VERSION ""

NS_ :

BS_:

BU_: DAS

BO_ 1337 DAS_info: 8 DAS
 SG_ DAS_infoIndex M : 0|8@1+ (1,0) [0|0] "" Vector__XXX
 SG_ DAS_infoBuildType m10 : 8|8@1+ (1,0) [0|0] "" Vector__XXX
 SG_ DAS_infoBuildConfigID m10 : 16|16@1+ (1,0) [0|0] "" Vector__XXX
 SG_ DAS_infoHardwareID m10 : 32|16@1+ (1,0) [0|0] "" Vector__XXX
 SG_ DAS_infoComponentID m10 : 48|16@1+ (1,0) [0|0] "" Vector__XXX
 SG_ DAS_infoPcbaID m11 : 16|8@1+ (1,0) [0|0] "" Vector__XXX
 SG_ DAS_infoAssemblyID m11 : 24|8@1+ (1,0) [0|255] "" Vector__XXX
 SG_ DAS_infoUsageID m11 : 32|16@1+ (1,0) [0|65535] "" Vector__XXX
 SG_ DAS_infoSubUsageID m11 : 48|16@1+ (1,0) [0|65535] "" Vector__XXX
 SG_ DAS_infoApplicationCRC m13 : 32|32@1+ (1,0) [0|0] "" Vector__XXX
 SG_ DAS_infoBootloaderSvnRevision m14 : 8|24@1+ (1,0) [0|0] "" Vector__XXX
 SG_ DAS_infoEyeQBootCRC m16 : 16|32@1+ (1,0) [0|0] "" Vector__XXX
 SG_ DAS_infoAppGitHashBytes m17 : 8|56@1+ (1,0) [0|0] "" Vector__XXX
 SG_ DAS_infoBootGitHashBytes m18 : 8|56@1+ (1,0) [0|0] "" Vector__XXX
 SG_ DAS_infoPlatformType m19 : 8|8@1+ (1,0) [0|0] "" Vector__XXX
 SG_ DAS_infoMajorVersion m19 : 16|8@1+ (1,0) [0|0] "" Vector__XXX
 SG_ DAS_infoBranchOrigin m19 : 24|8@1+ (1,0) [0|0] "" Vector__XXX
 SG_ DAS_infoMaturity m19 : 32|8@1+ (1,0) [0|0] "" Vector__XXX
 SG_ DAS_infoHardwareRevision m19 : 40|8@1+ (1,0) [0|0] "" Vector__XXX
 SG_ DAS_infoBootUdsProtoVersion m20 : 8|8@1+ (1,0) [0|0] "" Vector__XXX
 SG_ DAS_infoBootloaderCRC m20 : 32|32@1+ (1,0) [0|0] "" Vector__XXX
 SG_ DAS_infoEyeQAppCRC m23 : 16|32@1+ (1,0) [0|0] "" Vector__XXX
 SG_ DAS_infoEyeQFfsCRC m24 : 16|32@1+ (1,0) [0|0] "" Vector__XXX

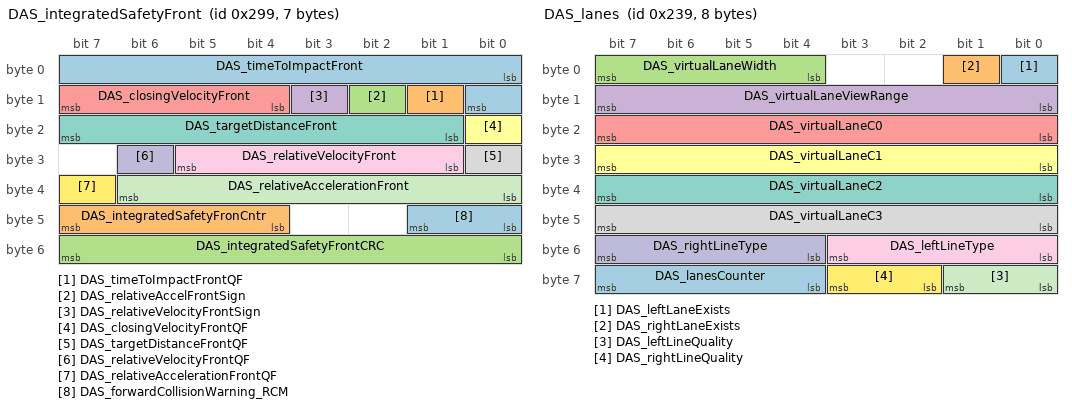
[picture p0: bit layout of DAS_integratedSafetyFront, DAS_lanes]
BO_ 665 DAS_integratedSafetyFront: 7 DAS
 SG_ DAS_timeToImpactFront : 0|9@1+ (1,0) [0|512] "ms" Vector__XXX
 SG_ DAS_timeToImpactFrontQF : 9|1@1+ (1,0) [0|3] "" Vector__XXX
 SG_ DAS_relativeAccelFrontSign : 10|1@1+ (1,0) [0|1] "" Vector__XXX
 SG_ DAS_relativeVelocityFrontSign : 11|1@1+ (1,0) [0|1] "" Vector__XXX
 SG_ DAS_closingVelocityFront : 12|4@1+ (1,0) [0|16] "m/s" Vector__XXX
 SG_ DAS_closingVelocityFrontQF : 16|1@1+ (1,0) [0|3] "" Vector__XXX
 SG_ DAS_targetDistanceFront : 17|7@1+ (0.1,0) [0|12.8] "m" Vector__XXX
 SG_ DAS_targetDistanceFrontQF : 24|1@1+ (1,0) [0|3] "" Vector__XXX
 SG_ DAS_relativeVelocityFront : 25|5@1+ (1,0) [0|32] "m/s" Vector__XXX
 SG_ DAS_relativeVelocityFrontQF : 30|1@1+ (1,0) [0|3] "" Vector__XXX
 SG_ DAS_relativeAccelerationFront : 32|7@1+ (0.1,0) [0|12.8] "m/s^2" Vector__XXX
 SG_ DAS_relativeAccelerationFrontQF : 39|1@1+ (1,0) [0|3] "" Vector__XXX
 SG_ DAS_forwardCollisionWarning_RCM : 40|2@1+ (1,0) [0|0] "" Vector__XXX
 SG_ DAS_integratedSafetyFronCntr : 44|4@1+ (1,0) [0|15] "" Vector__XXX
 SG_ DAS_integratedSafetyFrontCRC : 48|8@1+ (1,0) [0|255] "" Vector__XXX

BO_ 569 DAS_lanes: 8 DAS
 SG_ DAS_leftLaneExists : 0|1@1+ (1,0) [0|0] "" Vector__XXX
 SG_ DAS_rightLaneExists : 1|1@1+ (1,0) [0|0] "" Vector__XXX
 SG_ DAS_virtualLaneWidth : 4|4@1+ (0.3125,2) [2|7] "m" Vector__XXX
 SG_ DAS_virtualLaneViewRange : 8|8@1+ (1,0) [0|160] "m" Vector__XXX
 SG_ DAS_virtualLaneC0 : 16|8@1+ (0.035,-3.5) [-3.5|3.5] "m" Vector__XXX
 SG_ DAS_virtualLaneC1 : 24|8@1+ (0.0016,-0.2) [-0.2|0.2] "rad" Vector__XXX
 SG_ DAS_virtualLaneC2 : 32|8@1+ (2E-005,-0.0025) [-0.0025|0.0025] "m-1" Vector__XXX
 SG_ DAS_virtualLaneC3 : 40|8@1+ (2.4E-007,-3E-005) [-3E-005|3E-005] "m-2" Vector__XXX
 SG_ DAS_leftLineType : 48|4@1+ (1,0) [0|0] "" Vector__XXX
 SG_ DAS_rightLineType : 52|4@1+ (1,0) [0|0] "" Vector__XXX
 SG_ DAS_leftLineQuality : 56|2@1+ (1,0) [0|0] "" Vector__XXX
 SG_ DAS_rightLineQuality : 58|2@1+ (1,0) [0|0] "" Vector__XXX
 SG_ DAS_lanesCounter : 60|4@1+ (1,0) [0|0] "" Vector__XXX

BO_ 777 DAS_object: 8 DAS
 SG_ DAS_objectId M : 0|3@1+ (1,0) [0|7] "" Vector__XXX
 SG_ DAS_leadVehType m0 : 3|3@1+ (1,0) [0|7] "" Vector__XXX
 SG_ DAS_leadVehRelevantForControl m0 : 7|1@1+ (1,0) [0|1] "" Vector__XXX
 SG_ DAS_leadVehDx m0 : 8|8@1+ (0.5,0) [0|127] "m" Vector__XXX
 SG_ DAS_leadVehVxRel m0 : 16|4@1+ (4,-30) [-30|26] "m/s" Vector__XXX
 SG_ DAS_leadVehDy m0 : 20|7@1+ (0.2,-12.8) [-12.8|12.4] "m" Vector__XXX
 SG_ DAS_leadVehId m0 : 27|7@1+ (1,0) [0|126] "" Vector__XXX
 SG_ DAS_leadVeh2Type m0 : 34|3@1+ (1,0) [0|7] "" Vector__XXX
 SG_ DAS_leadVeh2RelevantForControl m0 : 38|1@1+ (1,0) [0|1] "" Vector__XXX
 SG_ DAS_leadVeh2Dx m0 : 39|8@1+ (0.5,0) [0|127] "m" Vector__XXX
 SG_ DAS_leadVeh2VxRel m0 : 47|4@1+ (4,-30) [-30|26] "m/s" Vector__XXX
 SG_ DAS_leadVeh2Dy m0 : 51|7@1+ (0.2,-12.8) [-12.8|12.4] "m" Vector__XXX
 SG_ DAS_leadVeh2Id m0 : 58|6@1+ (1,0) [0|63] "" Vector__XXX
 SG_ DAS_leftVehType m1 : 3|3@1+ (1,0) [0|7] "" Vector__XXX
 SG_ DAS_leftVehRelevantForControl m1 : 7|1@1+ (1,0) [0|1] "" Vector__XXX
 SG_ DAS_leftVehDx m1 : 8|8@1+ (0.5,0) [0|127] "m" Vector__XXX
 SG_ DAS_leftVehVxRel m1 : 16|4@1+ (4,-30) [-30|26] "m/s" Vector__XXX
 SG_ DAS_leftVehDy m1 : 20|7@1+ (0.2,-12.8) [-12.8|12.4] "m" Vector__XXX
 SG_ DAS_leftVehId m1 : 27|7@1+ (1,0) [0|126] "" Vector__XXX
 SG_ DAS_leftVeh2Type m1 : 34|3@1+ (1,0) [0|7] "" Vector__XXX
 SG_ DAS_leftVeh2RelevantForControl m1 : 38|1@1+ (1,0) [0|1] "" Vector__XXX
 SG_ DAS_leftVeh2Dx m1 : 39|8@1+ (0.5,0) [0|127] "m" Vector__XXX
 SG_ DAS_leftVeh2VxRel m1 : 47|4@1+ (4,-30) [-30|26] "m/s" Vector__XXX
 SG_ DAS_leftVeh2Dy m1 : 51|7@1+ (0.2,-12.8) [-12.8|12.4] "m" Vector__XXX
 SG_ DAS_leftVeh2Id m1 : 58|6@1+ (1,0) [0|63] "" Vector__XXX
 SG_ DAS_rightVehType m2 : 3|3@1+ (1,0) [0|7] "" Vector__XXX
 SG_ DAS_rightVehRelevantForControl m2 : 7|1@1+ (1,0) [0|1] "" Vector__XXX
 SG_ DAS_rightVehDx m2 : 8|8@1+ (0.5,0) [0|127] "m" Vector__XXX
 SG_ DAS_rightVehVxRel m2 : 16|4@1+ (4,-30) [-30|26] "m/s" Vector__XXX
 SG_ DAS_rightVehDy m2 : 20|7@1+ (0.2,-12.8) [-12.8|12.4] "m" Vector__XXX
 SG_ DAS_rightVehId m2 : 27|7@1+ (1,0) [0|126] "" Vector__XXX
 SG_ DAS_rightVeh2Type m2 : 34|3@1+ (1,0) [0|7] "" Vector__XXX
 SG_ DAS_rightVeh2RelevantForControl m2 : 38|1@1+ (1,0) [0|1] "" Vector__XXX
 SG_ DAS_rightVeh2Dx m2 : 39|8@1+ (0.5,0) [0|127] "m" Vector__XXX
 SG_ DAS_rightVeh2VxRel m2 : 47|4@1+ (4,-30) [-30|26] "m/s" Vector__XXX
 SG_ DAS_rightVeh2Dy m2 : 51|7@1+ (0.2,-12.8) [-12.8|12.4] "m" Vector__XXX
 SG_ DAS_rightVeh2Id m2 : 58|6@1+ (1,0) [0|63] "" Vector__XXX
 SG_ DAS_cutinVehType m3 : 3|3@1+ (1,0) [0|7] "" Vector__XXX
 SG_ DAS_cutinVehRelevantForControl m3 : 7|1@1+ (1,0) [0|1] "" Vector__XXX
 SG_ DAS_cutinVehDx m3 : 8|8@1+ (0.5,0) [0|127] "m" Vector__XXX
 SG_ DAS_cutinVehVxRel m3 : 16|4@1+ (4,-30) [-30|26] "m/s" Vector__XXX
 SG_ DAS_cutinVehDy m3 : 20|7@1+ (0.2,-12.8) [-12.8|12.4] "m" Vector__XXX
 SG_ DAS_cutinVehId m3 : 27|7@1+ (1,0) [0|126] "" Vector__XXX
 SG_ DAS_roadSignColor m4 : 3|3@1+ (1,0) [0|7] "" Vector__XXX
 SG_ DAS_roadSignId m4 : 6|8@1+ (1,0) [0|0] "" Vector__XXX
 SG_ DAS_roadSignStopLineDist m4 : 14|10@1+ (0.2,-20) [-20|184.4] "m" Vector__XXX
 SG_ DAS_roadSignControlActive m4 : 24|1@1+ (1,0) [0|1] "" Vector__XXX
 SG_ DAS_roadSignSource m4 : 25|2@1+ (1,0) [0|3] "" Vector__XXX
 SG_ DAS_roadSignArrow m4 : 27|3@1+ (1,0) [0|7] "" Vector__XXX
 SG_ DAS_roadSignOrientation m4 : 30|2@1+ (1,0) [0|1] "" Vector__XXX
 SG_ DAS_leadVehHeading m5 : 8|8@1+ (0.0245437,-3.1415936) [-3.1415936|3.0925062] "rad" Vector__XXX
 SG_ DAS_leadVeh2Heading m5 : 16|8@1+ (0.0245437,-3.1415936) [-3.1415936|3.0925062] "rad" Vector__XXX
 SG_ DAS_leftVehHeading m5 : 24|8@1+ (0.0245437,-3.1415936) [-3.1415936|3.0925062] "rad" Vector__XXX
 SG_ DAS_leftVeh2Heading m5 : 32|8@1+ (0.0245437,-3.1415936) [-3.1415936|3.0925062] "rad" Vector__XXX
 SG_ DAS_rightVehHeading m5 : 40|8@1+ (0.0245437,-3.1415936) [-3.1415936|3.0925062] "rad" Vector__XXX
 SG_ DAS_rightVeh2Heading m5 : 48|8@1+ (0.0245437,-3.1415936) [-3.1415936|3.0925062] "rad" Vector__XXX
 SG_ DAS_cutinVehHeading m5 : 56|8@1+ (0.0245437,-3.1415936) [-3.1415936|3.0925062] "rad" Vector__XXX

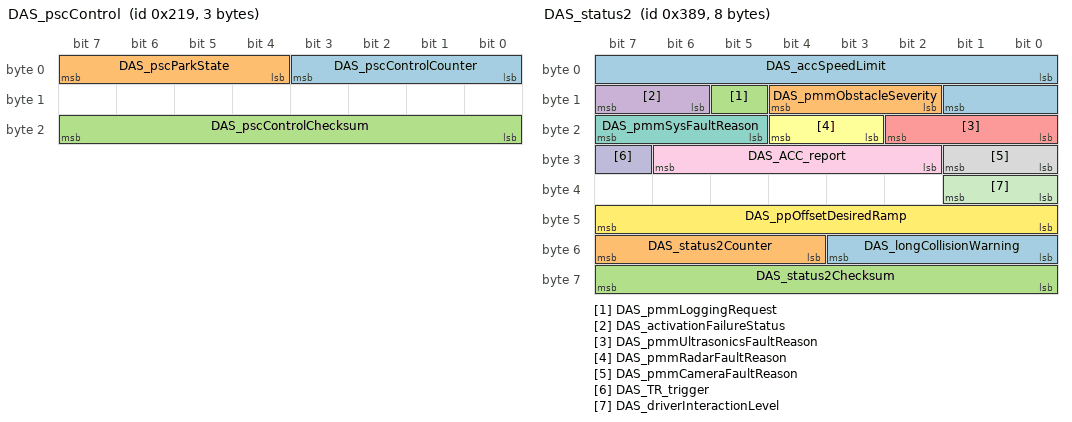
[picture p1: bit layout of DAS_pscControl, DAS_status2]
BO_ 537 DAS_pscControl: 3 DAS
 SG_ DAS_pscControlCounter : 0|4@1+ (1,0) [0|15] "" Vector__XXX
 SG_ DAS_pscParkState : 4|4@1+ (1,0) [0|15] "" Vector__XXX
 SG_ DAS_pscControlChecksum : 16|8@1+ (1,0) [0|255] "" Vector__XXX

BO_ 1025 DAS_robDebug: 8 DAS
 SG_ DAS_robDebugMultiplexer M : 0|4@1+ (1,0) [0|15] "" Vector__XXX
 SG_ DAS_eObj00Valid m0 : 4|1@1+ (1,0) [0|1] "" Vector__XXX
 SG_ DAS_eObj00Age m0 : 5|3@1+ (1,0) [0|7] "" Vector__XXX
 SG_ DAS_eObj00PositionX m0 : 8|8@1+ (0.5,0) [0|127.5] "m" Vector__XXX
 SG_ DAS_eObj00PositionY m0 : 16|8@1+ (0.25,-31.875) [-31.875|31.85] "m" Vector__XXX
 SG_ DAS_eObj00Moment0 m0 : 24|8@1+ (0.25,-31.875) [-31.875|31.85] "m" Vector__XXX
 SG_ DAS_eObj00Moment1 m0 : 32|8@1+ (0.25,-31.875) [-31.875|31.85] "m" Vector__XXX
 SG_ DAS_eObj00Moment2 m0 : 40|8@1+ (0.25,-31.875) [-31.875|31.85] "m" Vector__XXX
 SG_ DAS_eObj00Moment3 m0 : 48|8@1+ (0.25,-31.875) [-31.875|31.85] "m" Vector__XXX
 SG_ DAS_eObj00InPath m0 : 56|1@1+ (1,0) [0|1] "" Vector__XXX
 SG_ DAS_eObj00Blacklist m0 : 57|1@1+ (1,0) [0|1] "" Vector__XXX
 SG_ DAS_eObj00Elevated m0 : 58|1@1+ (1,0) [0|1] "" Vector__XXX
 SG_ DAS_eObj01Valid m1 : 4|1@1+ (1,0) [0|1] "" Vector__XXX
 SG_ DAS_eObj01Age m1 : 5|3@1+ (1,0) [0|7] "" Vector__XXX
 SG_ DAS_eObj01PositionX m1 : 8|8@1+ (0.5,0) [0|127.5] "m" Vector__XXX
 SG_ DAS_eObj01PositionY m1 : 16|8@1+ (0.25,-31.875) [-31.875|31.85] "m" Vector__XXX
 SG_ DAS_eObj01Moment0 m1 : 24|8@1+ (0.25,-31.875) [-31.875|31.85] "m" Vector__XXX
 SG_ DAS_eObj01Moment1 m1 : 32|8@1+ (0.25,-31.875) [-31.875|31.85] "m" Vector__XXX
 SG_ DAS_eObj01Moment2 m1 : 40|8@1+ (0.25,-31.875) [-31.875|31.85] "m" Vector__XXX
 SG_ DAS_eObj01Moment3 m1 : 48|8@1+ (0.25,-31.875) [-31.875|31.85] "m" Vector__XXX
 SG_ DAS_eObj01InPath m1 : 56|1@1+ (1,0) [0|1] "" Vector__XXX
 SG_ DAS_eObj01Blacklist m1 : 57|1@1+ (1,0) [0|1] "" Vector__XXX
 SG_ DAS_eObj01Elevated m1 : 58|1@1+ (1,0) [0|1] "" Vector__XXX
 SG_ DAS_eObj02Valid m2 : 4|1@1+ (1,0) [0|1] "" Vector__XXX
 SG_ DAS_eObj02Age m2 : 5|3@1+ (1,0) [0|7] "" Vector__XXX
 SG_ DAS_eObj02PositionX m2 : 8|8@1+ (0.5,0) [0|127.5] "m" Vector__XXX
 SG_ DAS_eObj02PositionY m2 : 16|8@1+ (0.25,-31.875) [-31.875|31.85] "m" Vector__XXX
 SG_ DAS_eObj02Moment0 m2 : 24|8@1+ (0.25,-31.875) [-31.875|31.85] "m" Vector__XXX
 SG_ DAS_eObj02Moment1 m2 : 32|8@1+ (0.25,-31.875) [-31.875|31.85] "m" Vector__XXX
 SG_ DAS_eObj02Moment2 m2 : 40|8@1+ (0.25,-31.875) [-31.875|31.85] "m" Vector__XXX
 SG_ DAS_eObj02Moment3 m2 : 48|8@1+ (0.25,-31.875) [-31.875|31.85] "m" Vector__XXX
 SG_ DAS_eObj02InPath m2 : 56|1@1+ (1,0) [0|1] "" Vector__XXX
 SG_ DAS_eObj02Blacklist m2 : 57|1@1+ (1,0) [0|1] "" Vector__XXX
 SG_ DAS_eObj02Elevated m2 : 58|1@1+ (1,0) [0|1] "" Vector__XXX
 SG_ DAS_eObj03Valid m3 : 4|1@1+ (1,0) [0|1] "" Vector__XXX
 SG_ DAS_eObj03Age m3 : 5|3@1+ (1,0) [0|7] "" Vector__XXX
 SG_ DAS_eObj03PositionX m3 : 8|8@1+ (0.5,0) [0|127.5] "m" Vector__XXX
 SG_ DAS_eObj03PositionY m3 : 16|8@1+ (0.25,-31.875) [-31.875|31.85] "m" Vector__XXX
 SG_ DAS_eObj03Moment0 m3 : 24|8@1+ (0.25,-31.875) [-31.875|31.85] "m" Vector__XXX
 SG_ DAS_eObj03Moment1 m3 : 32|8@1+ (0.25,-31.875) [-31.875|31.85] "m" Vector__XXX
 SG_ DAS_eObj03Moment2 m3 : 40|8@1+ (0.25,-31.875) [-31.875|31.85] "m" Vector__XXX
 SG_ DAS_eObj03Moment3 m3 : 48|8@1+ (0.25,-31.875) [-31.875|31.85] "m" Vector__XXX
 SG_ DAS_eObj03InPath m3 : 56|1@1+ (1,0) [0|1] "" Vector__XXX
 SG_ DAS_eObj03Blacklist m3 : 57|1@1+ (1,0) [0|1] "" Vector__XXX
 SG_ DAS_eObj03Elevated m3 : 58|1@1+ (1,0) [0|1] "" Vector__XXX
 SG_ DAS_robState m4 : 4|4@1+ (1,0) [0|15] "" Vector__XXX
 SG_ DAS_robPossibleCollision m4 : 8|1@1+ (1,0) [0|1] "" Vector__XXX
 SG_ DAS_robActiveBraking m4 : 9|1@1+ (1,0) [0|1] "" Vector__XXX
 SG_ DAS_robRequestEventRecorder m4 : 10|1@1+ (1,0) [0|1] "" Vector__XXX
 SG_ DAS_robInfrastructure m4 : 11|1@1+ (1,0) [0|1] "" Vector__XXX
 SG_ DAS_robAEBAlertLatch m4 : 12|1@1+ (1,0) [0|1] "" Vector__XXX
 SG_ DAS_robMapTrusted m4 : 13|1@1+ (1,0) [0|1] "" Vector__XXX
 SG_ DAS_robCollisionConf m4 : 16|4@1+ (1,0) [0|15] "" Vector__XXX
 SG_ DAS_robCriticalObjAge m4 : 20|4@1+ (1,0) [0|15] "" Vector__XXX
 SG_ DAS_robCriticalObjIndex m4 : 24|4@1+ (1,0) [0|15] "" Vector__XXX
 SG_ DAS_robDistanceObstacle m4 : 32|8@1+ (1,0) [0|255] "m" Vector__XXX
 SG_ DAS_robWidthObstacle m4 : 40|8@1+ (0.1,0) [0|25.5] "m" Vector__XXX
 SG_ DAS_robOverlapObstacle m4 : 48|8@1+ (0.1,0) [0|25.5] "m" Vector__XXX
 SG_ DAS_robTimeCollision m4 : 56|8@1+ (0.05,0) [0|12.75] "s" Vector__XXX
 SG_ DAS_robClusterStart m5 : 8|8@1+ (1,-95) [-95|160] "m" Vector__XXX
 SG_ DAS_robClusterEnd m5 : 16|8@1+ (1,0) [0|255] "m" Vector__XXX
 SG_ DAS_robMapTrust m5 : 24|1@1+ (1,0) [0|1] "" Vector__XXX
 SG_ DAS_robEnableBraking m5 : 25|1@1+ (1,0) [0|1] "" Vector__XXX
 SG_ DAS_robGPSHealthy m5 : 26|1@1+ (1,0) [0|1] "" Vector__XXX
 SG_ DAS_robRadarFault m5 : 27|1@1+ (1,0) [0|1] "" Vector__XXX
 SG_ DAS_robRadarBlind m5 : 28|1@1+ (1,0) [0|1] "" Vector__XXX
 SG_ DAS_robActiveLogging m5 : 29|1@1+ (1,0) [0|1] "" Vector__XXX

BO_ 921 DAS_status: 8 DAS
 SG_ DAS_autopilotState : 0|4@1+ (1,0) [0|0] "" Vector__XXX
 SG_ DAS_blindSpotRearLeft : 4|2@1+ (1,0) [0|0] "" Vector__XXX
 SG_ DAS_blindSpotRearRight : 6|2@1+ (1,0) [0|0] "" Vector__XXX
 SG_ DAS_fusedSpeedLimit : 8|5@1+ (5,0) [0|150] "kph/mph" Vector__XXX
 SG_ DAS_suppressSpeedWarning : 13|1@1+ (1,0) [0|0] "" Vector__XXX
 SG_ DAS_summonObstacle : 14|1@1+ (1,0) [0|0] "" Vector__XXX
 SG_ DAS_summonClearedGate : 15|1@1+ (1,0) [0|0] "" Vector__XXX
 SG_ DAS_visionOnlySpeedLimit : 16|5@1+ (5,0) [0|150] "kph/mph" Vector__XXX
 SG_ DAS_heaterState : 21|1@1+ (1,0) [0|0] "" Vector__XXX
 SG_ DAS_forwardCollisionWarning : 22|2@1+ (1,0) [0|0] "" Vector__XXX
 SG_ DAS_autoparkReady : 24|1@1+ (1,0) [0|1] "" Vector__XXX
 SG_ DAS_autoParked : 25|1@1+ (1,0) [0|0] "" Vector__XXX
 SG_ DAS_summonFwdLeashReached : 28|1@1+ (1,0) [0|1] "" Vector__XXX
 SG_ DAS_summonRvsLeashReached : 29|1@1+ (1,0) [0|1] "" Vector__XXX
 SG_ DAS_sideCollisionAvoid : 30|2@1+ (1,0) [0|0] "" Vector__XXX
 SG_ DAS_sideCollisionWarning : 32|2@1+ (1,0) [0|0] "" Vector__XXX
 SG_ DAS_sideCollisionInhibit : 34|1@1+ (1,0) [0|0] "" Vector__XXX
 SG_ DAS_csaState : 35|2@1+ (1,0) [0|0] "" Vector__XXX
 SG_ DAS_laneDepartureWarning : 37|3@1+ (1,0) [0|0] "" Vector__XXX
 SG_ DAS_autopilotHandsOnState : 42|4@1+ (1,0) [0|0] "" Vector__XXX
 SG_ DAS_autoLaneChangeState : 46|5@1+ (1,0) [0|0] "" Vector__XXX
 SG_ DAS_summonAvailable : 51|1@1+ (1,0) [0|1] "" Vector__XXX
 SG_ DAS_statusCounter : 52|4@1+ (1,0) [0|0] "" Vector__XXX
 SG_ DAS_statusChecksum : 56|8@1+ (1,0) [0|0] "" Vector__XXX

BO_ 905 DAS_status2: 8 DAS
 SG_ DAS_accSpeedLimit : 0|10@1+ (0.2,0) [0|204.6] "mph" Vector__XXX
 SG_ DAS_pmmObstacleSeverity : 10|3@1+ (1,0) [0|7] "" Vector__XXX
 SG_ DAS_pmmLoggingRequest : 13|1@1+ (1,0) [0|1] "" Vector__XXX
 SG_ DAS_activationFailureStatus : 14|2@1+ (1,0) [0|1] "" Vector__XXX
 SG_ DAS_pmmUltrasonicsFaultReason : 16|3@1+ (1,0) [0|7] "" Vector__XXX
 SG_ DAS_pmmRadarFaultReason : 19|2@1+ (1,0) [0|3] "" Vector__XXX
 SG_ DAS_pmmSysFaultReason : 21|3@1+ (1,0) [0|7] "" Vector__XXX
 SG_ DAS_pmmCameraFaultReason : 24|2@1+ (1,0) [0|3] "" Vector__XXX
 SG_ DAS_ACC_report : 26|5@1+ (1,0) [0|0] "" Vector__XXX
 SG_ DAS_TR_trigger : 31|1@1+ (1,0) [0|0] "" Vector__XXX
 SG_ DAS_driverInteractionLevel : 32|2@1+ (1,0) [0|3] "" Vector__XXX
 SG_ DAS_ppOffsetDesiredRamp : 40|8@1+ (0.01,-1.28) [-1.28|1.27] "m" Vector__XXX
 SG_ DAS_longCollisionWarning : 48|4@1+ (1,0) [0|15] "" Vector__XXX
 SG_ DAS_status2Counter : 52|4@1+ (1,0) [0|0] "" Vector__XXX
 SG_ DAS_status2Checksum : 56|8@1+ (1,0) [0|0] "" Vector__XXX

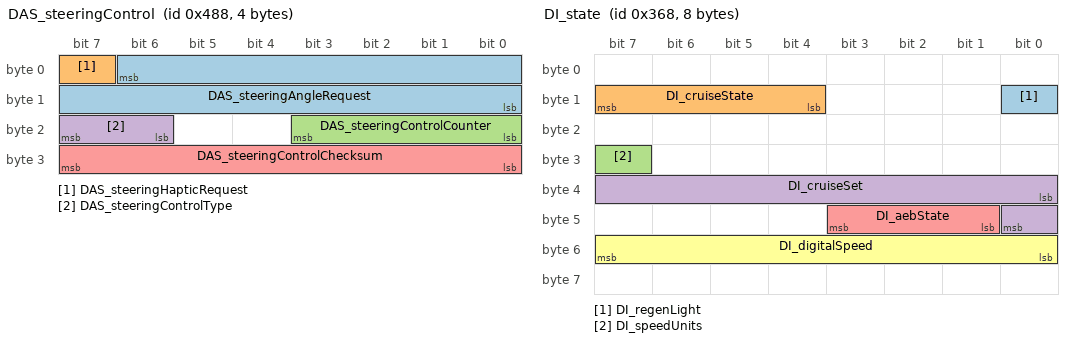
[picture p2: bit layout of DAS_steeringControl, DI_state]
BO_ 1160 DAS_steeringControl: 4 DAS
 SG_ DAS_steeringAngleRequest : 6|15@0+ (0.1,-1638.35) [-1638.35|1638.35] "deg" Vector__XXX
 SG_ DAS_steeringHapticRequest : 7|1@0+ (1,0) [0|0] "" Vector__XXX
 SG_ DAS_steeringControlCounter : 19|4@0+ (1,0) [0|0] "" Vector__XXX
 SG_ DAS_steeringControlType : 23|2@0+ (1,0) [0|0] "" Vector__XXX
 SG_ DAS_steeringControlChecksum : 31|8@0+ (1,0) [0|0] "" Vector__XXX

BO_ 937 DAS_telemetry: 8 DAS
 SG_ DAS_telemetryMultiplexer M : 0|8@1+ (1,0) [0|0] "" Vector__XXX
 SG_ DAS_telLeftLaneType m0 : 8|3@1+ (1,0) [0|0] "" Vector__XXX
 SG_ DAS_telRightLaneType m0 : 11|3@1+ (1,0) [0|0] "" Vector__XXX
 SG_ DAS_telLeftMarkerQuality m0 : 14|2@1+ (1,0) [0|0] "" Vector__XXX
 SG_ DAS_telRightMarkerQuality m0 : 16|2@1+ (1,0) [0|0] "" Vector__XXX
 SG_ DAS_telLeftMarkerColor m0 : 18|2@1+ (1,0) [0|0] "" Vector__XXX
 SG_ DAS_telRightMarkerColor m0 : 20|2@1+ (1,0) [0|0] "" Vector__XXX
 SG_ DAS_telLeftLaneCrossing m0 : 22|1@1+ (1,0) [0|0] "" Vector__XXX
 SG_ DAS_telRightLaneCrossing m0 : 23|1@1+ (1,0) [0|0] "" Vector__XXX
 SG_ DAS_MCPObserved m1 : 8|1@1+ (1,0) [0|1] "" Vector__XXX
 SG_ DAS_accReengaged m1 : 9|1@1+ (1,0) [0|1] "" Vector__XXX
 SG_ DAS_pedestrianInFOVBeforeIntr m1 : 10|1@1+ (1,0) [0|1] "" Vector__XXX
 SG_ DAS_pedestrianInFOVAfterIntr m1 : 11|1@1+ (1,0) [0|1] "" Vector__XXX
 SG_ DAS_camFreeSpaceBeforeIntr m1 : 12|1@1+ (1,0) [0|1] "" Vector__XXX
 SG_ DAS_camFreeSpaceAfterIntr m1 : 13|1@1+ (1,0) [0|1] "" Vector__XXX
 SG_ DAS_timeOfIntervention m1 : 14|6@1+ (0.25,0) [0|16] "s" Vector__XXX
 SG_ DAS_timeOfFirstPedestrian m1 : 20|6@1+ (0.25,0) [0|16] "s" Vector__XXX
 SG_ DAS_timeOfACCReengaging m1 : 26|6@1+ (0.25,0) [0|16] "s" Vector__XXX
 SG_ DAS_durationOfPrevACCStandstill m1 : 32|6@1+ (0.5,0) [0|30] "s" Vector__XXX
 SG_ DAS_maxAbsSteeringWheelAngle m1 : 38|7@1+ (2,0) [0|256] "degrees" Vector__XXX
 SG_ DAS_targetRelvelAtIntervention m1 : 45|6@1+ (0.25,-2) [-2|13.5] "m/s" Vector__XXX
 SG_ DAS_targetDistAtIntervention m1 : 51|6@1+ (0.5,0) [0|32] "m" Vector__XXX
 SG_ DAS_egoSpeedAtIntervention m1 : 57|6@1+ (0.5,0) [0|32] "m/s" Vector__XXX
 SG_ DAS_stopSignLongitudinalDist m2 : 8|10@1+ (0.1,0) [0|102.2] "m" Vector__XXX
 SG_ DAS_stopSignLateralDist m2 : 18|8@1+ (0.25,-32) [-32|31.5] "m" Vector__XXX
 SG_ DAS_stopSignHeight m2 : 26|6@1+ (0.1,0) [0|6.2] "m" Vector__XXX
 SG_ DAS_stopSignStopLineDistance m2 : 32|10@1+ (0.1,-20) [-20|82.2] "m" Vector__XXX
 SG_ DAS_stopSignCIPVDistance m2 : 42|6@1+ (0.5,0) [0|31.5] "m" Vector__XXX
 SG_ DAS_stopSignHostAccel m2 : 48|10@1+ (0.01,-5) [-5|5.23] "m/s^2" Vector__XXX
 SG_ DAS_stopSignCrossingWarning m2 : 58|1@1+ (1,0) [0|1] "" Vector__XXX
 SG_ DAS_stopSignIndex m2 : 59|4@1+ (1,0) [0|15] "" Vector__XXX
 SG_ DAS_csaOverride m7 : 10|1@1+ (1,0) [0|0] "" Vector__XXX
 SG_ DAS_csaIntState m7 : 11|3@1+ (1,0) [0|3] "" Vector__XXX
 SG_ DAS_csaEnableSpeed m7 : 14|12@1+ (0.05,-25) [-25|179.75] "MPH" Vector__XXX
 SG_ DAS_csaDisableSpeed m7 : 26|12@1+ (0.05,-25) [-25|179.75] "MPH" Vector__XXX
 SG_ DAS_csaFiltCurv m7 : 40|16@1- (1E-006,0) [-0.032768|0.032767] "1/m" Vector__XXX
 SG_ DAS_csaMeasLatAccel m7 : 56|8@1+ (0.08,-10.24) [-10.24|10] "m/s^2" Vector__XXX
 SG_ DAS_soCamCipvStatus m8 : 8|2@1+ (1,0) [0|3] "" Vector__XXX
 SG_ DAS_soRad5Status m8 : 10|2@1+ (1,0) [0|3] "" Vector__XXX
 SG_ DAS_soRad1Status m8 : 12|2@1+ (1,0) [0|3] "" Vector__XXX
 SG_ DAS_soCamCipvDx m8 : 14|6@1+ (2,0) [0|126] "m" Vector__XXX
 SG_ DAS_soRad1Dx m8 : 20|6@1+ (2,0) [0|126] "m" Vector__XXX
 SG_ DAS_soRad5Dx m8 : 26|6@1+ (2,0) [0|126] "m" Vector__XXX
 SG_ DAS_soCamCipvDy m8 : 32|5@1+ (0.4,-6.4) [-6.4|6] "m" Vector__XXX
 SG_ DAS_soRad5Dy m8 : 37|5@1+ (0.4,-6.4) [-6.4|6] "m" Vector__XXX
 SG_ DAS_soCamCipvVx m8 : 42|5@1+ (1,0) [0|31] "m/s" Vector__XXX
 SG_ DAS_soRad5ObstProb m8 : 47|4@1+ (0.0625,0) [0|0.9375] "probability" Vector__XXX
 SG_ DAS_soRad5Dz m8 : 51|6@1+ (0.25,-5) [-5|10.75] "m" Vector__XXX
 SG_ DAS_soRad5powerdB m8 : 57|7@1+ (2,0) [0|254] "dB" Vector__XXX
 SG_ DAS_assPrevSetSpeed m9 : 8|8@1+ (0.25,0) [0|63.75] "m/s" Vector__XXX
 SG_ DAS_assNewSetSpeed m9 : 16|8@1+ (0.25,0) [0|63.75] "m/s" Vector__XXX
 SG_ DAS_assFusedSpeedLimit m9 : 24|6@1+ (1,0) [0|63] "m/s" Vector__XXX
 SG_ DAS_assAutosteerActive m9 : 30|1@1+ (1,0) [0|1] "" Vector__XXX
 SG_ DAS_assSmartSpeedActive m9 : 31|1@1+ (2,0) [0|1] "" Vector__XXX

BO_ 985 DAS_telemetryEvent: 8 DAS
 SG_ DAS_TE_multiplexer M : 0|5@1+ (1,0) [0|0] "" Vector__XXX
 SG_ DAS_TE_counter m0 : 5|3@1+ (1,0) [0|0] "" Vector__XXX
 SG_ DAS_TE_eventID m0 : 8|16@1+ (1,0) [0|0] "" Vector__XXX
 SG_ DAS_TE_eventType m0 : 24|6@1+ (1,0) [0|0] "" Vector__XXX
 SG_ DAS_TE_lcAbortReason m0 : 32|5@1+ (1,0) [0|0] "" Vector__XXX
 SG_ DAS_TE_llCounter m1 : 5|3@1+ (1,0) [0|7] "" Vector__XXX
 SG_ DAS_TE_llC0 m1 : 8|10@1- (0.02,0) [-10.24|10.22] "m" Vector__XXX
 SG_ DAS_TE_llC1 m1 : 18|9@1- (0.001953125,0) [-0.5|0.498046875] "rad" Vector__XXX
 SG_ DAS_TE_llC2 m1 : 27|14@1- (4E-006,0) [-0.032768|0.032764] "1/m" Vector__XXX
 SG_ DAS_TE_llC3 m1 : 41|14@1- (1.6E-008,0) [-0.000131072|0.000131056] "1/m2" Vector__XXX
 SG_ DAS_TE_llQlty m1 : 55|1@1+ (1,0) [0|1] "" Vector__XXX
 SG_ DAS_TE_llRange m1 : 56|7@1+ (1,0) [0|127] "m" Vector__XXX
 SG_ DAS_TE_llFuse m1 : 63|1@1+ (1,0) [0|1] "" Vector__XXX
 SG_ DAS_TE_rlCounter m2 : 5|3@1+ (1,0) [0|7] "" Vector__XXX
 SG_ DAS_TE_rlC0 m2 : 8|10@1- (0.02,0) [-10.24|10.22] "m" Vector__XXX
 SG_ DAS_TE_rlC1 m2 : 18|9@1- (0.001953125,0) [-0.5|0.498046875] "rad" Vector__XXX
 SG_ DAS_TE_rlC2 m2 : 27|14@1- (4E-006,0) [-0.032768|0.032764] "1/m" Vector__XXX
 SG_ DAS_TE_rlC3 m2 : 41|14@1- (1.6E-008,0) [-0.000131072|0.000131056] "1/m2" Vector__XXX
 SG_ DAS_TE_rlQlty m2 : 55|1@1+ (1,0) [0|1] "" Vector__XXX
 SG_ DAS_TE_rlRange m2 : 56|7@1+ (1,0) [0|127] "m" Vector__XXX
 SG_ DAS_TE_rlFuse m2 : 63|1@1+ (1,0) [0|1] "" Vector__XXX
 SG_ DAS_TE_hppCounter m3 : 5|3@1+ (1,0) [0|7] "" Vector__XXX
 SG_ DAS_TE_hppC0 m3 : 8|10@1- (0.02,0) [-10.24|10.22] "m" Vector__XXX
 SG_ DAS_TE_hppC1 m3 : 18|9@1- (0.001953125,0) [-0.5|0.498046875] "rad" Vector__XXX
 SG_ DAS_TE_hppC2 m3 : 27|14@1- (4E-006,0) [-0.032768|0.032764] "1/m" Vector__XXX
 SG_ DAS_TE_hppC3 m3 : 41|14@1- (1.6E-008,0) [-0.000131072|0.000131056] "1/m2" Vector__XXX
 SG_ DAS_TE_hppQlty m3 : 55|1@1+ (1,0) [0|1] "" Vector__XXX
 SG_ DAS_TE_hppRange m3 : 56|7@1+ (1,0) [0|127] "m" Vector__XXX
 SG_ DAS_TE_hppFuse m3 : 63|1@1+ (1,0) [0|1] "" Vector__XXX
 SG_ DAS_TE_navCounter m4 : 5|3@1+ (1,0) [0|7] "" Vector__XXX
 SG_ DAS_TE_navC0 m4 : 8|10@1- (0.02,0) [-10.24|10.22] "m" Vector__XXX
 SG_ DAS_TE_navC1 m4 : 18|9@1- (0.001953125,0) [-0.5|0.498046875] "rad" Vector__XXX
 SG_ DAS_TE_navC2 m4 : 27|14@1- (4E-006,0) [-0.032768|0.032764] "1/m" Vector__XXX
 SG_ DAS_TE_navC3 m4 : 41|14@1- (1.6E-008,0) [-0.000131072|0.000131056] "1/m2" Vector__XXX
 SG_ DAS_TE_navQlty m4 : 55|1@1+ (1,0) [0|1] "" Vector__XXX
 SG_ DAS_TE_navRange m4 : 56|7@1+ (1,0) [0|127] "m" Vector__XXX
 SG_ DAS_TE_navFuse m4 : 63|1@1+ (1,0) [0|1] "" Vector__XXX
 SG_ DAS_TE_vlCounter m5 : 5|3@1+ (1,0) [0|7] "" Vector__XXX
 SG_ DAS_TE_vlC0 m5 : 8|10@1- (0.02,0) [-10.24|10.22] "m" Vector__XXX
 SG_ DAS_TE_vlC1 m5 : 18|9@1- (0.001953125,0) [-0.5|0.498046875] "rad" Vector__XXX
 SG_ DAS_TE_vlC2 m5 : 27|14@1- (4E-006,0) [-0.032768|0.032764] "1/m" Vector__XXX
 SG_ DAS_TE_vlC3 m5 : 41|14@1- (1.6E-008,0) [-0.000131072|0.000131056] "1/m2" Vector__XXX
 SG_ DAS_TE_vlQlty m5 : 55|1@1+ (1,0) [0|1] "" Vector__XXX
 SG_ DAS_TE_vlRange m5 : 56|7@1+ (1,0) [0|127] "m" Vector__XXX
 SG_ DAS_TE_vlFuse m5 : 63|1@1+ (1,0) [0|1] "" Vector__XXX
 SG_ DAS_TE_accCounter m6 : 5|3@1+ (1,0) [0|7] "" Vector__XXX
 SG_ DAS_TE_accTargetDx m6 : 8|6@1+ (2,0) [0|126] "m" Vector__XXX
 SG_ DAS_TE_accTargetDy m6 : 14|6@1+ (0.2,-6.4) [-6.4|6.2] "m" Vector__XXX
 SG_ DAS_TE_accTargetRelVel m6 : 20|7@1- (0.25,0) [-31.75|0] "m/s" Vector__XXX
 SG_ DAS_TE_accTargetRelA m6 : 27|5@1- (0.5,0) [-15.5|0] "m/s^2" Vector__XXX
 SG_ DAS_TE_accMinAccel m6 : 32|5@1- (0.5,0) [-15.5|0] "m/s^2" Vector__XXX
 SG_ DAS_TE_accMinJ m6 : 37|5@1- (0.5,0) [-15.5|0] "m/s^3" Vector__XXX
 SG_ DAS_TE_fcmCounter m7 : 5|3@1+ (1,0) [0|7] "" Vector__XXX
 SG_ DAS_TE_fcmTargetDx m7 : 8|8@1+ (0.25,0) [0|63.75] "m" Vector__XXX
 SG_ DAS_TE_fcmTargetDy m7 : 16|5@1+ (0.2,0) [-3.2|3] "m" Vector__XXX
 SG_ DAS_TE_fcmTargetVRel m7 : 21|7@1+ (0.25,-31.75) [-31.75|0] "m/s" Vector__XXX
 SG_ DAS_TE_fcmTargetAccel m7 : 28|5@1+ (0.5,-15.5) [-15.5|0] "m/s^2" Vector__XXX
 SG_ DAS_TE_fcmTargetProb m7 : 33|5@1+ (5,0) [0|160] "%" Vector__XXX
 SG_ DAS_TE_fcmDecelReqInstant m7 : 38|7@1- (0.1,0) [-12.7|0] "m/s^2" Vector__XXX
 SG_ DAS_TE_fcmDecelReqAeb m7 : 45|7@1- (0.1,0) [-12.7|0] "m/s^2" Vector__XXX
 SG_ DAS_TE_meAebFlag m7 : 52|1@1+ (1,0) [0|1] "" Vector__XXX
 SG_ DAS_TE_ipsoCounter m8 : 5|3@1+ (1,0) [0|7] "" Vector__XXX
 SG_ DAS_TE_ipsoValid m8 : 8|1@1+ (1,0) [0|1] "" Vector__XXX
 SG_ DAS_TE_ipsoConfidence m8 : 9|7@1+ (1,0) [0|127] "" Vector__XXX
 SG_ DAS_TE_ipsoDx m8 : 16|6@1+ (2,0) [0|126] "m" Vector__XXX
 SG_ DAS_TE_ipsoDy m8 : 22|6@1+ (0.1,-3.2) [-3.2|3.1] "m" Vector__XXX
 SG_ DAS_TE_vlDyAtIpsoDx m8 : 28|6@1+ (0.1,-3.2) [-3.2|3.1] "m" Vector__XXX
 SG_ DAS_TE_swaProjection m8 : 34|6@1+ (0.1,-3.2) [-3.2|3.1] "m" Vector__XXX
 SG_ DAS_TE_ipsoIsTarget1 m8 : 40|1@1+ (1,0) [0|1] "" Vector__XXX
 SG_ DAS_TE_ipsoIsTarget5 m8 : 41|1@1+ (1,0) [0|1] "" Vector__XXX
 SG_ DAS_TE_restrictedAccess m8 : 42|1@1+ (1,0) [0|1] "" Vector__XXX
 SG_ DAS_TE_csaOfframpValid m8 : 43|1@1+ (1,0) [0|1] "" Vector__XXX
 SG_ DAS_TE_accControlType m8 : 44|4@1+ (1,0) [0|7] "" Vector__XXX
 SG_ DAS_TE_brakeCapacityWarning m8 : 48|1@1+ (1,0) [0|1] "" Vector__XXX
 SG_ DAS_TE_emergencyBrake m8 : 49|1@1+ (1,0) [0|1] "" Vector__XXX
 SG_ DAS_TE_extendedAccLimits m8 : 50|1@1+ (1,0) [0|1] "" Vector__XXX
 SG_ DAS_TE_crashFront m8 : 51|1@1+ (1,0) [0|1] "" Vector__XXX
 SG_ DAS_TE_crashLeft m8 : 52|1@1+ (1,0) [0|1] "" Vector__XXX
 SG_ DAS_TE_crashRear m8 : 53|1@1+ (1,0) [0|1] "" Vector__XXX
 SG_ DAS_TE_crashRight m8 : 54|1@1+ (1,0) [0|1] "" Vector__XXX
 SG_ DAS_TE_crashRollover m8 : 55|1@1+ (1,0) [0|1] "" Vector__XXX
 SG_ DAS_TE_crashPedPro m8 : 56|1@1+ (1,0) [0|1] "" Vector__XXX
 SG_ DAS_TE_meIpsoValid m8 : 57|1@1+ (1,0) [0|1] "" Vector__XXX
 SG_ DAS_TE_robExceptionStart m9 : 16|8@1+ (1,-95) [-95|160] "m" Vector__XXX
 SG_ DAS_TE_robExceptionEnd m9 : 24|8@1+ (1,0) [0|255] "m" Vector__XXX
 SG_ DAS_TE_robDistanceEllipse m9 : 32|8@1+ (0.5,0) [0|127.5] "m" Vector__XXX
 SG_ DAS_TE_robEllipseOverlap m9 : 40|8@1+ (0.1,-12.5) [-12.5|12.5] "m" Vector__XXX
 SG_ DAS_TE_robEllipseAge m9 : 48|3@1+ (1,0) [0|7] "" Vector__XXX
 SG_ DAS_TE_robInfrastructure m9 : 51|1@1+ (1,0) [0|1] "" Vector__XXX
 SG_ DAS_TE_robTrustRadarMap m9 : 52|1@1+ (1,0) [0|1] "" Vector__XXX
 SG_ DAS_TE_robActiveBraking m9 : 53|1@1+ (1,0) [0|1] "" Vector__XXX

BO_ 945 DAS_telemetryFurniture: 8 DAS
 SG_ DAS_TF_multiplexer M : 0|5@1+ (1,0) [0|0] "" Vector__XXX
 SG_ DAS_TF_furnitureIndex0 m0 : 5|8@1+ (1,0) [0|255] "" Vector__XXX
 SG_ DAS_TF_distTraveled m0 : 13|11@1+ (0.1,0) [0|204.7] "m" Vector__XXX
 SG_ DAS_TF_llType m0 : 24|3@1+ (1,0) [0|7] "" Vector__XXX
 SG_ DAS_TF_rlType m0 : 27|3@1+ (1,0) [0|7] "" Vector__XXX
 SG_ DAS_TF_cipvDist m0 : 30|9@1+ (0.1,0) [0|51.1] "m" Vector__XXX
 SG_ DAS_TF_timeOfDay m0 : 39|3@1+ (1,0) [0|7] "" Vector__XXX
 SG_ DAS_TF_furnitureType m0 : 42|3@1+ (1,0) [0|7] "" Vector__XXX
 SG_ DAS_TF_furnitureIndex1 m1 : 5|8@1+ (1,0) [0|255] "" Vector__XXX
 SG_ DAS_TF_longitudinalDist m1 : 13|12@1+ (0.1,0) [0|409.5] "m" Vector__XXX
 SG_ DAS_TF_lateralDist m1 : 25|12@1+ (0.1,-204.8) [-204.8|204.7] "m" Vector__XXX
 SG_ DAS_TF_height m1 : 37|12@1+ (0.05,0) [0|204.75] "m" Vector__XXX
 SG_ DAS_TF_color m1 : 49|3@1+ (1,0) [0|7] "" Vector__XXX
 SG_ DAS_TF_shape m1 : 52|3@1+ (1,0) [0|7] "" Vector__XXX
 SG_ DAS_TF_orientation m1 : 55|2@1+ (1,0) [0|3] "" Vector__XXX
 SG_ DAS_TF_transmissionStatus m1 : 57|2@1+ (1,0) [0|3] "" Vector__XXX
 SG_ DAS_TF_isMain m1 : 59|1@1+ (1,0) [0|1] "" Vector__XXX
 SG_ DAS_TF_isTeslaMain m1 : 60|1@1+ (1,0) [0|1] "" Vector__XXX
 SG_ DAS_TF_furnitureIndex2 m2 : 5|8@1+ (1,0) [0|255] "" Vector__XXX
 SG_ DAS_TF_juncStatus m2 : 13|4@1+ (1,0) [0|7] "" Vector__XXX
 SG_ DAS_TF_juncDist m2 : 17|11@1+ (0.2,-20) [-20|389.4] "m" Vector__XXX
 SG_ DAS_TF_stopLineDist m2 : 28|11@1+ (0.1,-10) [-10|194.7] "m" Vector__XXX
 SG_ DAS_TF_ttc m2 : 39|7@1+ (0.1,0) [0|12.7] "s" Vector__XXX

BO_ 889 DAS_telemetryPeriodic: 8 DAS
 SG_ DAS_TP_multiplexer M : 0|5@1+ (1,0) [0|0] "" Vector__XXX
 SG_ DAS_TP_counter m0 : 5|3@1+ (1,0) [0|7] "" Vector__XXX
 SG_ DAS_TP_vlWidth m0 : 8|8@1+ (0.05,0) [0|12.75] "m" Vector__XXX
 SG_ DAS_TP_hppError m0 : 16|6@1+ (0.05,0) [0|3.15] "m" Vector__XXX
 SG_ DAS_TP_wipersActive m0 : 22|1@1+ (1,0) [0|1] "" Vector__XXX
 SG_ DAS_TP_handsOn m0 : 23|1@1+ (1,0) [0|1] "" Vector__XXX
 SG_ DAS_TP_sonicDistL m0 : 24|9@1+ (0.01,0) [0|5.11] "m" Vector__XXX
 SG_ DAS_TP_sonicDistR m0 : 33|9@1+ (0.01,0) [0|5.11] "m" Vector__XXX
 SG_ DAS_TP_hppValid m0 : 42|1@1+ (1,0) [0|1] "" Vector__XXX
 SG_ DAS_TP_restrictedAccess m0 : 43|1@1+ (1,0) [0|1] "" Vector__XXX
 SG_ DAS_TP_vehFuse m0 : 44|1@1+ (1,0) [0|1] "" Vector__XXX
 SG_ DAS_TP_accRestricted m0 : 46|1@1+ (1,0) [0|1] "" Vector__XXX
 SG_ DAS_TP_laneChange m0 : 48|2@1+ (1,0) [0|3] "" Vector__XXX
 SG_ DAS_TP_llType m0 : 50|3@1+ (1,0) [0|3] "" Vector__XXX
 SG_ DAS_TP_rlType m0 : 53|3@1+ (1,0) [0|3] "" Vector__XXX
 SG_ DAS_TP_plannerState m0 : 56|4@1+ (1,0) [0|15] "" Vector__XXX
 SG_ DAS_TP_lcState m0 : 60|4@1+ (1,0) [0|15] "" Vector__XXX
 SG_ DAS_TP_llCounter m1 : 5|3@1+ (1,0) [0|7] "" Vector__XXX
 SG_ DAS_TP_llC0 m1 : 8|10@1- (0.02,0) [-10.24|10.22] "m" Vector__XXX
 SG_ DAS_TP_llC1 m1 : 18|9@1- (0.001953125,0) [-0.5|0.498046875] "rad" Vector__XXX
 SG_ DAS_TP_llC2 m1 : 27|14@1- (4E-006,0) [-0.032768|0.032764] "1/m" Vector__XXX
 SG_ DAS_TP_llC3 m1 : 41|14@1- (1.6E-008,0) [-0.000131072|0.000131056] "1/m2" Vector__XXX
 SG_ DAS_TP_llQlty m1 : 55|1@1+ (1,0) [0|1] "" Vector__XXX
 SG_ DAS_TP_llRange m1 : 56|7@1+ (1,0) [0|127] "m" Vector__XXX
 SG_ DAS_TP_llFuse m1 : 63|1@1+ (1,0) [0|1] "" Vector__XXX
 SG_ DAS_TP_rlCounter m2 : 5|3@1+ (1,0) [0|7] "" Vector__XXX
 SG_ DAS_TP_rlC0 m2 : 8|10@1- (0.02,0) [-10.24|10.22] "m" Vector__XXX
 SG_ DAS_TP_rlC1 m2 : 18|9@1- (0.001953125,0) [-0.5|0.498046875] "rad" Vector__XXX
 SG_ DAS_TP_rlC2 m2 : 27|14@1- (4E-006,0) [-0.032768|0.032764] "1/m" Vector__XXX
 SG_ DAS_TP_rlC3 m2 : 41|14@1- (1.6E-008,0) [-0.000131072|0.000131056] "1/m2" Vector__XXX
 SG_ DAS_TP_rlQlty m2 : 55|1@1+ (1,0) [0|1] "" Vector__XXX
 SG_ DAS_TP_rlRange m2 : 56|7@1+ (1,0) [0|127] "m" Vector__XXX
 SG_ DAS_TP_rlFuse m2 : 63|1@1+ (1,0) [0|1] "" Vector__XXX
 SG_ DAS_TP_hppCounter m3 : 5|3@1+ (1,0) [0|7] "" Vector__XXX
 SG_ DAS_TP_hppC0 m3 : 8|10@1- (0.02,0) [-10.24|10.22] "m" Vector__XXX
 SG_ DAS_TP_hppC1 m3 : 18|9@1- (0.001953125,0) [-0.5|0.498046875] "rad" Vector__XXX
 SG_ DAS_TP_hppC2 m3 : 27|14@1- (4E-006,0) [-0.032768|0.032764] "1/m" Vector__XXX
 SG_ DAS_TP_hppC3 m3 : 41|14@1- (1.6E-008,0) [-0.000131072|0.000131056] "1/m2" Vector__XXX
 SG_ DAS_TP_hppQlty m3 : 55|1@1+ (1,0) [0|1] "" Vector__XXX
 SG_ DAS_TP_hppRange m3 : 56|7@1+ (1,0) [0|127] "m" Vector__XXX
 SG_ DAS_TP_hppFuse m3 : 63|1@1+ (1,0) [0|1] "" Vector__XXX
 SG_ DAS_TP_navCounter m4 : 5|3@1+ (1,0) [0|7] "" Vector__XXX
 SG_ DAS_TP_navC0 m4 : 8|10@1- (0.02,0) [-10.24|10.22] "m" Vector__XXX
 SG_ DAS_TP_navC1 m4 : 18|9@1- (0.001953125,0) [-0.5|0.498046875] "rad" Vector__XXX
 SG_ DAS_TP_navC2 m4 : 27|14@1- (4E-006,0) [-0.032768|0.032764] "1/m" Vector__XXX
 SG_ DAS_TP_navC3 m4 : 41|14@1- (1.6E-008,0) [-0.000131072|0.000131056] "1/m2" Vector__XXX
 SG_ DAS_TP_navQlty m4 : 55|1@1+ (1,0) [0|1] "" Vector__XXX
 SG_ DAS_TP_navRange m4 : 56|7@1+ (1,0) [0|127] "m" Vector__XXX
 SG_ DAS_TP_navFuse m4 : 63|1@1+ (1,0) [0|1] "" Vector__XXX
 SG_ DAS_TP_vlCounter m5 : 5|3@1+ (1,0) [0|7] "" Vector__XXX
 SG_ DAS_TP_vlC0 m5 : 8|10@1- (0.02,0) [-10.24|10.22] "m" Vector__XXX
 SG_ DAS_TP_vlC1 m5 : 18|9@1- (0.001953125,0) [-0.5|0.498046875] "rad" Vector__XXX
 SG_ DAS_TP_vlC2 m5 : 27|14@1- (4E-006,0) [-0.032768|0.032764] "1/m" Vector__XXX
 SG_ DAS_TP_vlC3 m5 : 41|14@1- (1.6E-008,0) [-0.000131072|0.000131056] "1/m2" Vector__XXX
 SG_ DAS_TP_vlQlty m5 : 55|1@1+ (1,0) [0|1] "" Vector__XXX
 SG_ DAS_TP_vlRange m5 : 56|7@1+ (1,0) [0|127] "m" Vector__XXX
 SG_ DAS_TP_vlFuse m5 : 63|1@1+ (1,0) [0|1] "" Vector__XXX
 SG_ DAS_TP_bdlCounter m6 : 5|3@1+ (1,0) [0|7] "" Vector__XXX
 SG_ DAS_TP_bdlC0 m6 : 8|10@1- (0.02,0) [-10.24|10.22] "m" Vector__XXX
 SG_ DAS_TP_bdlC1 m6 : 18|9@1- (0.001953125,0) [-0.5|0.498046875] "rad" Vector__XXX
 SG_ DAS_TP_bdlC2 m6 : 27|14@1- (4E-006,0) [-0.032768|0.032764] "1/m" Vector__XXX
 SG_ DAS_TP_bdlC3 m6 : 41|14@1- (1.6E-008,0) [-0.000131072|0.000131056] "1/m2" Vector__XXX
 SG_ DAS_TP_bdlQlty m6 : 55|1@1+ (1,0) [0|1] "" Vector__XXX
 SG_ DAS_TP_bdlRange m6 : 56|7@1+ (1,0) [0|127] "m" Vector__XXX
 SG_ DAS_TP_bdlFuse m6 : 63|1@1+ (1,0) [0|1] "" Vector__XXX
 SG_ DAS_TP_bdrCounter m7 : 5|3@1+ (1,0) [0|7] "" Vector__XXX
 SG_ DAS_TP_bdrC0 m7 : 8|10@1- (0.02,0) [-10.24|10.22] "m" Vector__XXX
 SG_ DAS_TP_bdrC1 m7 : 18|9@1- (0.001953125,0) [-0.5|0.498046875] "rad" Vector__XXX
 SG_ DAS_TP_bdrC2 m7 : 27|14@1- (4E-006,0) [-0.032768|0.032764] "1/m" Vector__XXX
 SG_ DAS_TP_bdrC3 m7 : 41|14@1- (1.6E-008,0) [-0.000131072|0.000131056] "1/m2" Vector__XXX
 SG_ DAS_TP_bdrQlty m7 : 55|1@1+ (1,0) [0|1] "" Vector__XXX
 SG_ DAS_TP_bdrRange m7 : 56|7@1+ (1,0) [0|127] "m" Vector__XXX
 SG_ DAS_TP_bdrFuse m7 : 63|1@1+ (1,0) [0|1] "" Vector__XXX
 SG_ DAS_TP_laneCounter m8 : 5|3@1+ (1,0) [0|7] "" Vector__XXX
 SG_ DAS_TP_llSegQ1 m8 : 8|4@1+ (10,0) [0|150] "%" Vector__XXX
 SG_ DAS_TP_llSegQ2 m8 : 12|4@1+ (10,0) [0|150] "%" Vector__XXX
 SG_ DAS_TP_llSegQ3 m8 : 16|4@1+ (10,0) [0|150] "%" Vector__XXX
 SG_ DAS_TP_llSegQ4 m8 : 20|4@1+ (10,0) [0|150] "%" Vector__XXX
 SG_ DAS_TP_rlSegQ1 m8 : 24|4@1+ (10,0) [0|150] "%" Vector__XXX
 SG_ DAS_TP_rlSegQ2 m8 : 28|4@1+ (10,0) [0|150] "%" Vector__XXX
 SG_ DAS_TP_rlSegQ3 m8 : 32|4@1+ (10,0) [0|150] "%" Vector__XXX
 SG_ DAS_TP_rlSegQ4 m8 : 36|4@1+ (10,0) [0|150] "%" Vector__XXX
 SG_ DAS_TP_llExist m8 : 40|4@1+ (10,0) [0|150] "%" Vector__XXX
 SG_ DAS_TP_rlExist m8 : 44|4@1+ (10,0) [0|150] "%" Vector__XXX
 SG_ DAS_TP_nllProb m8 : 48|4@1+ (0.1,0) [0|1.5] "1" Vector__XXX
 SG_ DAS_TP_nrlProb m8 : 52|4@1+ (0.1,0) [0|1.5] "1" Vector__XXX
 SG_ DAS_TP_llQltyME m8 : 56|2@1+ (1,0) [0|3] "" Vector__XXX
 SG_ DAS_TP_rlQltyME m8 : 58|2@1+ (1,0) [0|3] "" Vector__XXX
 SG_ DAS_TP_bdlQltyME m8 : 60|2@1+ (1,0) [0|3] "" Vector__XXX
 SG_ DAS_TP_bdrQltyME m8 : 62|2@1+ (1,0) [0|3] "" Vector__XXX
 SG_ DAS_TP_llrCounter m9 : 5|3@1+ (1,0) [0|7] "" Vector__XXX
 SG_ DAS_TP_numLanes m9 : 8|3@1+ (1,0) [0|7] "" Vector__XXX
 SG_ DAS_TP_lane1LLR m9 : 11|6@1+ (0.3125,-10) [-10|9.6875] "1" Vector__XXX
 SG_ DAS_TP_lane2LLR m9 : 17|6@1+ (0.3125,-10) [-10|9.6875] "1" Vector__XXX
 SG_ DAS_TP_lane3LLR m9 : 23|6@1+ (0.3125,-10) [-10|9.6875] "1" Vector__XXX
 SG_ DAS_TP_lane4LLR m9 : 29|6@1+ (0.3125,-10) [-10|9.6875] "1" Vector__XXX
 SG_ DAS_TP_lane5LLR m9 : 35|6@1+ (0.3125,-10) [-10|9.6875] "1" Vector__XXX
 SG_ DAS_TP_lane6LLR m9 : 41|6@1+ (0.3125,-10) [-10|9.6875] "1" Vector__XXX
 SG_ DAS_TP_lane7LLR m9 : 47|6@1+ (0.3125,-10) [-10|9.6875] "1" Vector__XXX
 SG_ DAS_TP_lane8LLR m9 : 53|6@1+ (0.3125,-10) [-10|9.6875] "1" Vector__XXX
 SG_ DAS_TP_egoLane m9 : 59|3@1+ (1,0) [0|7] "" Vector__XXX

BO_ 1545 DAS_telemetryRadar: 8 DAS
 SG_ DAS_TR_ObjIndex M : 0|5@1+ (1,0) [0|31] "" Vector__XXX
 SG_ DAS_TR_Counter : 54|2@1+ (1,0) [0|3] "" Vector__XXX
 SG_ DAS_TR_Obj00_Class m0 : 5|3@1+ (1,0) [0|7] "" Vector__XXX
 SG_ DAS_TR_Obj00_Dx m0 : 8|10@1+ (0.15625,0) [0|159.84375] "m" Vector__XXX
 SG_ DAS_TR_Obj00_Dy m0 : 18|6@1+ (0.5,-15.5) [-15.5|16] "m" Vector__XXX
 SG_ DAS_TR_Obj00_Vx m0 : 24|8@1+ (0.5,-63.5) [-63.5|64] "m/s" Vector__XXX
 SG_ DAS_TR_Obj00_RCS m0 : 32|8@1+ (0.25,-14) [-14|49.75] "dB" Vector__XXX
 SG_ DAS_TR_Obj00_Length m0 : 40|6@1+ (0.125,0) [0|7.875] "m" Vector__XXX
 SG_ DAS_TR_Obj00_MovingState m0 : 46|2@1+ (1,0) [0|3] "" Vector__XXX
 SG_ DAS_TR_Obj00_Dz m0 : 48|6@1+ (0.25,-5) [-5|10.75] "m" Vector__XXX
 SG_ DAS_TR_Obj00_Exist m0 : 56|5@1+ (3.125,0) [0|96.875] "%" Vector__XXX
 SG_ DAS_TR_Obj01_Class m1 : 5|3@1+ (1,0) [0|7] "" Vector__XXX
 SG_ DAS_TR_Obj01_Dx m1 : 8|10@1+ (0.15625,0) [0|159.84375] "m" Vector__XXX
 SG_ DAS_TR_Obj01_Dy m1 : 18|6@1+ (0.5,-15.5) [-15.5|16] "m" Vector__XXX
 SG_ DAS_TR_Obj01_Vx m1 : 24|8@1+ (0.5,-63.5) [-63.5|64] "m/s" Vector__XXX
 SG_ DAS_TR_Obj01_RCS m1 : 32|8@1+ (0.25,-14) [-14|49.75] "dB" Vector__XXX
 SG_ DAS_TR_Obj01_Length m1 : 40|6@1+ (0.125,0) [0|7.875] "m" Vector__XXX
 SG_ DAS_TR_Obj01_MovingState m1 : 46|2@1+ (1,0) [0|3] "" Vector__XXX
 SG_ DAS_TR_Obj01_Dz m1 : 48|6@1+ (0.25,-5) [-5|10.75] "m" Vector__XXX
 SG_ DAS_TR_Obj01_Exist m1 : 56|5@1+ (3.125,0) [0|96.875] "%" Vector__XXX
 SG_ DAS_TR_Obj02_Class m2 : 5|3@1+ (1,0) [0|7] "" Vector__XXX
 SG_ DAS_TR_Obj02_Dx m2 : 8|10@1+ (0.15625,0) [0|159.84375] "m" Vector__XXX
 SG_ DAS_TR_Obj02_Dy m2 : 18|6@1+ (0.5,-15.5) [-15.5|16] "m" Vector__XXX
 SG_ DAS_TR_Obj02_Vx m2 : 24|8@1+ (0.5,-63.5) [-63.5|64] "m/s" Vector__XXX
 SG_ DAS_TR_Obj02_RCS m2 : 32|8@1+ (0.25,-14) [-14|49.75] "dB" Vector__XXX
 SG_ DAS_TR_Obj02_Length m2 : 40|6@1+ (0.125,0) [0|7.875] "m" Vector__XXX
 SG_ DAS_TR_Obj02_MovingState m2 : 46|2@1+ (1,0) [0|3] "" Vector__XXX
 SG_ DAS_TR_Obj02_Dz m2 : 48|6@1+ (0.25,-5) [-5|10.75] "m" Vector__XXX
 SG_ DAS_TR_Obj02_Exist m2 : 56|5@1+ (3.125,0) [0|96.875] "%" Vector__XXX
 SG_ DAS_TR_Obj03_Class m3 : 5|3@1+ (1,0) [0|7] "" Vector__XXX
 SG_ DAS_TR_Obj03_Dx m3 : 8|10@1+ (0.15625,0) [0|159.84375] "m" Vector__XXX
 SG_ DAS_TR_Obj03_Dy m3 : 18|6@1+ (0.5,-15.5) [-15.5|16] "m" Vector__XXX
 SG_ DAS_TR_Obj03_Vx m3 : 24|8@1+ (0.5,-63.5) [-63.5|64] "m/s" Vector__XXX
 SG_ DAS_TR_Obj03_RCS m3 : 32|8@1+ (0.25,-14) [-14|49.75] "dB" Vector__XXX
 SG_ DAS_TR_Obj03_Length m3 : 40|6@1+ (0.125,0) [0|7.875] "m" Vector__XXX
 SG_ DAS_TR_Obj03_MovingState m3 : 46|2@1+ (1,0) [0|3] "" Vector__XXX
 SG_ DAS_TR_Obj03_Dz m3 : 48|6@1+ (0.25,-5) [-5|10.75] "m" Vector__XXX
 SG_ DAS_TR_Obj03_Exist m3 : 56|5@1+ (3.125,0) [0|96.875] "%" Vector__XXX
 SG_ DAS_TR_Obj04_Class m4 : 5|3@1+ (1,0) [0|7] "" Vector__XXX
 SG_ DAS_TR_Obj04_Dx m4 : 8|10@1+ (0.15625,0) [0|159.84375] "m" Vector__XXX
 SG_ DAS_TR_Obj04_Dy m4 : 18|6@1+ (0.5,-15.5) [-15.5|16] "m" Vector__XXX
 SG_ DAS_TR_Obj04_Vx m4 : 24|8@1+ (0.5,-63.5) [-63.5|64] "m/s" Vector__XXX
 SG_ DAS_TR_Obj04_RCS m4 : 32|8@1+ (0.25,-14) [-14|49.75] "dB" Vector__XXX
 SG_ DAS_TR_Obj04_Length m4 : 40|6@1+ (0.125,0) [0|7.875] "m" Vector__XXX
 SG_ DAS_TR_Obj04_MovingState m4 : 46|2@1+ (1,0) [0|3] "" Vector__XXX
 SG_ DAS_TR_Obj04_Dz m4 : 48|6@1+ (0.25,-5) [-5|10.75] "m" Vector__XXX
 SG_ DAS_TR_Obj04_Exist m4 : 56|5@1+ (3.125,0) [0|96.875] "%" Vector__XXX
 SG_ DAS_TR_Obj05_Class m5 : 5|3@1+ (1,0) [0|7] "" Vector__XXX
 SG_ DAS_TR_Obj05_Dx m5 : 8|10@1+ (0.15625,0) [0|159.84375] "m" Vector__XXX
 SG_ DAS_TR_Obj05_Dy m5 : 18|6@1+ (0.5,-15.5) [-15.5|16] "m" Vector__XXX
 SG_ DAS_TR_Obj05_Vx m5 : 24|8@1+ (0.5,-63.5) [-63.5|64] "m/s" Vector__XXX
 SG_ DAS_TR_Obj05_RCS m5 : 32|8@1+ (0.25,-14) [-14|49.75] "dB" Vector__XXX
 SG_ DAS_TR_Obj05_Length m5 : 40|6@1+ (0.125,0) [0|7.875] "m" Vector__XXX
 SG_ DAS_TR_Obj05_MovingState m5 : 46|2@1+ (1,0) [0|3] "" Vector__XXX
 SG_ DAS_TR_Obj05_Dz m5 : 48|6@1+ (0.25,-5) [-5|10.75] "m" Vector__XXX
 SG_ DAS_TR_Obj05_Exist m5 : 56|5@1+ (3.125,0) [0|96.875] "%" Vector__XXX
 SG_ DAS_TR_Obj06_Class m6 : 5|3@1+ (1,0) [0|7] "" Vector__XXX
 SG_ DAS_TR_Obj06_Dx m6 : 8|10@1+ (0.15625,0) [0|159.84375] "m" Vector__XXX
 SG_ DAS_TR_Obj06_Dy m6 : 18|6@1+ (0.5,-15.5) [-15.5|16] "m" Vector__XXX
 SG_ DAS_TR_Obj06_Vx m6 : 24|8@1+ (0.5,-63.5) [-63.5|64] "m/s" Vector__XXX
 SG_ DAS_TR_Obj06_RCS m6 : 32|8@1+ (0.25,-14) [-14|49.75] "dB" Vector__XXX
 SG_ DAS_TR_Obj06_Length m6 : 40|6@1+ (0.125,0) [0|7.875] "m" Vector__XXX
 SG_ DAS_TR_Obj06_MovingState m6 : 46|2@1+ (1,0) [0|3] "" Vector__XXX
 SG_ DAS_TR_Obj06_Dz m6 : 48|6@1+ (0.25,-5) [-5|10.75] "m" Vector__XXX
 SG_ DAS_TR_Obj06_Exist m6 : 56|5@1+ (3.125,0) [0|96.875] "%" Vector__XXX
 SG_ DAS_TR_Obj07_Class m7 : 5|3@1+ (1,0) [0|7] "" Vector__XXX
 SG_ DAS_TR_Obj07_Dx m7 : 8|10@1+ (0.15625,0) [0|159.84375] "m" Vector__XXX
 SG_ DAS_TR_Obj07_Dy m7 : 18|6@1+ (0.5,-15.5) [-15.5|16] "m" Vector__XXX
 SG_ DAS_TR_Obj07_Vx m7 : 24|8@1+ (0.5,-63.5) [-63.5|64] "m/s" Vector__XXX
 SG_ DAS_TR_Obj07_RCS m7 : 32|8@1+ (0.25,-14) [-14|49.75] "dB" Vector__XXX
 SG_ DAS_TR_Obj07_Length m7 : 40|6@1+ (0.125,0) [0|7.875] "m" Vector__XXX
 SG_ DAS_TR_Obj07_MovingState m7 : 46|2@1+ (1,0) [0|3] "" Vector__XXX
 SG_ DAS_TR_Obj07_Dz m7 : 48|6@1+ (0.25,-5) [-5|10.75] "m" Vector__XXX
 SG_ DAS_TR_Obj07_Exist m7 : 56|5@1+ (3.125,0) [0|96.875] "%" Vector__XXX
 SG_ DAS_TR_Obj08_Class m8 : 5|3@1+ (1,0) [0|7] "" Vector__XXX
 SG_ DAS_TR_Obj08_Dx m8 : 8|10@1+ (0.15625,0) [0|159.84375] "m" Vector__XXX
 SG_ DAS_TR_Obj08_Dy m8 : 18|6@1+ (0.5,-15.5) [-15.5|16] "m" Vector__XXX
 SG_ DAS_TR_Obj08_Vx m8 : 24|8@1+ (0.5,-63.5) [-63.5|64] "m/s" Vector__XXX
 SG_ DAS_TR_Obj08_RCS m8 : 32|8@1+ (0.25,-14) [-14|49.75] "dB" Vector__XXX
 SG_ DAS_TR_Obj08_Length m8 : 40|6@1+ (0.125,0) [0|7.875] "m" Vector__XXX
 SG_ DAS_TR_Obj08_MovingState m8 : 46|2@1+ (1,0) [0|3] "" Vector__XXX
 SG_ DAS_TR_Obj08_Dz m8 : 48|6@1+ (0.25,-5) [-5|10.75] "m" Vector__XXX
 SG_ DAS_TR_Obj08_Exist m8 : 56|5@1+ (3.125,0) [0|96.875] "%" Vector__XXX
 SG_ DAS_TR_Obj09_Class m9 : 5|3@1+ (1,0) [0|7] "" Vector__XXX
 SG_ DAS_TR_Obj09_Dx m9 : 8|10@1+ (0.15625,0) [0|159.84375] "m" Vector__XXX
 SG_ DAS_TR_Obj09_Dy m9 : 18|6@1+ (0.5,-15.5) [-15.5|16] "m" Vector__XXX
 SG_ DAS_TR_Obj09_Vx m9 : 24|8@1+ (0.5,-63.5) [-63.5|64] "m/s" Vector__XXX
 SG_ DAS_TR_Obj09_RCS m9 : 32|8@1+ (0.25,-14) [-14|49.75] "dB" Vector__XXX
 SG_ DAS_TR_Obj09_Length m9 : 40|6@1+ (0.125,0) [0|7.875] "m" Vector__XXX
 SG_ DAS_TR_Obj09_MovingState m9 : 46|2@1+ (1,0) [0|3] "" Vector__XXX
 SG_ DAS_TR_Obj09_Dz m9 : 48|6@1+ (0.25,-5) [-5|10.75] "m" Vector__XXX
 SG_ DAS_TR_Obj09_Exist m9 : 56|5@1+ (3.125,0) [0|96.875] "%" Vector__XXX
 SG_ DAS_TR_Obj10_Class m10 : 5|3@1+ (1,0) [0|7] "" Vector__XXX
 SG_ DAS_TR_Obj10_Dx m10 : 8|10@1+ (0.15625,0) [0|159.84375] "m" Vector__XXX
 SG_ DAS_TR_Obj10_Dy m10 : 18|6@1+ (0.5,-15.5) [-15.5|16] "m" Vector__XXX
 SG_ DAS_TR_Obj10_Vx m10 : 24|8@1+ (0.5,-63.5) [-63.5|64] "m/s" Vector__XXX
 SG_ DAS_TR_Obj10_RCS m10 : 32|8@1+ (0.25,-14) [-14|49.75] "dB" Vector__XXX
 SG_ DAS_TR_Obj10_Length m10 : 40|6@1+ (0.125,0) [0|7.875] "m" Vector__XXX
 SG_ DAS_TR_Obj10_MovingState m10 : 46|2@1+ (1,0) [0|3] "" Vector__XXX
 SG_ DAS_TR_Obj10_Dz m10 : 48|6@1+ (0.25,-5) [-5|10.75] "m" Vector__XXX
 SG_ DAS_TR_Obj10_Exist m10 : 56|5@1+ (3.125,0) [0|96.875] "%" Vector__XXX
 SG_ DAS_TR_Obj11_Class m11 : 5|3@1+ (1,0) [0|7] "" Vector__XXX
 SG_ DAS_TR_Obj11_Dx m11 : 8|10@1+ (0.15625,0) [0|159.84375] "m" Vector__XXX
 SG_ DAS_TR_Obj11_Dy m11 : 18|6@1+ (0.5,-15.5) [-15.5|16] "m" Vector__XXX
 SG_ DAS_TR_Obj11_Vx m11 : 24|8@1+ (0.5,-63.5) [-63.5|64] "m/s" Vector__XXX
 SG_ DAS_TR_Obj11_RCS m11 : 32|8@1+ (0.25,-14) [-14|49.75] "dB" Vector__XXX
 SG_ DAS_TR_Obj11_Length m11 : 40|6@1+ (0.125,0) [0|7.875] "m" Vector__XXX
 SG_ DAS_TR_Obj11_MovingState m11 : 46|2@1+ (1,0) [0|3] "" Vector__XXX
 SG_ DAS_TR_Obj11_Dz m11 : 48|6@1+ (0.25,-5) [-5|10.75] "m" Vector__XXX
 SG_ DAS_TR_Obj11_Exist m11 : 56|5@1+ (3.125,0) [0|96.875] "%" Vector__XXX
 SG_ DAS_TR_Obj12_Class m12 : 5|3@1+ (1,0) [0|7] "" Vector__XXX
 SG_ DAS_TR_Obj12_Dx m12 : 8|10@1+ (0.15625,0) [0|159.84375] "m" Vector__XXX
 SG_ DAS_TR_Obj12_Dy m12 : 18|6@1+ (0.5,-15.5) [-15.5|16] "m" Vector__XXX
 SG_ DAS_TR_Obj12_Vx m12 : 24|8@1+ (0.5,-63.5) [-63.5|64] "m/s" Vector__XXX
 SG_ DAS_TR_Obj12_RCS m12 : 32|8@1+ (0.25,-14) [-14|49.75] "dB" Vector__XXX
 SG_ DAS_TR_Obj12_Length m12 : 40|6@1+ (0.125,0) [0|7.875] "m" Vector__XXX
 SG_ DAS_TR_Obj12_MovingState m12 : 46|2@1+ (1,0) [0|3] "" Vector__XXX
 SG_ DAS_TR_Obj12_Dz m12 : 48|6@1+ (0.25,-5) [-5|10.75] "m" Vector__XXX
 SG_ DAS_TR_Obj12_Exist m12 : 56|5@1+ (3.125,0) [0|96.875] "%" Vector__XXX
 SG_ DAS_TR_Obj13_Class m13 : 5|3@1+ (1,0) [0|7] "" Vector__XXX
 SG_ DAS_TR_Obj13_Dx m13 : 8|10@1+ (0.15625,0) [0|159.84375] "m" Vector__XXX
 SG_ DAS_TR_Obj13_Dy m13 : 18|6@1+ (0.5,-15.5) [-15.5|16] "m" Vector__XXX
 SG_ DAS_TR_Obj13_Vx m13 : 24|8@1+ (0.5,-63.5) [-63.5|64] "m/s" Vector__XXX
 SG_ DAS_TR_Obj13_RCS m13 : 32|8@1+ (0.25,-14) [-14|49.75] "dB" Vector__XXX
 SG_ DAS_TR_Obj13_Length m13 : 40|6@1+ (0.125,0) [0|7.875] "m" Vector__XXX
 SG_ DAS_TR_Obj13_MovingState m13 : 46|2@1+ (1,0) [0|3] "" Vector__XXX
 SG_ DAS_TR_Obj13_Dz m13 : 48|6@1+ (0.25,-5) [-5|10.75] "m" Vector__XXX
 SG_ DAS_TR_Obj13_Exist m13 : 56|5@1+ (3.125,0) [0|96.875] "%" Vector__XXX
 SG_ DAS_TR_Obj14_Class m14 : 5|3@1+ (1,0) [0|7] "" Vector__XXX
 SG_ DAS_TR_Obj14_Dx m14 : 8|10@1+ (0.15625,0) [0|159.84375] "m" Vector__XXX
 SG_ DAS_TR_Obj14_Dy m14 : 18|6@1+ (0.5,-15.5) [-15.5|16] "m" Vector__XXX
 SG_ DAS_TR_Obj14_Vx m14 : 24|8@1+ (0.5,-63.5) [-63.5|64] "m/s" Vector__XXX
 SG_ DAS_TR_Obj14_RCS m14 : 32|8@1+ (0.25,-14) [-14|49.75] "dB" Vector__XXX
 SG_ DAS_TR_Obj14_Length m14 : 40|6@1+ (0.125,0) [0|7.875] "m" Vector__XXX
 SG_ DAS_TR_Obj14_MovingState m14 : 46|2@1+ (1,0) [0|3] "" Vector__XXX
 SG_ DAS_TR_Obj14_Dz m14 : 48|6@1+ (0.25,-5) [-5|10.75] "m" Vector__XXX
 SG_ DAS_TR_Obj14_Exist m14 : 56|5@1+ (3.125,0) [0|96.875] "%" Vector__XXX
 SG_ DAS_TR_Obj15_Class m15 : 5|3@1+ (1,0) [0|7] "" Vector__XXX
 SG_ DAS_TR_Obj15_Dx m15 : 8|10@1+ (0.15625,0) [0|159.84375] "m" Vector__XXX
 SG_ DAS_TR_Obj15_Dy m15 : 18|6@1+ (0.5,-15.5) [-15.5|16] "m" Vector__XXX
 SG_ DAS_TR_Obj15_Vx m15 : 24|8@1+ (0.5,-63.5) [-63.5|64] "m/s" Vector__XXX
 SG_ DAS_TR_Obj15_RCS m15 : 32|8@1+ (0.25,-14) [-14|49.75] "dB" Vector__XXX
 SG_ DAS_TR_Obj15_Length m15 : 40|6@1+ (0.125,0) [0|7.875] "m" Vector__XXX
 SG_ DAS_TR_Obj15_MovingState m15 : 46|2@1+ (1,0) [0|3] "" Vector__XXX
 SG_ DAS_TR_Obj15_Dz m15 : 48|6@1+ (0.25,-5) [-5|10.75] "m" Vector__XXX
 SG_ DAS_TR_Obj15_Exist m15 : 56|5@1+ (3.125,0) [0|96.875] "%" Vector__XXX
 SG_ DAS_TR_Obj16_Class m16 : 5|3@1+ (1,0) [0|7] "" Vector__XXX
 SG_ DAS_TR_Obj16_Dx m16 : 8|10@1+ (0.15625,0) [0|159.84375] "m" Vector__XXX
 SG_ DAS_TR_Obj16_Dy m16 : 18|6@1+ (0.5,-15.5) [-15.5|16] "m" Vector__XXX
 SG_ DAS_TR_Obj16_Vx m16 : 24|8@1+ (0.5,-63.5) [-63.5|64] "m/s" Vector__XXX
 SG_ DAS_TR_Obj16_RCS m16 : 32|8@1+ (0.25,-14) [-14|49.75] "dB" Vector__XXX
 SG_ DAS_TR_Obj16_Length m16 : 40|6@1+ (0.125,0) [0|7.875] "m" Vector__XXX
 SG_ DAS_TR_Obj16_MovingState m16 : 46|2@1+ (1,0) [0|3] "" Vector__XXX
 SG_ DAS_TR_Obj16_Dz m16 : 48|6@1+ (0.25,-5) [-5|10.75] "m" Vector__XXX
 SG_ DAS_TR_Obj16_Exist m16 : 56|5@1+ (3.125,0) [0|96.875] "%" Vector__XXX
 SG_ DAS_TR_Obj17_Class m17 : 5|3@1+ (1,0) [0|7] "" Vector__XXX
 SG_ DAS_TR_Obj17_Dx m17 : 8|10@1+ (0.15625,0) [0|159.84375] "m" Vector__XXX
 SG_ DAS_TR_Obj17_Dy m17 : 18|6@1+ (0.5,-15.5) [-15.5|16] "m" Vector__XXX
 SG_ DAS_TR_Obj17_Vx m17 : 24|8@1+ (0.5,-63.5) [-63.5|64] "m/s" Vector__XXX
 SG_ DAS_TR_Obj17_RCS m17 : 32|8@1+ (0.25,-14) [-14|49.75] "dB" Vector__XXX
 SG_ DAS_TR_Obj17_Length m17 : 40|6@1+ (0.125,0) [0|7.875] "m" Vector__XXX
 SG_ DAS_TR_Obj17_MovingState m17 : 46|2@1+ (1,0) [0|3] "" Vector__XXX
 SG_ DAS_TR_Obj17_Dz m17 : 48|6@1+ (0.25,-5) [-5|10.75] "m" Vector__XXX
 SG_ DAS_TR_Obj17_Exist m17 : 56|5@1+ (3.125,0) [0|96.875] "%" Vector__XXX
 SG_ DAS_TR_Obj18_Class m18 : 5|3@1+ (1,0) [0|7] "" Vector__XXX
 SG_ DAS_TR_Obj18_Dx m18 : 8|10@1+ (0.15625,0) [0|159.84375] "m" Vector__XXX
 SG_ DAS_TR_Obj18_Dy m18 : 18|6@1+ (0.5,-15.5) [-15.5|16] "m" Vector__XXX
 SG_ DAS_TR_Obj18_Vx m18 : 24|8@1+ (0.5,-63.5) [-63.5|64] "m/s" Vector__XXX
 SG_ DAS_TR_Obj18_RCS m18 : 32|8@1+ (0.25,-14) [-14|49.75] "dB" Vector__XXX
 SG_ DAS_TR_Obj18_Length m18 : 40|6@1+ (0.125,0) [0|7.875] "m" Vector__XXX
 SG_ DAS_TR_Obj18_MovingState m18 : 46|2@1+ (1,0) [0|3] "" Vector__XXX
 SG_ DAS_TR_Obj18_Dz m18 : 48|6@1+ (0.25,-5) [-5|10.75] "m" Vector__XXX
 SG_ DAS_TR_Obj18_Exist m18 : 56|5@1+ (3.125,0) [0|96.875] "%" Vector__XXX
 SG_ DAS_TR_Obj19_Class m19 : 5|3@1+ (1,0) [0|7] "" Vector__XXX
 SG_ DAS_TR_Obj19_Dx m19 : 8|10@1+ (0.15625,0) [0|159.84375] "m" Vector__XXX
 SG_ DAS_TR_Obj19_Dy m19 : 18|6@1+ (0.5,-15.5) [-15.5|16] "m" Vector__XXX
 SG_ DAS_TR_Obj19_Vx m19 : 24|8@1+ (0.5,-63.5) [-63.5|64] "m/s" Vector__XXX
 SG_ DAS_TR_Obj19_RCS m19 : 32|8@1+ (0.25,-14) [-14|49.75] "dB" Vector__XXX
 SG_ DAS_TR_Obj19_Length m19 : 40|6@1+ (0.125,0) [0|7.875] "m" Vector__XXX
 SG_ DAS_TR_Obj19_MovingState m19 : 46|2@1+ (1,0) [0|3] "" Vector__XXX
 SG_ DAS_TR_Obj19_Dz m19 : 48|6@1+ (0.25,-5) [-5|10.75] "m" Vector__XXX
 SG_ DAS_TR_Obj19_Exist m19 : 56|5@1+ (3.125,0) [0|96.875] "%" Vector__XXX
 SG_ DAS_TR_Obj20_Class m20 : 5|3@1+ (1,0) [0|7] "" Vector__XXX
 SG_ DAS_TR_Obj20_Dx m20 : 8|10@1+ (0.15625,0) [0|159.84375] "m" Vector__XXX
 SG_ DAS_TR_Obj20_Dy m20 : 18|6@1+ (0.5,-15.5) [-15.5|16] "m" Vector__XXX
 SG_ DAS_TR_Obj20_Vx m20 : 24|8@1+ (0.5,-63.5) [-63.5|64] "m/s" Vector__XXX
 SG_ DAS_TR_Obj20_RCS m20 : 32|8@1+ (0.25,-14) [-14|49.75] "dB" Vector__XXX
 SG_ DAS_TR_Obj20_Length m20 : 40|6@1+ (0.125,0) [0|7.875] "m" Vector__XXX
 SG_ DAS_TR_Obj20_MovingState m20 : 46|2@1+ (1,0) [0|3] "" Vector__XXX
 SG_ DAS_TR_Obj20_Dz m20 : 48|6@1+ (0.25,-5) [-5|10.75] "m" Vector__XXX
 SG_ DAS_TR_Obj20_Exist m20 : 56|5@1+ (3.125,0) [0|96.875] "%" Vector__XXX
 SG_ DAS_TR_Obj21_Class m21 : 5|3@1+ (1,0) [0|7] "" Vector__XXX
 SG_ DAS_TR_Obj21_Dx m21 : 8|10@1+ (0.15625,0) [0|159.84375] "m" Vector__XXX
 SG_ DAS_TR_Obj21_Dy m21 : 18|6@1+ (0.5,-15.5) [-15.5|16] "m" Vector__XXX
 SG_ DAS_TR_Obj21_Vx m21 : 24|8@1+ (0.5,-63.5) [-63.5|64] "m/s" Vector__XXX
 SG_ DAS_TR_Obj21_RCS m21 : 32|8@1+ (0.25,-14) [-14|49.75] "dB" Vector__XXX
 SG_ DAS_TR_Obj21_Length m21 : 40|6@1+ (0.125,0) [0|7.875] "m" Vector__XXX
 SG_ DAS_TR_Obj21_MovingState m21 : 46|2@1+ (1,0) [0|3] "" Vector__XXX
 SG_ DAS_TR_Obj21_Dz m21 : 48|6@1+ (0.25,-5) [-5|10.75] "m" Vector__XXX
 SG_ DAS_TR_Obj21_Exist m21 : 56|5@1+ (3.125,0) [0|96.875] "%" Vector__XXX
 SG_ DAS_TR_Obj22_Class m22 : 5|3@1+ (1,0) [0|7] "" Vector__XXX
 SG_ DAS_TR_Obj22_Dx m22 : 8|10@1+ (0.15625,0) [0|159.84375] "m" Vector__XXX
 SG_ DAS_TR_Obj22_Dy m22 : 18|6@1+ (0.5,-15.5) [-15.5|16] "m" Vector__XXX
 SG_ DAS_TR_Obj22_Vx m22 : 24|8@1+ (0.5,-63.5) [-63.5|64] "m/s" Vector__XXX
 SG_ DAS_TR_Obj22_RCS m22 : 32|8@1+ (0.25,-14) [-14|49.75] "dB" Vector__XXX
 SG_ DAS_TR_Obj22_Length m22 : 40|6@1+ (0.125,0) [0|7.875] "m" Vector__XXX
 SG_ DAS_TR_Obj22_MovingState m22 : 46|2@1+ (1,0) [0|3] "" Vector__XXX
 SG_ DAS_TR_Obj22_Dz m22 : 48|6@1+ (0.25,-5) [-5|10.75] "m" Vector__XXX
 SG_ DAS_TR_Obj22_Exist m22 : 56|5@1+ (3.125,0) [0|96.875] "%" Vector__XXX
 SG_ DAS_TR_Obj23_Class m23 : 5|3@1+ (1,0) [0|7] "" Vector__XXX
 SG_ DAS_TR_Obj23_Dx m23 : 8|10@1+ (0.15625,0) [0|159.84375] "m" Vector__XXX
 SG_ DAS_TR_Obj23_Dy m23 : 18|6@1+ (0.5,-15.5) [-15.5|16] "m" Vector__XXX
 SG_ DAS_TR_Obj23_Vx m23 : 24|8@1+ (0.5,-63.5) [-63.5|64] "m/s" Vector__XXX
 SG_ DAS_TR_Obj23_RCS m23 : 32|8@1+ (0.25,-14) [-14|49.75] "dB" Vector__XXX
 SG_ DAS_TR_Obj23_Length m23 : 40|6@1+ (0.125,0) [0|7.875] "m" Vector__XXX
 SG_ DAS_TR_Obj23_MovingState m23 : 46|2@1+ (1,0) [0|3] "" Vector__XXX
 SG_ DAS_TR_Obj23_Dz m23 : 48|6@1+ (0.25,-5) [-5|10.75] "m" Vector__XXX
 SG_ DAS_TR_Obj23_Exist m23 : 56|5@1+ (3.125,0) [0|96.875] "%" Vector__XXX
 SG_ DAS_TR_Obj24_Class m24 : 5|3@1+ (1,0) [0|7] "" Vector__XXX
 SG_ DAS_TR_Obj24_Dx m24 : 8|10@1+ (0.15625,0) [0|159.84375] "m" Vector__XXX
 SG_ DAS_TR_Obj24_Dy m24 : 18|6@1+ (0.5,-15.5) [-15.5|16] "m" Vector__XXX
 SG_ DAS_TR_Obj24_Vx m24 : 24|8@1+ (0.5,-63.5) [-63.5|64] "m/s" Vector__XXX
 SG_ DAS_TR_Obj24_RCS m24 : 32|8@1+ (0.25,-14) [-14|49.75] "dB" Vector__XXX
 SG_ DAS_TR_Obj24_Length m24 : 40|6@1+ (0.125,0) [0|7.875] "m" Vector__XXX
 SG_ DAS_TR_Obj24_MovingState m24 : 46|2@1+ (1,0) [0|3] "" Vector__XXX
 SG_ DAS_TR_Obj24_Dz m24 : 48|6@1+ (0.25,-5) [-5|10.75] "m" Vector__XXX
 SG_ DAS_TR_Obj24_Exist m24 : 56|5@1+ (3.125,0) [0|96.875] "%" Vector__XXX
 SG_ DAS_TR_Obj25_Class m25 : 5|3@1+ (1,0) [0|7] "" Vector__XXX
 SG_ DAS_TR_Obj25_Dx m25 : 8|10@1+ (0.15625,0) [0|159.84375] "m" Vector__XXX
 SG_ DAS_TR_Obj25_Dy m25 : 18|6@1+ (0.5,-15.5) [-15.5|16] "m" Vector__XXX
 SG_ DAS_TR_Obj25_Vx m25 : 24|8@1+ (0.5,-63.5) [-63.5|64] "m/s" Vector__XXX
 SG_ DAS_TR_Obj25_RCS m25 : 32|8@1+ (0.25,-14) [-14|49.75] "dB" Vector__XXX
 SG_ DAS_TR_Obj25_Length m25 : 40|6@1+ (0.125,0) [0|7.875] "m" Vector__XXX
 SG_ DAS_TR_Obj25_MovingState m25 : 46|2@1+ (1,0) [0|3] "" Vector__XXX
 SG_ DAS_TR_Obj25_Dz m25 : 48|6@1+ (0.25,-5) [-5|10.75] "m" Vector__XXX
 SG_ DAS_TR_Obj25_Exist m25 : 56|5@1+ (3.125,0) [0|96.875] "%" Vector__XXX
 SG_ DAS_TR_Obj26_Class m26 : 5|3@1+ (1,0) [0|7] "" Vector__XXX
 SG_ DAS_TR_Obj26_Dx m26 : 8|10@1+ (0.15625,0) [0|159.84375] "m" Vector__XXX
 SG_ DAS_TR_Obj26_Dy m26 : 18|6@1+ (0.5,-15.5) [-15.5|16] "m" Vector__XXX
 SG_ DAS_TR_Obj26_Vx m26 : 24|8@1+ (0.5,-63.5) [-63.5|64] "m/s" Vector__XXX
 SG_ DAS_TR_Obj26_RCS m26 : 32|8@1+ (0.25,-14) [-14|49.75] "dB" Vector__XXX
 SG_ DAS_TR_Obj26_Length m26 : 40|6@1+ (0.125,0) [0|7.875] "m" Vector__XXX
 SG_ DAS_TR_Obj26_MovingState m26 : 46|2@1+ (1,0) [0|3] "" Vector__XXX
 SG_ DAS_TR_Obj26_Dz m26 : 48|6@1+ (0.25,-5) [-5|10.75] "m" Vector__XXX
 SG_ DAS_TR_Obj26_Exist m26 : 56|5@1+ (3.125,0) [0|96.875] "%" Vector__XXX
 SG_ DAS_TR_Obj27_Class m27 : 5|3@1+ (1,0) [0|7] "" Vector__XXX
 SG_ DAS_TR_Obj27_Dx m27 : 8|10@1+ (0.15625,0) [0|159.84375] "m" Vector__XXX
 SG_ DAS_TR_Obj27_Dy m27 : 18|6@1+ (0.5,-15.5) [-15.5|16] "m" Vector__XXX
 SG_ DAS_TR_Obj27_Vx m27 : 24|8@1+ (0.5,-63.5) [-63.5|64] "m/s" Vector__XXX
 SG_ DAS_TR_Obj27_RCS m27 : 32|8@1+ (0.25,-14) [-14|49.75] "dB" Vector__XXX
 SG_ DAS_TR_Obj27_Length m27 : 40|6@1+ (0.125,0) [0|7.875] "m" Vector__XXX
 SG_ DAS_TR_Obj27_MovingState m27 : 46|2@1+ (1,0) [0|3] "" Vector__XXX
 SG_ DAS_TR_Obj27_Dz m27 : 48|6@1+ (0.25,-5) [-5|10.75] "m" Vector__XXX
 SG_ DAS_TR_Obj27_Exist m27 : 56|5@1+ (3.125,0) [0|96.875] "%" Vector__XXX
 SG_ DAS_TR_Obj28_Class m28 : 5|3@1+ (1,0) [0|7] "" Vector__XXX
 SG_ DAS_TR_Obj28_Dx m28 : 8|10@1+ (0.15625,0) [0|159.84375] "m" Vector__XXX
 SG_ DAS_TR_Obj28_Dy m28 : 18|6@1+ (0.5,-15.5) [-15.5|16] "m" Vector__XXX
 SG_ DAS_TR_Obj28_Vx m28 : 24|8@1+ (0.5,-63.5) [-63.5|64] "m/s" Vector__XXX
 SG_ DAS_TR_Obj28_RCS m28 : 32|8@1+ (0.25,-14) [-14|49.75] "dB" Vector__XXX
 SG_ DAS_TR_Obj28_Length m28 : 40|6@1+ (0.125,0) [0|7.875] "m" Vector__XXX
 SG_ DAS_TR_Obj28_MovingState m28 : 46|2@1+ (1,0) [0|3] "" Vector__XXX
 SG_ DAS_TR_Obj28_Dz m28 : 48|6@1+ (0.25,-5) [-5|10.75] "m" Vector__XXX
 SG_ DAS_TR_Obj28_Exist m28 : 56|5@1+ (3.125,0) [0|96.875] "%" Vector__XXX
 SG_ DAS_TR_Obj29_Class m29 : 5|3@1+ (1,0) [0|7] "" Vector__XXX
 SG_ DAS_TR_Obj29_Dx m29 : 8|10@1+ (0.15625,0) [0|159.84375] "m" Vector__XXX
 SG_ DAS_TR_Obj29_Dy m29 : 18|6@1+ (0.5,-15.5) [-15.5|16] "m" Vector__XXX
 SG_ DAS_TR_Obj29_Vx m29 : 24|8@1+ (0.5,-63.5) [-63.5|64] "m/s" Vector__XXX
 SG_ DAS_TR_Obj29_RCS m29 : 32|8@1+ (0.25,-14) [-14|49.75] "dB" Vector__XXX
 SG_ DAS_TR_Obj29_Length m29 : 40|6@1+ (0.125,0) [0|7.875] "m" Vector__XXX
 SG_ DAS_TR_Obj29_MovingState m29 : 46|2@1+ (1,0) [0|3] "" Vector__XXX
 SG_ DAS_TR_Obj29_Dz m29 : 48|6@1+ (0.25,-5) [-5|10.75] "m" Vector__XXX
 SG_ DAS_TR_Obj29_Exist m29 : 56|5@1+ (3.125,0) [0|96.875] "%" Vector__XXX
 SG_ DAS_TR_Obj30_Class m30 : 5|3@1+ (1,0) [0|7] "" Vector__XXX
 SG_ DAS_TR_Obj30_Dx m30 : 8|10@1+ (0.15625,0) [0|159.84375] "m" Vector__XXX
 SG_ DAS_TR_Obj30_Dy m30 : 18|6@1+ (0.5,-15.5) [-15.5|16] "m" Vector__XXX
 SG_ DAS_TR_Obj30_Vx m30 : 24|8@1+ (0.5,-63.5) [-63.5|64] "m/s" Vector__XXX
 SG_ DAS_TR_Obj30_RCS m30 : 32|8@1+ (0.25,-14) [-14|49.75] "dB" Vector__XXX
 SG_ DAS_TR_Obj30_Length m30 : 40|6@1+ (0.125,0) [0|7.875] "m" Vector__XXX
 SG_ DAS_TR_Obj30_MovingState m30 : 46|2@1+ (1,0) [0|3] "" Vector__XXX
 SG_ DAS_TR_Obj30_Dz m30 : 48|6@1+ (0.25,-5) [-5|10.75] "m" Vector__XXX
 SG_ DAS_TR_Obj30_Exist m30 : 56|5@1+ (3.125,0) [0|96.875] "%" Vector__XXX
 SG_ DAS_TR_Obj31_Class m31 : 5|3@1+ (1,0) [0|7] "" Vector__XXX
 SG_ DAS_TR_Obj31_Dx m31 : 8|10@1+ (0.15625,0) [0|159.84375] "m" Vector__XXX
 SG_ DAS_TR_Obj31_Dy m31 : 18|6@1+ (0.5,-15.5) [-15.5|16] "m" Vector__XXX
 SG_ DAS_TR_Obj31_Vx m31 : 24|8@1+ (0.5,-63.5) [-63.5|64] "m/s" Vector__XXX
 SG_ DAS_TR_Obj31_RCS m31 : 32|8@1+ (0.25,-14) [-14|49.75] "dB" Vector__XXX
 SG_ DAS_TR_Obj31_Length m31 : 40|6@1+ (0.125,0) [0|7.875] "m" Vector__XXX
 SG_ DAS_TR_Obj31_MovingState m31 : 46|2@1+ (1,0) [0|3] "" Vector__XXX
 SG_ DAS_TR_Obj31_Dz m31 : 48|6@1+ (0.25,-5) [-5|10.75] "m" Vector__XXX
 SG_ DAS_TR_Obj31_Exist m31 : 56|5@1+ (3.125,0) [0|96.875] "%" Vector__XXX

BO_ 1625 DAS_udsResponse: 8 DAS
 SG_ DAS_udsResponseData : 7|64@0+ (1,0) [0|0] "" Vector__XXX

BO_ 585 DAS_visualDebug: 8 DAS
 SG_ DAS_autosteerLeftLaneUsage : 0|2@1+ (1,0) [0|3] "" Vector__XXX
 SG_ DAS_autosteerRightLaneUsage : 2|2@1+ (1,0) [0|3] "" Vector__XXX
 SG_ DAS_autosteerVehiclesUsage : 4|2@1+ (1,0) [0|3] "" Vector__XXX
 SG_ DAS_autosteerHPPUsage : 6|2@1+ (1,0) [0|3] "" Vector__XXX
 SG_ DAS_autosteerNavigationUsage : 8|2@1+ (1,0) [0|3] "" Vector__XXX
 SG_ DAS_autosteerModelUsage : 10|2@1+ (1,0) [0|3] "" Vector__XXX
 SG_ DAS_autosteerBottsDotsUsage : 12|2@1+ (1,0) [0|3] "" Vector__XXX
 SG_ DAS_offsetSide : 14|2@1+ (1,0) [0|3] "" Vector__XXX
 SG_ DAS_roadSurfaceType : 16|2@1+ (1,0) [0|3] "" Vector__XXX
 SG_ DAS_autosteerHealthAnomalyLevel : 18|3@1+ (1,0) [0|5] "" Vector__XXX
 SG_ DAS_autosteerHealthState : 21|3@1+ (1,0) [0|5] "" Vector__XXX
 SG_ DAS_lastLinePreferenceReason : 24|4@1+ (1,0) [0|15] "" Vector__XXX
 SG_ DAS_plannerState : 28|4@1+ (1,0) [0|15] "" Vector__XXX
 SG_ DAS_lastAutosteerAbortReason : 32|5@1+ (1,0) [0|31] "" Vector__XXX
 SG_ DAS_devAppInterfaceEnabled : 37|1@1+ (1,0) [0|1] "" Vector__XXX
 SG_ DAS_accSmartSpeedActive : 48|1@1+ (1,0) [0|1] "" Vector__XXX
 SG_ DAS_accSmartSpeedState : 49|3@1+ (1,0) [0|7] "" Vector__XXX

BO_ 809 DAS_warningMatrix0: 8 DAS
 SG_ DAS_w002_ldwDisabled : 1|1@1+ (1,0) [0|1] "" Vector__XXX
 SG_ DAS_w003_isaDisabled : 2|1@1+ (1,0) [0|1] "" Vector__XXX
 SG_ DAS_w004_accDisabled : 3|1@1+ (1,0) [0|1] "" Vector__XXX
 SG_ DAS_w005_fcwCancelled : 4|1@1+ (1,0) [0|1] "" Vector__XXX
 SG_ DAS_w006_aebCancelled : 5|1@1+ (1,0) [0|1] "" Vector__XXX
 SG_ DAS_w007_ahlbDisabled : 6|1@1+ (1,0) [0|1] "" Vector__XXX
 SG_ DAS_w008_parkDisabled : 7|1@1+ (1,0) [0|1] "" Vector__XXX
 SG_ DAS_w009_aebFault : 8|1@1+ (1,0) [0|1] "" Vector__XXX
 SG_ DAS_w010_radcCalibIssue : 9|1@1+ (1,0) [0|0] "" Vector__XXX
 SG_ DAS_w011_scaEvent : 10|1@1+ (1,0) [0|0] "" Vector__XXX
 SG_ DAS_w012_Cam_BootFailure : 11|1@1+ (1,0) [0|0] "" Vector__XXX
 SG_ DAS_w013_Cam_Watchdog : 12|1@1+ (1,0) [0|0] "" Vector__XXX
 SG_ DAS_w014_swAssert : 13|1@1+ (1,0) [0|0] "" Vector__XXX
 SG_ DAS_w015_Camera_Failsafes : 14|1@1+ (1,0) [0|0] "" Vector__XXX
 SG_ DAS_w016_aeb_e_event : 15|1@1+ (1,0) [0|0] "" Vector__XXX
 SG_ DAS_w017_Cam_Msg_MIA : 16|1@1+ (1,0) [0|0] "" Vector__XXX
 SG_ DAS_w018_ECU_Power_Issue : 17|1@1+ (1,0) [0|0] "" Vector__XXX
 SG_ DAS_w019_ECU_Stack_Overflow : 18|1@1+ (1,0) [0|0] "" Vector__XXX
 SG_ DAS_w020_ECU_checkstopError : 19|1@1+ (1,0) [0|0] "" Vector__XXX
 SG_ DAS_w021_ECU_Temperature_Issue : 20|1@1+ (1,0) [0|0] "" Vector__XXX
 SG_ DAS_w022_ECU_EEPROM_Failure : 21|1@1+ (1,0) [0|0] "" Vector__XXX
 SG_ DAS_w023_ECU_Cam_Statemismatc : 22|1@1+ (1,0) [0|0] "" Vector__XXX
 SG_ DAS_w024_ECU_Watchdog_Reset : 23|1@1+ (1,0) [0|0] "" Vector__XXX
 SG_ DAS_w025_LC_Steering_Override : 24|1@1+ (1,0) [0|0] "" Vector__XXX
 SG_ DAS_w026_ECU_timingIssue : 25|1@1+ (1,0) [0|0] "" Vector__XXX
 SG_ DAS_w027_ECU_Reset_Fault : 26|1@1+ (1,0) [0|0] "" Vector__XXX
 SG_ DAS_w028_spi_rx_error : 27|1@1+ (1,0) [0|0] "" Vector__XXX
 SG_ DAS_w029_spi_tx_error : 28|1@1+ (1,0) [0|0] "" Vector__XXX
 SG_ DAS_w030_Heater_Issue : 29|1@1+ (1,0) [0|0] "" Vector__XXX
 SG_ DAS_w031_canRxError : 30|1@1+ (1,0) [0|0] "" Vector__XXX
 SG_ DAS_w032_canTxError : 31|1@1+ (1,0) [0|0] "" Vector__XXX
 SG_ DAS_w033_gtwMia : 32|1@1+ (1,0) [0|0] "" Vector__XXX
 SG_ DAS_w034_sccmMia : 33|1@1+ (1,0) [0|0] "" Vector__XXX
 SG_ DAS_w035_espMia : 34|1@1+ (1,0) [0|0] "" Vector__XXX
 SG_ DAS_w036_bdyMia : 35|1@1+ (1,0) [0|0] "" Vector__XXX
 SG_ DAS_w037_camTacIssue : 36|1@1+ (1,0) [0|0] "" Vector__XXX
 SG_ DAS_w038_camFailure : 37|1@1+ (1,0) [0|0] "" Vector__XXX
 SG_ DAS_w039_sdm_rcm_Mia : 38|1@1+ (1,0) [0|0] "" Vector__XXX
 SG_ DAS_w040_autopilotAngleSaturated : 39|1@1+ (1,0) [0|0] "" Vector__XXX
 SG_ DAS_w041_autopilotRateSaturated : 40|1@1+ (1,0) [0|0] "" Vector__XXX
 SG_ DAS_w042_autopilotAborting : 41|1@1+ (1,0) [0|1] "" Vector__XXX
 SG_ DAS_w043_camLongRunTime : 42|1@1+ (1,0) [0|1] "" Vector__XXX
 SG_ DAS_w044_appMobileyeFailure : 43|1@1+ (1,0) [0|0] "" Vector__XXX
 SG_ DAS_w045_radMia : 44|1@1+ (1,0) [0|0] "" Vector__XXX
 SG_ DAS_w046_eepromRecordAbsent : 45|1@1+ (1,0) [0|1] "" Vector__XXX
 SG_ DAS_w047_edrEvent : 46|1@1+ (1,0) [0|0] "" Vector__XXX
 SG_ DAS_w048_DAS_Features_Disabled : 47|1@1+ (1,0) [0|0] "" Vector__XXX
 SG_ DAS_w049_eyeqVersionMismatch : 48|1@1+ (1,0) [0|1] "" Vector__XXX
 SG_ DAS_w050_aeb_event : 49|1@1+ (1,0) [0|1] "" Vector__XXX
 SG_ DAS_w051_radcEcuIssue : 50|1@1+ (1,0) [0|1] "" Vector__XXX
 SG_ DAS_w052_radcSensorIssue : 51|1@1+ (1,0) [0|1] "" Vector__XXX
 SG_ DAS_w053_radcCommIssue : 52|1@1+ (1,0) [0|1] "" Vector__XXX
 SG_ DAS_w054_camAutofix : 53|1@1+ (1,0) [0|1] "" Vector__XXX
 SG_ DAS_w055_radcVersionMismatch : 54|1@1+ (1,0) [0|1] "" Vector__XXX
 SG_ DAS_w056_diMia : 55|1@1+ (1,0) [0|1] "" Vector__XXX
 SG_ DAS_w057_mcuMia : 56|1@1+ (1,0) [0|1] "" Vector__XXX
 SG_ DAS_w058_epbMia : 57|1@1+ (1,0) [0|1] "" Vector__XXX
 SG_ DAS_w059_parkMia : 58|1@1+ (1,0) [0|1] "" Vector__XXX
 SG_ DAS_w060_fcw_event : 59|1@1+ (1,0) [0|1] "" Vector__XXX
 SG_ DAS_w061_airSuspensionMia : 60|1@1+ (1,0) [0|1] "" Vector__XXX
 SG_ DAS_w062_radcAlignment : 61|1@1+ (1,0) [0|1] "" Vector__XXX
 SG_ DAS_w063_parkVersionMismatch : 62|1@1+ (1,0) [0|1] "" Vector__XXX
 SG_ DAS_w064_epasMia : 63|1@1+ (1,0) [0|1] "" Vector__XXX

BO_ 873 DAS_warningMatrix1: 8 DAS
 SG_ DAS_w065_deserializerOvercurrent : 0|1@1+ (1,0) [0|1] "" Vector__XXX
 SG_ DAS_w066_deserializerLockLost : 1|1@1+ (1,0) [0|1] "" Vector__XXX
 SG_ DAS_w067_steeringAlignment : 2|1@1+ (1,0) [0|1] "" Vector__XXX
 SG_ DAS_w068_vlInconsistency : 3|1@1+ (1,0) [0|1] "" Vector__XXX
 SG_ DAS_w069_apcSpaceMasked : 4|1@1+ (1,0) [0|1] "" Vector__XXX
 SG_ DAS_w070_apcIncompleteCal : 5|1@1+ (1,0) [0|1] "" Vector__XXX
 SG_ DAS_w071_selfparkStarted : 6|1@1+ (1,0) [0|1] "" Vector__XXX
 SG_ DAS_w072_selfparkComplete : 7|1@1+ (1,0) [0|1] "" Vector__XXX
 SG_ DAS_w073_issueEscalatedLDW : 8|1@1+ (1,0) [0|1] "" Vector__XXX
 SG_ DAS_w074_inPathStationaryObst : 9|1@1+ (1,0) [0|1] "" Vector__XXX
 SG_ DAS_w075_scMia : 10|1@1+ (1,0) [0|1] "" Vector__XXX
 SG_ DAS_w076_mobilEyeSetC : 11|1@1+ (1,0) [0|1] "" Vector__XXX
 SG_ DAS_w077_pmmActive : 12|1@1+ (1,0) [0|1] "" Vector__XXX
 SG_ DAS_w078_pmmActive2 : 13|1@1+ (1,0) [0|1] "" Vector__XXX
 SG_ DAS_w079_edrAvailable : 14|1@1+ (1,0) [0|1] "" Vector__XXX
 SG_ DAS_w080_accFailedActivation : 15|1@1+ (1,0) [0|1] "" Vector__XXX
 SG_ DAS_w081_pmmActiveBraking : 16|1@1+ (1,0) [0|1] "" Vector__XXX
 SG_ DAS_w082_inPathFSviolation : 17|1@1+ (1,0) [0|1] "" Vector__XXX
 SG_ DAS_w083_inPathRADObject : 18|1@1+ (1,0) [0|1] "" Vector__XXX
 SG_ DAS_w084_pmmIPSO : 19|1@1+ (1,0) [0|1] "" Vector__XXX
 SG_ DAS_w085_pmmSteering : 20|1@1+ (1,0) [0|1] "" Vector__XXX
 SG_ DAS_w086_robCollision : 21|1@1+ (1,0) [0|1] "" Vector__XXX
 SG_ DAS_w087_DEPRECATED : 22|1@1+ (1,0) [0|1] "" Vector__XXX
 SG_ DAS_w088_DEPRECATED : 23|1@1+ (1,0) [0|1] "" Vector__XXX
 SG_ DAS_w089_DEPRECATED : 24|1@1+ (1,0) [0|1] "" Vector__XXX
 SG_ DAS_w090_DEPRECATED : 25|1@1+ (1,0) [0|1] "" Vector__XXX
 SG_ DAS_w091_DEPRECATED : 26|1@1+ (1,0) [0|1] "" Vector__XXX
 SG_ DAS_w092_DEPRECATED : 27|1@1+ (1,0) [0|1] "" Vector__XXX
 SG_ DAS_w093_DEPRECATED : 28|1@1+ (1,0) [0|1] "" Vector__XXX
 SG_ DAS_w094_DEPRECATED : 29|1@1+ (1,0) [0|1] "" Vector__XXX
 SG_ DAS_w095_DEPRECATED : 30|1@1+ (1,0) [0|1] "" Vector__XXX
 SG_ DAS_w096_DEPRECATED : 31|1@1+ (1,0) [0|1] "" Vector__XXX
 SG_ DAS_w097_DEPRECATED : 32|1@1+ (1,0) [0|1] "" Vector__XXX
 SG_ DAS_w098_DEPRECATED : 33|1@1+ (1,0) [0|1] "" Vector__XXX
 SG_ DAS_w099_DEPRECATED : 34|1@1+ (1,0) [0|1] "" Vector__XXX
 SG_ DAS_w100_DEPRECATED : 35|1@1+ (1,0) [0|1] "" Vector__XXX
 SG_ DAS_w101_DEPRECATED : 36|1@1+ (1,0) [0|1] "" Vector__XXX
 SG_ DAS_w102_DEPRECATED : 37|1@1+ (1,0) [0|1] "" Vector__XXX
 SG_ DAS_w103_robExperimentalAEB : 38|1@1+ (1,0) [0|1] "" Vector__XXX
 SG_ DAS_w104_DEPRECATED : 39|1@1+ (1,0) [0|1] "" Vector__XXX
 SG_ DAS_w105_DEPRECATED : 40|1@1+ (1,0) [0|1] "" Vector__XXX
 SG_ DAS_w106_torsionBarCalibrated : 41|1@1+ (1,0) [0|1] "" Vector__XXX

BO_ 841 DAS_warningMatrix3: 8 DAS
 SG_ DAS_w193_camWindshieldUnclean : 0|1@1+ (1,0) [0|0] "" Vector__XXX
 SG_ DAS_w194_accDriverResumeRqrd : 1|1@1+ (1,0) [0|0] "" Vector__XXX
 SG_ DAS_w195_scwUnavailable : 2|1@1+ (1,0) [0|0] "" Vector__XXX
 SG_ DAS_w196_stopSignWarning : 3|1@1+ (1,0) [0|0] "" Vector__XXX
 SG_ DAS_w197_redLightWarning : 4|1@1+ (1,0) [0|0] "" Vector__XXX
 SG_ DAS_w198_tsrUnavailable : 5|1@1+ (1,0) [0|0] "" Vector__XXX
 SG_ DAS_w199_apcAbort : 6|1@1+ (1,0) [0|0] "" Vector__XXX
 SG_ DAS_w200_lcSlowdown : 7|1@1+ (1,0) [0|0] "" Vector__XXX
 SG_ DAS_w201_lcAborting : 8|1@1+ (1,0) [0|0] "" Vector__XXX
 SG_ DAS_w202_scwNoisyEnvironment : 9|1@1+ (1,0) [0|0] "" Vector__XXX
 SG_ DAS_w203_apcActivation : 10|1@1+ (1,0) [0|0] "" Vector__XXX
 SG_ DAS_w204_apcFinalFront : 11|1@1+ (1,0) [0|0] "" Vector__XXX
 SG_ DAS_w205_apcFinalRear : 12|1@1+ (1,0) [0|0] "" Vector__XXX
 SG_ DAS_w206_autosteerNotEnabled : 13|1@1+ (1,0) [0|0] "" Vector__XXX
 SG_ DAS_w207_autosteerUnavailable : 14|1@1+ (1,0) [0|0] "" Vector__XXX
 SG_ DAS_w208_rackDetected : 15|1@1+ (1,0) [0|0] "" Vector__XXX
 SG_ DAS_w209_autoSummonRequest : 16|1@1+ (1,0) [0|0] "" Vector__XXX
 SG_ DAS_w210_camObstrcted : 17|1@1+ (1,0) [0|0] "" Vector__XXX
 SG_ DAS_w211_accNoSeatBelt : 18|1@1+ (1,0) [0|0] "" Vector__XXX
 SG_ DAS_w212_lcUnavailableStrikeOut : 19|1@1+ (1,0) [0|0] "" Vector__XXX
 SG_ DAS_w213_autosteerStruckOut : 20|1@1+ (1,0) [0|0] "" Vector__XXX
 SG_ DAS_w214_driverNotIntracting : 21|1@1+ (1,0) [0|0] "" Vector__XXX
 SG_ DAS_w215_contDriverNotIntracting : 22|1@1+ (1,0) [0|0] "" Vector__XXX
 SG_ DAS_w216_driverOverriding : 23|1@1+ (1,0) [0|0] "" Vector__XXX
 SG_ DAS_w217_lcUnavailableSpeeding : 24|1@1+ (1,0) [0|0] "" Vector__XXX
 SG_ DAS_w218_lcSpeedExceededLimit : 25|1@1+ (1,0) [0|0] "" Vector__XXX
 SG_ DAS_w219_lcTempUnavailableSpeed : 26|1@1+ (1,0) [0|0] "" Vector__XXX
 SG_ DAS_w220_lcTempUnavailableRoad : 27|1@1+ (1,0) [0|0] "" Vector__XXX
 SG_ DAS_w221_accRadarBlind : 28|1@1+ (1,0) [0|0] "" Vector__XXX
 SG_ DAS_w222_accCameraBlind : 29|1@1+ (1,0) [0|0] "" Vector__XXX
 SG_ DAS_w223_accObjectInPath : 30|1@1+ (1,0) [0|0] "" Vector__XXX
 SG_ DAS_w224_accCameraCalibration : 31|1@1+ (1,0) [0|0] "" Vector__XXX
 SG_ DAS_w225_lcDegradedVisSpeedLmt : 32|1@1+ (1,0) [0|0] "" Vector__XXX
 SG_ DAS_w226_lcCamCalNeededSpeedLmt : 33|1@1+ (1,0) [0|0] "" Vector__XXX

BO_ 328 DI_espControl: 5 Vector__XXX
 SG_ DI_ptcActive : 22|1@1+ (1,0) [0|0] ""  DAS
 SG_ DI_regenTcActive : 27|1@1+ (1,0) [0|0] ""  DAS

BO_ 872 DI_state: 8 Vector__XXX
 SG_ DI_regenLight : 8|1@1+ (1,0) [0|0] ""  DAS
 SG_ DI_cruiseState : 12|4@1+ (1,0) [0|0] ""  DAS
 SG_ DI_speedUnits : 31|1@1+ (1,0) [0|1] ""  DAS
 SG_ DI_cruiseSet : 32|9@1+ (0.5,0) [0|255.5] "speed"  DAS
 SG_ DI_aebState : 41|3@1+ (1,0) [0|0] ""  DAS
 SG_ DI_digitalSpeed : 48|8@1+ (1,0) [0|250] ""  DAS

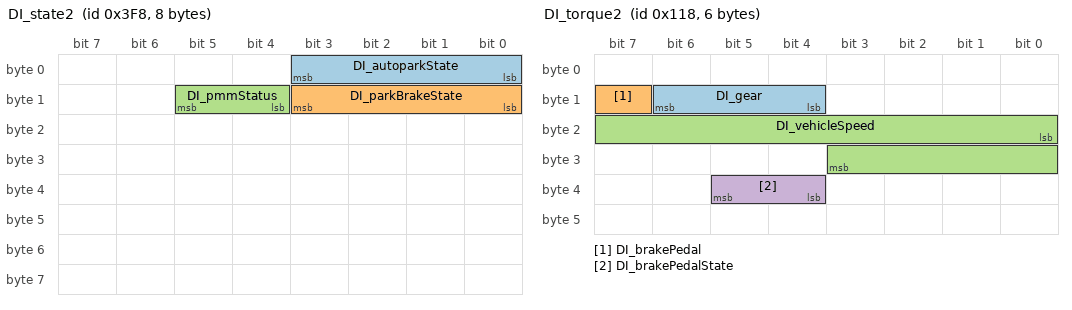
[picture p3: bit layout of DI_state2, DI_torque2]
BO_ 1016 DI_state2: 8 Vector__XXX
 SG_ DI_autoparkState : 0|4@1+ (1,0) [0|15] ""  DAS
 SG_ DI_parkBrakeState : 8|4@1+ (1,0) [0|15] ""  DAS
 SG_ DI_pmmStatus : 12|2@1+ (1,0) [0|3] ""  DAS

BO_ 264 DI_torque1: 8 Vector__XXX
 SG_ DI_torqueDriver : 0|13@1- (0.25,0) [-750|750] "Nm"  DAS
 SG_ DI_pedalPos : 48|8@1+ (0.4,0) [0|100] "%"  DAS

BO_ 280 DI_torque2: 6 Vector__XXX
 SG_ DI_gear : 12|3@1+ (1,0) [0|0] ""  DAS
 SG_ DI_brakePedal : 15|1@1+ (1,0) [0|0] ""  DAS
 SG_ DI_vehicleSpeed : 16|12@1+ (0.05,-25) [-25|179.75] "MPH"  DAS
 SG_ DI_brakePedalState : 36|2@1+ (1,0) [0|0] ""  DAS

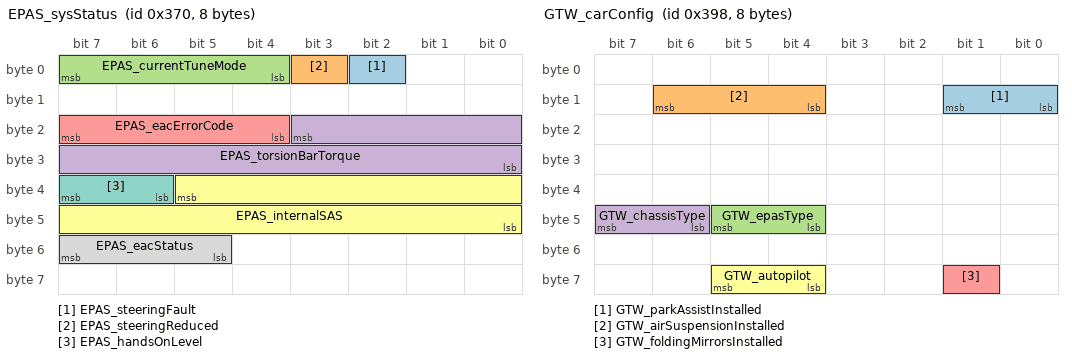
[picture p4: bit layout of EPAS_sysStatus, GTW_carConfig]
BO_ 880 EPAS_sysStatus: 8 Vector__XXX
 SG_ EPAS_steeringFault : 2|1@0+ (1,0) [0|1] ""  DAS
 SG_ EPAS_steeringReduced : 3|1@0+ (1,0) [0|1] ""  DAS
 SG_ EPAS_currentTuneMode : 7|4@0+ (1,0) [0|0] ""  DAS
 SG_ EPAS_torsionBarTorque : 19|12@0+ (0.01,-20.5) [-20.5|20.45] "Nm"  DAS
 SG_ EPAS_eacErrorCode : 23|4@0+ (1,0) [0|15] ""  DAS
 SG_ EPAS_internalSAS : 37|14@0+ (0.1,-819.2) [-819.2|819] "deg"  DAS
 SG_ EPAS_handsOnLevel : 39|2@0+ (1,0) [0|3] ""  DAS
 SG_ EPAS_eacStatus : 55|3@0+ (1,0) [0|7] ""  DAS

BO_ 516 EPB_status: 8 Vector__XXX
 SG_ EPB_state : 0|3@1+ (1,0) [0|0] ""  DAS

BO_ 277 ESP_115h: 6 Vector__XXX
 SG_ ESP_frontNegTorqueLimit : 15|1@1+ (1,0) [0|0] ""  DAS

BO_ 293 ESP_125h: 4 Vector__XXX
 SG_ Long_Acceleration : 0|8@1- (0.08,0) [-10.24|10] "m/s^2"  DAS
 SG_ Lat_Acceleration : 8|8@1- (0.08,0) [-10.24|10] "m/s^2"  DAS

BO_ 309 ESP_135h: 5 Vector__XXX
 SG_ ESP_stabilityControlSts : 12|3@1+ (1,0) [0|4] ""  DAS

BO_ 325 ESP_145h: 8 Vector__XXX
 SG_ ESP_longitudinalAccel : 0|10@1+ (0.05,-25.6) [-25.6|25.55] "m/s^2"  DAS
 SG_ ESP_lateralAccel : 16|10@1+ (0.05,-25.6) [-25.6|25.55] "m/s^2"  DAS

BO_ 341 ESP_B: 8 Vector__XXX
 SG_ ESP_wheelPulseCountReL : 16|8@1+ (1,0) [0|254] ""  DAS
 SG_ ESP_wheelPulseCountReR : 24|8@1+ (1,0) [0|254] ""  DAS

BO_ 522 ESP_C: 8 Vector__XXX
 SG_ ESP_driverBrakeApply : 2|2@1+ (1,0) [0|3] ""  DAS
 SG_ ESP_yawRate : 32|12@1+ (0.001,-2) [-2|2] "rad/s"  DAS

BO_ 373 ESP_wheelSpeeds: 8 Vector__XXX
 SG_ ESP_wheelSpeedsCounter : 52|4@1+ (1,0) [0|0] ""  DAS

BO_ 920 GTW_carConfig: 8 Vector__XXX
 SG_ GTW_parkAssistInstalled : 9|2@0+ (1,0) [0|0] ""  DAS
 SG_ GTW_airSuspensionInstalled : 14|3@0+ (1,0) [0|0] ""  DAS
 SG_ GTW_epasType : 45|2@0+ (1,0) [0|0] ""  DAS
 SG_ GTW_chassisType : 47|2@0+ (1,0) [0|2] ""  DAS
 SG_ GTW_foldingMirrorsInstalled : 57|1@0+ (1,0) [0|0] ""  DAS
 SG_ GTW_autopilot : 61|2@0+ (1,0) [0|0] ""  DAS

BO_ 1048 GTW_chNm: 1 Vector__XXX
 SG_ GTW_chGotoSleep : 0|1@1+ (1,0) [0|0] ""  DAS

BO_ 776 GTW_odo: 8 Vector__XXX
 SG_ AMB_TEMP : 8|8@1+ (0.5,-40) [-40|87.5] "C"  DAS
 SG_ GTW_ODO : 16|24@1+ (0.1,0) [0|1677721.5] "km"  DAS

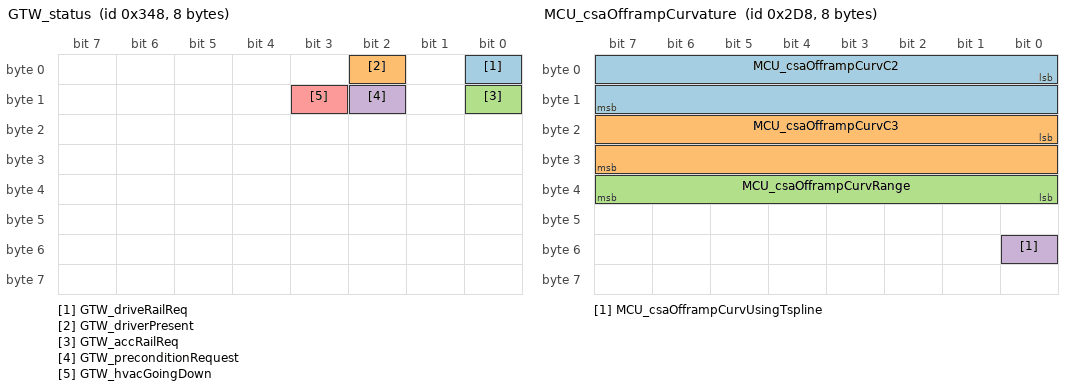
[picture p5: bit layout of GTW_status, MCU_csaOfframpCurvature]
BO_ 840 GTW_status: 8 Vector__XXX
 SG_ GTW_driveRailReq : 0|1@0+ (1,0) [0|1] ""  DAS
 SG_ GTW_driverPresent : 2|1@0+ (1,0) [0|0] ""  DAS
 SG_ GTW_accRailReq : 8|1@0+ (1,0) [0|1] ""  DAS
 SG_ GTW_preconditionRequest : 10|1@0+ (1,0) [0|1] ""  DAS
 SG_ GTW_hvacGoingDown : 11|1@1+ (1,0) [0|0] ""  DAS

BO_ 536 MCU_chassisControl: 8 Vector__XXX
 SG_ MCU_dasDebugEnable : 0|1@1+ (1,0) [0|0] ""  DAS
 SG_ MCU_trailerModeCH : 3|1@1+ (1,0) [0|0] ""  DAS
 SG_ MCU_fcwSensitivity : 4|2@1+ (1,0) [0|0] ""  DAS
 SG_ MCU_fcwEnable : 6|2@1+ (1,0) [0|0] ""  DAS
 SG_ MCU_latControlEnable : 8|2@1+ (1,0) [0|0] ""  DAS
 SG_ MCU_accOvertakeEnable : 10|2@1+ (1,0) [0|0] ""  DAS
 SG_ MCU_ldwEnable : 12|2@1+ (1,0) [0|0] ""  DAS
 SG_ MCU_aebEnable : 14|2@1+ (1,0) [0|0] ""  DAS
 SG_ MCU_bsdEnable : 16|2@1+ (1,0) [0|0] ""  DAS
 SG_ MCU_ahlbEnable : 18|2@1+ (1,0) [0|0] ""  DAS
 SG_ MCU_frontDefrostReq_das : 24|2@1+ (1,0) [0|0] ""  DAS
 SG_ MCU_autoParkRequest : 26|4@1+ (1,0) [0|0] ""  DAS
 SG_ MCU_redLightStopSignEnable : 30|2@1+ (1,0) [0|0] ""  DAS
 SG_ MCU_narrowGarages : 33|1@1+ (1,0) [0|0] ""  DAS
 SG_ MCU_overPaintedUSS : 38|2@1+ (1,0) [0|0] ""  DAS
 SG_ MCU_selfParkTune : 40|4@1+ (1,0) [0|15] ""  DAS
 SG_ MCU_aesEnable : 48|2@1+ (1,0) [0|0] ""  DAS
 SG_ MCU_autoLaneChangeEnable : 50|2@1+ (1,0) [0|0] ""  DAS

BO_ 728 MCU_csaOfframpCurvature: 8 Vector__XXX
 SG_ MCU_csaOfframpCurvC2 : 0|16@1- (1E-006,0) [-0.032768|0.032767] "1/m"  DAS
 SG_ MCU_csaOfframpCurvC3 : 16|16@1- (4E-009,0) [-0.000131072|0.000131068] "1/m2"  DAS
 SG_ MCU_csaOfframpCurvRange : 32|8@1+ (2,0) [0|510] "m"  DAS
 SG_ MCU_csaOfframpCurvUsingTspline : 48|1@1+ (1,0) [0|1] ""  DAS

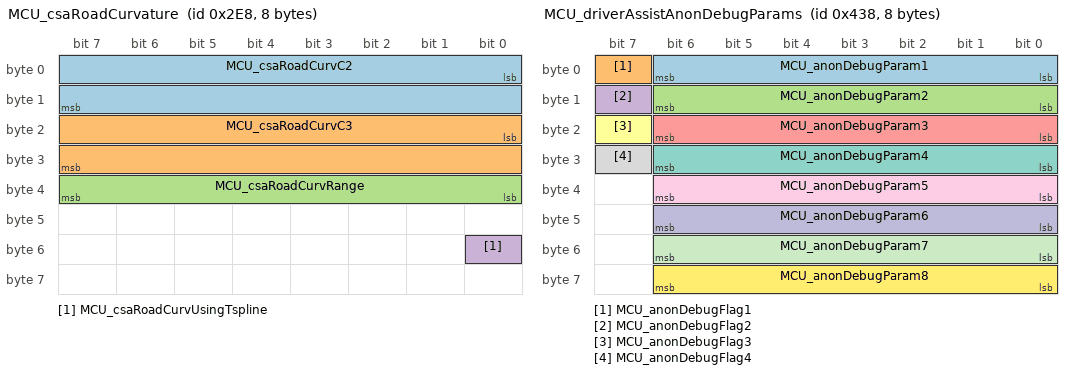
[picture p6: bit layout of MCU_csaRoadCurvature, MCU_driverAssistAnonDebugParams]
BO_ 744 MCU_csaRoadCurvature: 8 Vector__XXX
 SG_ MCU_csaRoadCurvC2 : 0|16@1- (1E-006,0) [-0.032768|0.032767] "1/m"  DAS
 SG_ MCU_csaRoadCurvC3 : 16|16@1- (4E-009,0) [-0.000131072|0.000131068] "1/m2"  DAS
 SG_ MCU_csaRoadCurvRange : 32|8@1+ (2,0) [0|510] "m"  DAS
 SG_ MCU_csaRoadCurvUsingTspline : 48|1@1+ (1,0) [0|1] ""  DAS

BO_ 1080 MCU_driverAssistAnonDebugParams: 8 Vector__XXX
 SG_ MCU_anonDebugParam1 : 0|7@1+ (1,0) [0|100] ""  DAS
 SG_ MCU_anonDebugFlag1 : 7|1@1+ (1,0) [0|0] ""  DAS
 SG_ MCU_anonDebugParam2 : 8|7@1+ (1,0) [0|100] ""  DAS
 SG_ MCU_anonDebugFlag2 : 15|1@1+ (1,0) [0|0] ""  DAS
 SG_ MCU_anonDebugParam3 : 16|7@1+ (1,0) [0|100] ""  DAS
 SG_ MCU_anonDebugFlag3 : 23|1@1+ (1,0) [0|0] ""  DAS
 SG_ MCU_anonDebugParam4 : 24|7@1+ (1,0) [0|100] ""  DAS
 SG_ MCU_anonDebugFlag4 : 31|1@1+ (1,0) [0|0] ""  DAS
 SG_ MCU_anonDebugParam5 : 32|7@1+ (1,0) [0|100] ""  DAS
 SG_ MCU_anonDebugParam6 : 40|7@1+ (1,0) [0|100] ""  DAS
 SG_ MCU_anonDebugParam7 : 48|7@1+ (1,0) [0|100] ""  DAS
 SG_ MCU_anonDebugParam8 : 56|7@1+ (1,0) [0|100] ""  DAS

BO_ 1000 MCU_driverAssistControl: 6 Vector__XXX
 SG_ MCU_autopilotControlRequest : 0|2@1+ (1,0) [0|0] ""  DAS
 SG_ MCU_accControlConfig : 2|2@1+ (1,0) [0|0] ""  DAS
 SG_ MCU_curvSpeedAdaptDisable : 4|1@1+ (1,0) [0|0] ""  DAS
 SG_ MCU_healthMonitorEnable : 5|1@1+ (1,0) [0|0] ""  DAS
 SG_ MCU_scaControlConfig : 6|2@1+ (1,0) [0|0] ""  DAS
 SG_ MCU_anonDebugConfig : 8|2@1+ (1,0) [0|0] ""  DAS
 SG_ MCU_autoSummonEnable : 10|1@1+ (1,0) [0|1] ""  DAS
 SG_ MCU_bottsDotsEnable : 11|1@1+ (1,0) [0|0] ""  DAS
 SG_ MCU_roadCheckDisable : 12|1@1+ (1,0) [0|0] ""  DAS
 SG_ MCU_experimentalModeEnable : 13|1@1+ (1,0) [0|0] ""  DAS
 SG_ MCU_handsOnRequirementDisable : 14|1@1+ (1,0) [0|0] ""  DAS
 SG_ MCU_disableRoadEstimator : 15|1@1+ (1,0) [0|0] ""  DAS
 SG_ MCU_fuseLanesDisable : 16|1@1+ (1,0) [0|0] ""  DAS
 SG_ MCU_fuseHPPDisable : 17|1@1+ (1,0) [0|0] ""  DAS
 SG_ MCU_fuseVehiclesDisable : 18|1@1+ (1,0) [0|0] ""  DAS
 SG_ MCU_fuseNavigationDisable : 19|1@1+ (1,0) [0|0] ""  DAS
 SG_ MCU_steeringRateLimits : 20|2@1+ (1,0) [0|0] ""  DAS
 SG_ MCU_curvatureDatabaseOnly : 22|1@1+ (1,0) [0|0] ""  DAS
 SG_ MCU_summonExitType : 24|2@1+ (1,0) [0|3] ""  DAS
 SG_ MCU_summonEntryType : 26|2@1+ (1,0) [0|3] ""  DAS
 SG_ MCU_selfParkRequest : 28|4@1+ (1,0) [0|15] ""  DAS
 SG_ MCU_summonReverseDist : 32|6@1+ (1,0) [0|63] ""  DAS
 SG_ MCU_undertakeAssistEnable : 38|1@1+ (1,0) [0|0] ""  DAS
 SG_ MCU_adaptiveSetSpeedEnable : 39|1@1+ (1,0) [0|0] ""  DAS
 SG_ MCU_drivingSide : 40|2@1+ (1,0) [0|3] ""  DAS

BO_ 968 MCU_driverAssistMapData: 8 Vector__XXX
 SG_ MCU_speedLimitDependency : 0|3@1+ (1,0) [0|0] ""  DAS
 SG_ MCU_roadClass : 3|3@1+ (1,0) [0|0] ""  DAS
 SG_ MCU_speedUnits : 7|1@1+ (1,0) [0|0] ""  DAS
 SG_ MCU_speedLimit : 8|5@1+ (1,0) [0|0] ""  DAS
 SG_ MCU_speedLimitType : 13|3@1+ (1,0) [0|0] ""  DAS
 SG_ MCU_countryCode : 16|10@1+ (1,0) [0|0] ""  DAS
 SG_ MCU_streetCount : 26|2@1+ (1,0) [0|0] ""  DAS
 SG_ MCU_gpsRoadMatch : 28|1@1+ (1,0) [0|0] ""  DAS
 SG_ MCU_navDataAvailable : 29|1@1+ (1,0) [0|0] ""  DAS
 SG_ MCU_nextBranchDist : 32|5@1+ (10,0) [0|300] "m"  DAS
 SG_ MCU_controlledAccess : 37|1@1+ (1,0) [0|0] ""  DAS
 SG_ MCU_nextBranchLeftOffRamp : 38|1@1+ (1,0) [0|0] ""  DAS
 SG_ MCU_nextBranchRightOffRamp : 39|1@1+ (1,0) [0|0] ""  DAS
 SG_ MCU_rejectLeftLane : 40|1@1+ (1,0) [0|0] ""  DAS
 SG_ MCU_rejectRightLane : 41|1@1+ (1,0) [0|0] ""  DAS
 SG_ MCU_rejectHPP : 42|1@1+ (1,0) [0|0] ""  DAS
 SG_ MCU_rejectNav : 43|1@1+ (1,0) [0|0] ""  DAS
 SG_ MCU_rejectLeftFreeSpace : 44|1@1+ (1,0) [0|0] ""  DAS
 SG_ MCU_rejectRightFreeSpace : 45|1@1+ (1,0) [0|0] ""  DAS
 SG_ MCU_rejectAutosteer : 46|1@1+ (1,0) [0|0] ""  DAS
 SG_ MCU_rejectHandsOn : 47|1@1+ (1,0) [0|0] ""  DAS
 SG_ MCU_acceptBottsDots : 48|1@1+ (1,0) [0|0] ""  DAS
 SG_ MCU_autosteerRestricted : 49|1@1+ (1,0) [0|0] ""  DAS
 SG_ MCU_pmmEnabled : 50|1@1+ (1,0) [0|0] ""  DAS
 SG_ MCU_scaEnabled : 51|1@1+ (1,0) [0|0] ""  DAS
 SG_ MCU_mapDataCounter : 52|4@1+ (1,0) [0|0] ""  DAS
 SG_ MCU_mapDataChecksum : 56|8@1+ (1,0) [0|0] ""  DAS

BO_ 568 MCU_driverAssistRoadSign: 8 Vector__XXX
 SG_ MCU_roadSign M : 0|8@1+ (1,0) [0|0] ""  DAS
 SG_ MCU_splineLocConfidence : 40|7@1+ (1,0) [0|100] ""  DAS
 SG_ MCU_baseMapSpeedLimitMPS m3 : 8|8@1+ (0.25,0) [0|63.75] "m/s"  DAS
 SG_ MCU_bottomQrtlFleetSpeedMPS m3 : 16|8@1+ (0.25,0) [0|63.75] "m/s"  DAS
 SG_ MCU_topQrtlFleetSpeedMPS m3 : 24|8@1+ (0.25,0) [0|63.75] "m/s"  DAS
 SG_ MCU_meanFleetSplineSpeedMPS m4 : 8|8@1+ (0.25,0) [0|63.75] "m/s"  DAS
 SG_ MCU_medianFleetSpeedMPS m4 : 16|8@1+ (0.25,0) [0|63.75] "m/s"  DAS
 SG_ MCU_rampType m4 : 24|2@1+ (1,0) [0|3] ""  DAS

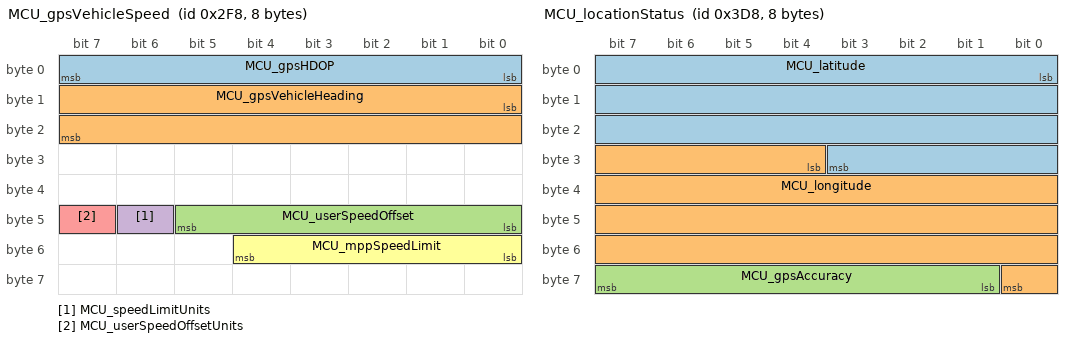
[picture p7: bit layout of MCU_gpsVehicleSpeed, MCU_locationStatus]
BO_ 760 MCU_gpsVehicleSpeed: 8 Vector__XXX
 SG_ MCU_gpsHDOP : 0|8@1+ (0.1,0) [0|25.5] "1"  DAS
 SG_ MCU_gpsVehicleHeading : 8|16@1+ (0.0078125,0) [0|511.9921875] "deg"  DAS
 SG_ MCU_userSpeedOffset : 40|6@1+ (1,-30) [-30|33] "kph/mph"  DAS
 SG_ MCU_speedLimitUnits : 46|1@1+ (1,0) [0|1] ""  DAS
 SG_ MCU_userSpeedOffsetUnits : 47|1@1+ (1,0) [0|1] ""  DAS
 SG_ MCU_mppSpeedLimit : 48|5@1+ (5,0) [0|155] "kph/mph"  DAS

BO_ 984 MCU_locationStatus: 8 Vector__XXX
 SG_ MCU_latitude : 0|28@1- (1E-006,0) [0|0] "deg"  DAS
 SG_ MCU_longitude : 28|29@1- (1E-006,0) [0|0] "deg"  DAS
 SG_ MCU_gpsAccuracy : 57|7@1+ (0.2,0) [0|0] "m"  DAS

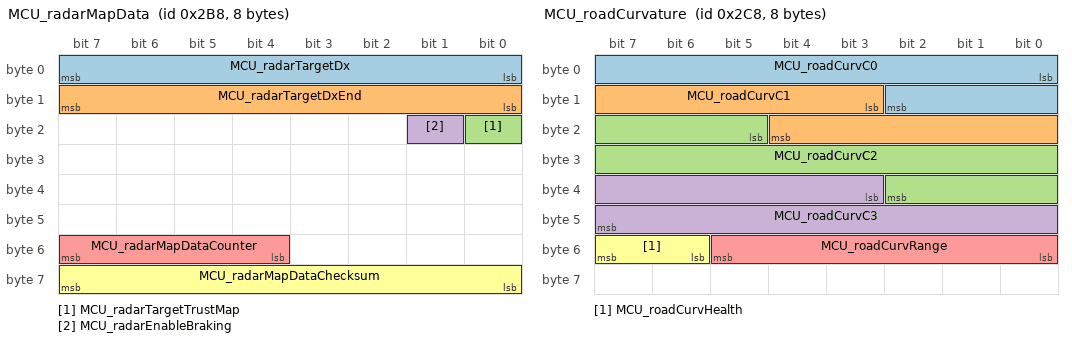
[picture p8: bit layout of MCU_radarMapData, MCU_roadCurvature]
BO_ 696 MCU_radarMapData: 8 Vector__XXX
 SG_ MCU_radarTargetDx : 0|8@1+ (1,-95) [-95|160] "m"  DAS
 SG_ MCU_radarTargetDxEnd : 8|8@1+ (1,0) [0|255] "m"  DAS
 SG_ MCU_radarTargetTrustMap : 16|1@1+ (1,0) [0|1] ""  DAS
 SG_ MCU_radarEnableBraking : 17|1@1+ (1,0) [0|1] ""  DAS
 SG_ MCU_radarMapDataCounter : 52|4@1+ (1,0) [0|0] ""  DAS
 SG_ MCU_radarMapDataChecksum : 56|8@1+ (1,0) [0|0] ""  DAS

BO_ 712 MCU_roadCurvature: 8 Vector__XXX
 SG_ MCU_roadCurvC0 : 0|11@1- (0.02,0) [-20.48|20.46] "m"  DAS
 SG_ MCU_roadCurvC1 : 11|10@1- (0.00075,0) [-0.384|0.38325] "1"  DAS
 SG_ MCU_roadCurvC2 : 21|14@1- (7.5E-006,0) [-0.03072|0.03071625] "1/m"  DAS
 SG_ MCU_roadCurvC3 : 35|13@1- (3E-008,0) [-0.00012288|0.00012285] "1/m2"  DAS
 SG_ MCU_roadCurvRange : 48|6@1+ (4,0) [0|252] "m"  DAS
 SG_ MCU_roadCurvHealth : 54|2@1+ (1,0) [0|0] ""  DAS

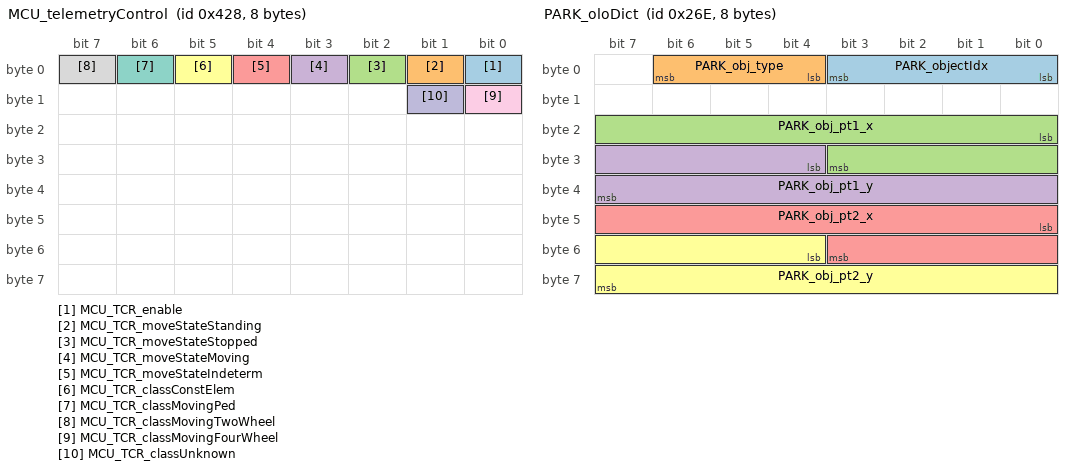
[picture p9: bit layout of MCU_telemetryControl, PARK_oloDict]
BO_ 1064 MCU_telemetryControl: 8 Vector__XXX
 SG_ MCU_TCR_enable : 0|1@1+ (1,0) [0|0] ""  DAS
 SG_ MCU_TCR_moveStateStanding : 1|1@1+ (1,0) [0|0] ""  DAS
 SG_ MCU_TCR_moveStateStopped : 2|1@1+ (1,0) [0|0] ""  DAS
 SG_ MCU_TCR_moveStateMoving : 3|1@1+ (1,0) [0|0] ""  DAS
 SG_ MCU_TCR_moveStateIndeterm : 4|1@1+ (1,0) [0|0] ""  DAS
 SG_ MCU_TCR_classConstElem : 5|1@1+ (1,0) [0|0] ""  DAS
 SG_ MCU_TCR_classMovingPed : 6|1@1+ (1,0) [0|0] ""  DAS
 SG_ MCU_TCR_classMovingTwoWheel : 7|1@1+ (1,0) [0|0] ""  DAS
 SG_ MCU_TCR_classMovingFourWheel : 8|1@1+ (1,0) [0|0] ""  DAS
 SG_ MCU_TCR_classUnknown : 9|1@1+ (1,0) [0|0] ""  DAS

BO_ 622 PARK_oloDict: 8 Vector__XXX
 SG_ PARK_objectIdx : 0|4@1+ (1,0) [0|15] ""  DAS
 SG_ PARK_obj_type : 4|3@1+ (1,0) [0|7] ""  DAS
 SG_ PARK_obj_pt1_x : 16|12@1+ (1,-2048) [-2048|2046] ""  DAS
 SG_ PARK_obj_pt1_y : 28|12@1+ (1,-2048) [-2048|2046] ""  DAS
 SG_ PARK_obj_pt2_x : 40|12@1+ (1,-2048) [-2048|2046] ""  DAS
 SG_ PARK_obj_pt2_y : 52|12@1+ (1,-2048) [-2048|2046] ""  DAS

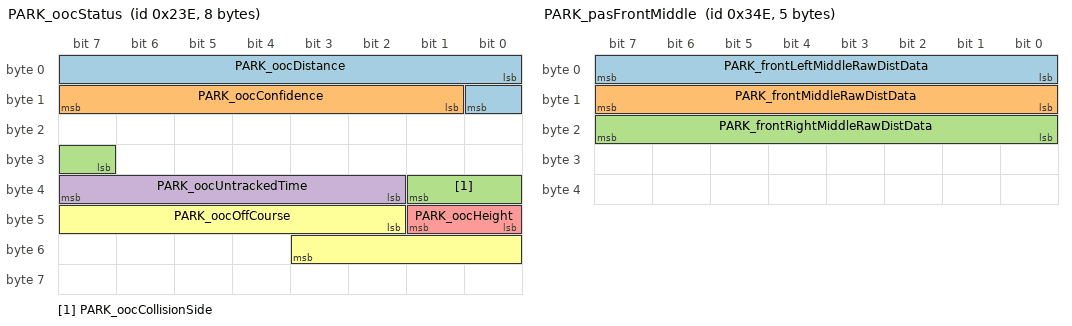
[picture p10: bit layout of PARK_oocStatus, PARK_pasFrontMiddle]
BO_ 574 PARK_oocStatus: 8 Vector__XXX
 SG_ PARK_oocDistance : 0|9@1+ (1,0) [0|512] ""  DAS
 SG_ PARK_oocConfidence : 9|7@1+ (1,0) [0|100] ""  DAS
 SG_ PARK_oocCollisionSide : 31|3@1+ (1,0) [0|7] ""  DAS
 SG_ PARK_oocUntrackedTime : 34|6@1+ (0.1,0) [0|6.3] "s"  DAS
 SG_ PARK_oocHeight : 40|2@1+ (1,0) [0|4] ""  DAS
 SG_ PARK_oocOffCourse : 42|10@1+ (1,-512) [-512|511] ""  DAS

BO_ 846 PARK_pasFrontMiddle: 5 Vector__XXX
 SG_ PARK_frontLeftMiddleRawDistData : 0|8@1+ (1,0) [0|255] ""  DAS
 SG_ PARK_frontMiddleRawDistData : 8|8@1+ (1,0) [0|255] ""  DAS
 SG_ PARK_frontRightMiddleRawDistData : 16|8@1+ (1,0) [0|255] ""  DAS

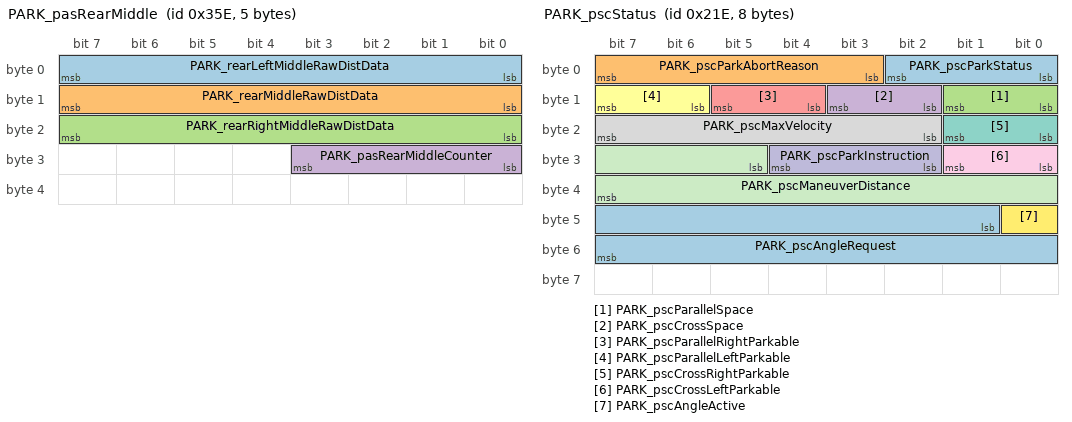
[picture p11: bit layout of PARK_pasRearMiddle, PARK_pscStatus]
BO_ 862 PARK_pasRearMiddle: 5 Vector__XXX
 SG_ PARK_rearLeftMiddleRawDistData : 0|8@1+ (1,0) [0|255] ""  DAS
 SG_ PARK_rearMiddleRawDistData : 8|8@1+ (1,0) [0|255] ""  DAS
 SG_ PARK_rearRightMiddleRawDistData : 16|8@1+ (1,0) [0|255] ""  DAS
 SG_ PARK_pasRearMiddleCounter : 24|4@1+ (1,0) [0|0] ""  DAS

BO_ 542 PARK_pscStatus: 8 Vector__XXX
 SG_ PARK_pscParkStatus : 0|3@1+ (1,0) [0|7] ""  DAS
 SG_ PARK_pscParkAbortReason : 3|5@1+ (1,0) [0|31] ""  DAS
 SG_ PARK_pscParallelSpace : 8|2@1+ (1,0) [0|3] ""  DAS
 SG_ PARK_pscCrossSpace : 10|2@1+ (1,0) [0|3] ""  DAS
 SG_ PARK_pscParallelRightParkable : 12|2@1+ (1,0) [0|3] ""  DAS
 SG_ PARK_pscParallelLeftParkable : 14|2@1+ (1,0) [0|3] ""  DAS
 SG_ PARK_pscCrossRightParkable : 16|2@1+ (1,0) [0|3] ""  DAS
 SG_ PARK_pscMaxVelocity : 18|6@1+ (0.1,0) [0|6.4] "kph"  DAS
 SG_ PARK_pscCrossLeftParkable : 24|2@1+ (1,0) [0|3] ""  DAS
 SG_ PARK_pscParkInstruction : 26|3@1+ (1,0) [0|7] ""  DAS
 SG_ PARK_pscManeuverDistance : 29|11@1+ (1,0) [0|2047] "cm"  DAS
 SG_ PARK_pscAngleActive : 40|1@1+ (1,0) [0|1] ""  DAS
 SG_ PARK_pscAngleRequest : 41|15@1+ (0.1,-1638.4) [-1638.4|1638.4] "deg"  DAS

BO_ 590 PARK_pscVehSlot: 8 Vector__XXX
 SG_ PARK_pscVehSlotType M : 0|3@1+ (1,0) [0|7] ""  DAS
 SG_ PARK_pscLeftParallelPsi m0 : 32|13@1+ (0.0009765625,0) [0|7.9990234375] "radians"  DAS
 SG_ PARK_pscLeftParallelSizeX m0 : 48|8@1+ (4,0) [0|1020] "cm"  DAS
 SG_ PARK_pscLeftParallelSizeY m0 : 56|8@1+ (4,0) [0|1020] "cm"  DAS
 SG_ PARK_pscLeftCrossPsi m1 : 32|13@1+ (0.0009765625,0) [0|7.9990234375] "radians"  DAS
 SG_ PARK_pscLeftCrossSizeX m1 : 48|8@1+ (4,0) [0|1020] "cm"  DAS
 SG_ PARK_pscLeftCrossSizeY m1 : 56|8@1+ (4,0) [0|1020] "cm"  DAS
 SG_ PARK_pscRightParallelPsi m2 : 32|13@1+ (0.0009765625,0) [0|7.9990234375] "radians"  DAS
 SG_ PARK_pscRightParallelSizeX m2 : 48|8@1+ (4,0) [0|1020] "cm"  DAS
 SG_ PARK_pscRightParallelSizeY m2 : 56|8@1+ (4,0) [0|1020] "cm"  DAS
 SG_ PARK_pscRightCrossPsi m3 : 32|13@1+ (0.0009765625,0) [0|7.9990234375] "radians"  DAS
 SG_ PARK_pscRightCrossSizeX m3 : 48|8@1+ (4,0) [0|1020] "cm"  DAS
 SG_ PARK_pscRightCrossSizeY m3 : 56|8@1+ (4,0) [0|1020] "cm"  DAS

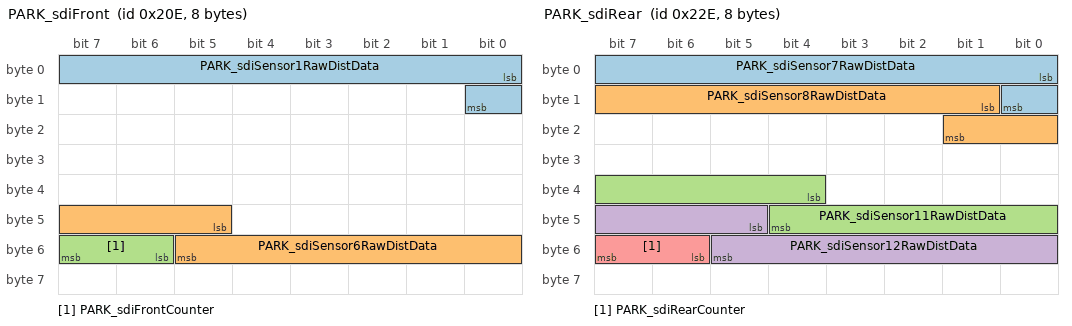
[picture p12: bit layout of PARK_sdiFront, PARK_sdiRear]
BO_ 526 PARK_sdiFront: 8 Vector__XXX
 SG_ PARK_sdiSensor1RawDistData : 0|9@1+ (1,0) [0|511] "cm"  DAS
 SG_ PARK_sdiSensor6RawDistData : 45|9@1+ (1,0) [0|511] "cm"  DAS
 SG_ PARK_sdiFrontCounter : 54|2@1+ (1,0) [0|3] ""  DAS

BO_ 558 PARK_sdiRear: 8 Vector__XXX
 SG_ PARK_sdiSensor7RawDistData : 0|9@1+ (1,0) [0|511] "cm"  DAS
 SG_ PARK_sdiSensor8RawDistData : 9|9@1+ (1,0) [0|511] "cm"  DAS
 SG_ PARK_sdiSensor11RawDistData : 36|9@1+ (1,0) [0|511] "cm"  DAS
 SG_ PARK_sdiSensor12RawDistData : 45|9@1+ (1,0) [0|511] "cm"  DAS
 SG_ PARK_sdiRearCounter : 54|2@1+ (1,0) [0|3] ""  DAS

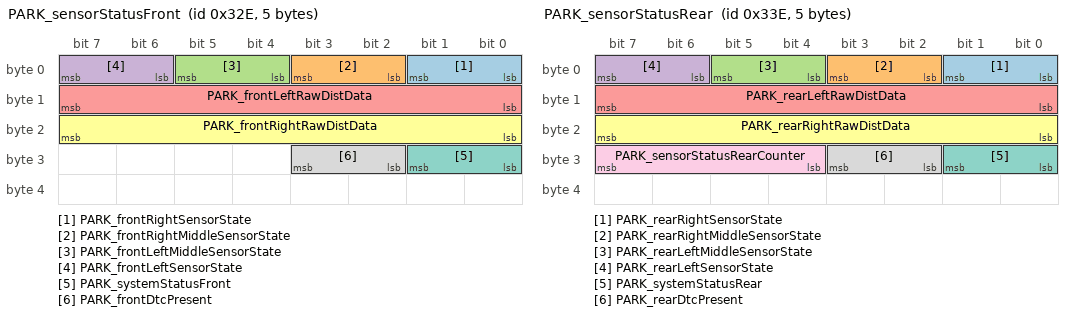
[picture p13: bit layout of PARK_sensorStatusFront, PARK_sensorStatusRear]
BO_ 814 PARK_sensorStatusFront: 5 Vector__XXX
 SG_ PARK_frontRightSensorState : 0|2@1+ (1,0) [0|0] ""  DAS
 SG_ PARK_frontRightMiddleSensorState : 2|2@1+ (1,0) [0|0] ""  DAS
 SG_ PARK_frontLeftMiddleSensorState : 4|2@1+ (1,0) [0|0] ""  DAS
 SG_ PARK_frontLeftSensorState : 6|2@1+ (1,0) [0|0] ""  DAS
 SG_ PARK_frontLeftRawDistData : 8|8@1+ (1,0) [0|255] ""  DAS
 SG_ PARK_frontRightRawDistData : 16|8@1+ (1,0) [0|255] ""  DAS
 SG_ PARK_systemStatusFront : 24|2@1+ (1,0) [0|0] ""  DAS
 SG_ PARK_frontDtcPresent : 26|2@1+ (1,0) [0|0] ""  DAS

BO_ 830 PARK_sensorStatusRear: 5 Vector__XXX
 SG_ PARK_rearRightSensorState : 0|2@1+ (1,0) [0|0] ""  DAS
 SG_ PARK_rearRightMiddleSensorState : 2|2@1+ (1,0) [0|0] ""  DAS
 SG_ PARK_rearLeftMiddleSensorState : 4|2@1+ (1,0) [0|0] ""  DAS
 SG_ PARK_rearLeftSensorState : 6|2@1+ (1,0) [0|0] ""  DAS
 SG_ PARK_rearLeftRawDistData : 8|8@1+ (1,0) [0|255] ""  DAS
 SG_ PARK_rearRightRawDistData : 16|8@1+ (1,0) [0|255] ""  DAS
 SG_ PARK_systemStatusRear : 24|2@1+ (1,0) [0|0] ""  DAS
 SG_ PARK_rearDtcPresent : 26|2@1+ (1,0) [0|0] ""  DAS
 SG_ PARK_sensorStatusRearCounter : 28|4@1+ (1,0) [0|0] ""  DAS

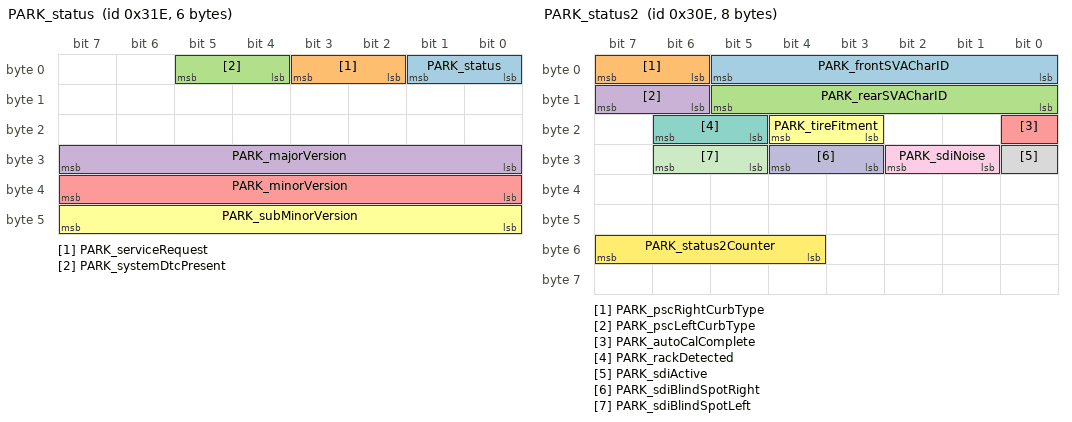
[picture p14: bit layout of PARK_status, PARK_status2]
BO_ 798 PARK_status: 6 Vector__XXX
 SG_ PARK_status : 0|2@1+ (1,0) [0|0] ""  DAS
 SG_ PARK_serviceRequest : 2|2@1+ (1,0) [0|0] ""  DAS
 SG_ PARK_systemDtcPresent : 4|2@1+ (1,0) [0|0] ""  DAS
 SG_ PARK_majorVersion : 24|8@1+ (1,0) [0|0] ""  DAS
 SG_ PARK_minorVersion : 32|8@1+ (1,0) [0|0] ""  DAS
 SG_ PARK_subMinorVersion : 40|8@1+ (1,0) [0|0] ""  DAS

BO_ 782 PARK_status2: 8 Vector__XXX
 SG_ PARK_frontSVACharID : 0|6@1+ (1,0) [0|63] ""  DAS
 SG_ PARK_pscRightCurbType : 6|2@1+ (1,0) [0|3] ""  DAS
 SG_ PARK_rearSVACharID : 8|6@1+ (1,0) [0|63] ""  DAS
 SG_ PARK_pscLeftCurbType : 14|2@1+ (1,0) [0|3] ""  DAS
 SG_ PARK_autoCalComplete : 16|1@1+ (1,0) [0|1] ""  DAS
 SG_ PARK_tireFitment : 19|2@1+ (1,0) [0|3] ""  DAS
 SG_ PARK_rackDetected : 21|2@1+ (1,0) [0|3] ""  DAS
 SG_ PARK_sdiActive : 24|1@1+ (1,0) [0|1] ""  DAS
 SG_ PARK_sdiNoise : 25|2@1+ (1,0) [0|3] ""  DAS
 SG_ PARK_sdiBlindSpotRight : 27|2@1+ (1,0) [0|3] ""  DAS
 SG_ PARK_sdiBlindSpotLeft : 29|2@1+ (1,0) [0|3] ""  DAS
 SG_ PARK_status2Counter : 52|4@1+ (1,0) [0|0] ""  DAS

BO_ 1329 RADC_info: 8 DAS
 SG_ RADC_infoIndex M : 0|8@1+ (1,0) [0|0] "" Vector__XXX
 SG_ RADC_infoBuildType m10 : 8|8@1+ (1,0) [0|0] "" Vector__XXX
 SG_ RADC_infoBuildConfigID m10 : 16|16@1+ (1,0) [0|0] "" Vector__XXX
 SG_ RADC_infoHardwareID m10 : 32|16@1+ (1,0) [0|0] "" Vector__XXX
 SG_ RADC_infoComponentID m10 : 48|16@1+ (1,0) [0|0] "" Vector__XXX
 SG_ RADC_infoPcbaID m11 : 16|8@1+ (1,0) [0|0] "" Vector__XXX
 SG_ RADC_infoAssemblyID m11 : 24|8@1+ (1,0) [0|255] "" Vector__XXX
 SG_ RADC_infoUsageID m11 : 32|16@1+ (1,0) [0|65535] "" Vector__XXX
 SG_ RADC_infoSubUsageID m11 : 48|16@1+ (1,0) [0|65535] "" Vector__XXX
 SG_ RADC_infoApplicationCRC m13 : 32|32@1+ (1,0) [0|0] "" Vector__XXX
 SG_ RADC_infoPlatformType m19 : 8|8@1+ (1,0) [0|0] "" Vector__XXX
 SG_ RADC_infoMajorVersion m19 : 16|8@1+ (1,0) [0|0] "" Vector__XXX
 SG_ RADC_infoBranchOrigin m19 : 24|8@1+ (1,0) [0|0] "" Vector__XXX
 SG_ RADC_infoMaturity m19 : 32|8@1+ (1,0) [0|0] "" Vector__XXX
 SG_ RADC_infoHardwareRevision m19 : 40|8@1+ (1,0) [0|0] "" Vector__XXX
 SG_ RADC_infoBootUdsProtoVersion m20 : 8|8@1+ (1,0) [0|0] "" Vector__XXX
 SG_ RADC_infoBootloaderCRC m20 : 32|32@1+ (1,0) [0|0] "" Vector__XXX

BO_ 1665 RADC_udsResponse: 8 DAS
 SG_ RADC_udsResponseData : 7|64@0+ (1,0) [0|0] "" Vector__XXX

BO_ 1668 RADFL_udsResponse: 8 DAS
 SG_ RADFL_udsResponseData : 7|64@0+ (1,0) [0|0] "" Vector__XXX

BO_ 1669 RADFR_udsResponse: 8 DAS
 SG_ RADFR_udsResponseData : 7|64@0+ (1,0) [0|0] "" Vector__XXX

BO_ 1666 RADRL_udsResponse: 8 DAS
 SG_ RADRL_udsResponseData : 7|64@0+ (1,0) [0|0] "" Vector__XXX

BO_ 1667 RADRR_udsResponse: 8 DAS
 SG_ RADRR_udsResponseData : 7|64@0+ (1,0) [0|0] "" Vector__XXX

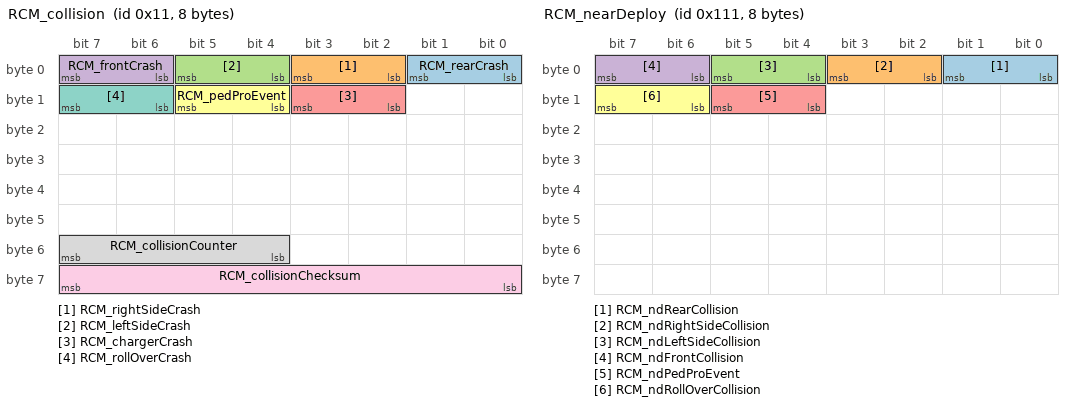
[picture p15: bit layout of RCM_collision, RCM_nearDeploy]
BO_ 17 RCM_collision: 8 Vector__XXX
 SG_ RCM_rearCrash : 1|2@0+ (1,0) [0|3] ""  DAS
 SG_ RCM_rightSideCrash : 3|2@0+ (1,0) [0|3] ""  DAS
 SG_ RCM_leftSideCrash : 5|2@0+ (1,0) [0|3] ""  DAS
 SG_ RCM_frontCrash : 7|2@0+ (1,0) [0|3] ""  DAS
 SG_ RCM_chargerCrash : 11|2@0+ (1,0) [0|3] ""  DAS
 SG_ RCM_pedProEvent : 13|2@0+ (1,0) [0|3] ""  DAS
 SG_ RCM_rollOverCrash : 15|2@0+ (1,0) [0|3] ""  DAS
 SG_ RCM_collisionCounter : 55|4@0+ (1,0) [0|15] ""  DAS
 SG_ RCM_collisionChecksum : 63|8@0+ (1,0) [0|255] ""  DAS

BO_ 273 RCM_nearDeploy: 8 Vector__XXX
 SG_ RCM_ndRearCollision : 1|2@0+ (1,0) [0|3] ""  DAS
 SG_ RCM_ndRightSideCollision : 3|2@0+ (1,0) [0|3] ""  DAS
 SG_ RCM_ndLeftSideCollision : 5|2@0+ (1,0) [0|3] ""  DAS
 SG_ RCM_ndFrontCollision : 7|2@0+ (1,0) [0|3] ""  DAS
 SG_ RCM_ndPedProEvent : 13|2@0+ (1,0) [0|3] ""  DAS
 SG_ RCM_ndRollOverCollision : 15|2@0+ (1,0) [0|3] ""  DAS

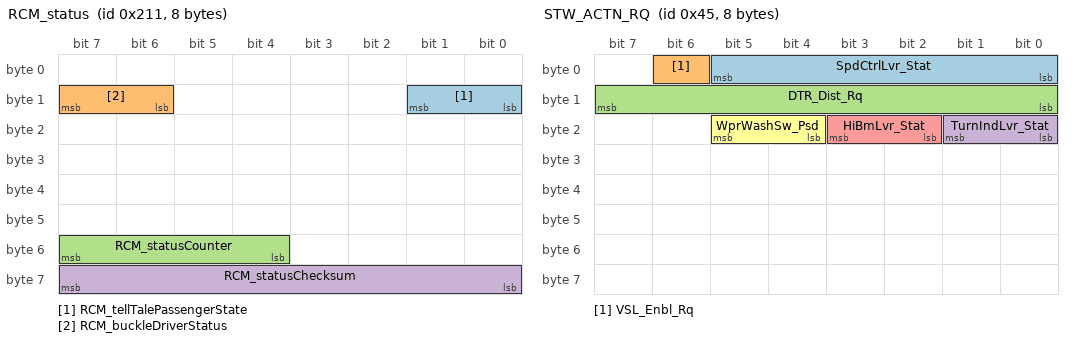
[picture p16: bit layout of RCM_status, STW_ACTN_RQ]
BO_ 529 RCM_status: 8 Vector__XXX
 SG_ RCM_tellTalePassengerState : 9|2@0+ (1,0) [0|3] ""  DAS
 SG_ RCM_buckleDriverStatus : 15|2@0+ (1,0) [0|3] ""  DAS
 SG_ RCM_statusCounter : 55|4@0+ (1,0) [0|15] ""  DAS
 SG_ RCM_statusChecksum : 63|8@0+ (1,0) [0|255] ""  DAS

BO_ 109 SBW_RQ_SCCM: 4 Vector__XXX
 SG_ TSL_P_Psd_StW : 12|2@1+ (1,0) [0|0] ""  DAS

BO_ 69 STW_ACTN_RQ: 8 Vector__XXX
 SG_ SpdCtrlLvr_Stat : 0|6@1+ (1,0) [0|0] ""  DAS
 SG_ VSL_Enbl_Rq : 6|1@1+ (1,0) [0|0] ""  DAS
 SG_ DTR_Dist_Rq : 8|8@1+ (1,0) [0|200] ""  DAS
 SG_ TurnIndLvr_Stat : 16|2@1+ (1,0) [0|0] ""  DAS
 SG_ HiBmLvr_Stat : 18|2@1+ (1,0) [0|0] ""  DAS
 SG_ WprWashSw_Psd : 20|2@1+ (1,0) [0|0] ""  DAS

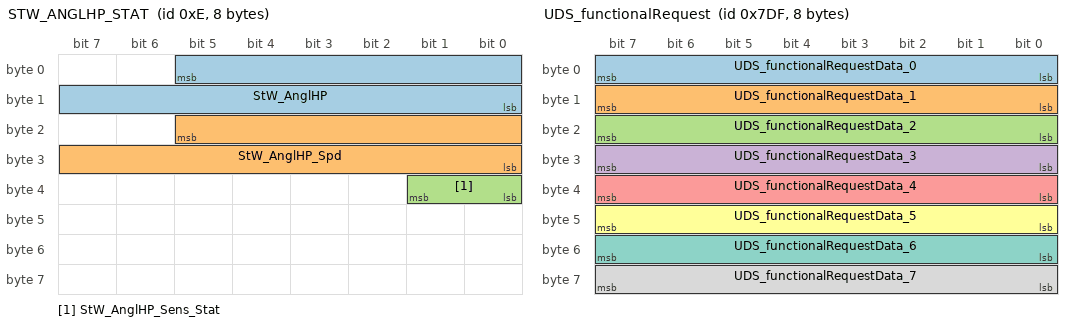
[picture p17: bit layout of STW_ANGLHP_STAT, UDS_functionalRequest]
BO_ 14 STW_ANGLHP_STAT: 8 Vector__XXX
 SG_ StW_AnglHP : 5|14@0+ (0.1,-819.2) [-819.2|819] "deg"  DAS
 SG_ StW_AnglHP_Spd : 21|14@0+ (0.5,-4096) [-4096|4095.5] "deg/s"  DAS
 SG_ StW_AnglHP_Sens_Stat : 33|2@0+ (1,0) [0|0] ""  DAS

BO_ 539 TAS_states: 8 Vector__XXX
 SG_ TAS_currentLevel : 56|3@1+ (1,0) [0|7] ""  DAS

BO_ 1609 UDS_dasRequest: 8 Vector__XXX
 SG_ UDS_dasRequestData : 7|64@0+ (1,0) [0|0] ""  DAS

BO_ 2015 UDS_functionalRequest: 8 Vector__XXX
 SG_ UDS_functionalRequestData_0 : 7|8@0+ (1,0) [0|0] ""  DAS
 SG_ UDS_functionalRequestData_1 : 15|8@0+ (1,0) [0|0] ""  DAS
 SG_ UDS_functionalRequestData_2 : 23|8@0+ (1,0) [0|0] ""  DAS
 SG_ UDS_functionalRequestData_3 : 31|8@0+ (1,0) [0|0] ""  DAS
 SG_ UDS_functionalRequestData_4 : 39|8@0+ (1,0) [0|0] ""  DAS
 SG_ UDS_functionalRequestData_5 : 47|8@0+ (1,0) [0|0] ""  DAS
 SG_ UDS_functionalRequestData_6 : 55|8@0+ (1,0) [0|0] ""  DAS
 SG_ UDS_functionalRequestData_7 : 63|8@0+ (1,0) [0|0] ""  DAS

BO_ 1649 UDS_radcRequest: 8 Vector__XXX
 SG_ UDS_radcRequestData : 7|64@0+ (1,0) [0|0] ""  DAS

BO_ 1029 VIP_405HS: 8 Vector__XXX
 SG_ EPASParamMux M : 7|8@0+ (1,0) [0|255] ""  DAS

CM_ SG_ 665 DAS_timeToImpactFrontQF "Time to Impact the Front target Qualifier from DAS";
CM_ SG_ 665 DAS_closingVelocityFrontQF "Closing Velocity between the Host vehicle and Front target Qualifier from DAS";
CM_ SG_ 665 DAS_targetDistanceFrontQF "Distance between the Host vehicle and Front target Qualifier from DAS";
CM_ SG_ 665 DAS_relativeVelocityFrontQF "Relative Velocity between the Host vehicle and Front target Qualifier from DAS";
CM_ SG_ 665 DAS_relativeAccelerationFrontQF "Relative Acceleration between the Host vehicle and Front target Qualifier from DAS";
CM_ SG_ 665 DAS_integratedSafetyFrontCRC "Checksum method for DAS_integratedSafetyFront: sum of all bytes in message + originating CAN ID (0x2 + 0x99 = 0x9b).";
CM_ SG_ 537 DAS_pscControlChecksum "Message checksum for message: sum of all bytes in message + originating CAN ID (0x2 + 0x19 = 0x1B)";
CM_ SG_ 921 DAS_fusedSpeedLimit "Speed limit unit depends on the current country";
CM_ SG_ 921 DAS_visionOnlySpeedLimit "Speed limit unit depends on the current country";
CM_ SG_ 921 DAS_statusChecksum "Checksum method for DAS_status: sum of all bytes in message + originating CAN ID (0x3 + 0x99 = 0x9c).";
CM_ SG_ 905 DAS_ppOffsetDesiredRamp "Positive value indicates that car should be laterally offset to the right of the lane center. Negative value indicates that car should be laterally offset to the left of the lane center.";
CM_ BO_ 1160 "The message sent to the EPAS to control the haptic feedback requests and external torque/angle control. ";
CM_ SG_ 937 DAS_MCPObserved "Was the mobileye Most Critical Pedestrian observed during the monitoring window";
CM_ SG_ 937 DAS_accReengaged "Was ACC re-engaged shortly after the driver cancelled";
CM_ SG_ 937 DAS_pedestrianInFOVBeforeIntr "Did the camera report a pedestrian in the field of view before the intervention";
CM_ SG_ 937 DAS_pedestrianInFOVAfterIntr "Did the camera detect a pedestrian in the field of view after the intervention";
CM_ SG_ 937 DAS_camFreeSpaceBeforeIntr "Did the camera report free-space before the intervention";
CM_ SG_ 937 DAS_camFreeSpaceAfterIntr "Did the camera report free-space after the intervention";
CM_ SG_ 937 DAS_timeOfIntervention "Time of intervention since the auto-resume";
CM_ SG_ 937 DAS_timeOfFirstPedestrian "Time when the first pedestrian was observed since the auto-resume";
CM_ SG_ 937 DAS_timeOfACCReengaging "Time when ACC was reengaged since the auto-resume";
CM_ SG_ 937 DAS_durationOfPrevACCStandstill "How long were we in standstill before we resumed";
CM_ SG_ 937 DAS_maxAbsSteeringWheelAngle "Maximum absolute steering wheel angle since auto-resume";
CM_ SG_ 937 DAS_targetRelvelAtIntervention "Relative velocity of target at intervention";
CM_ SG_ 937 DAS_targetDistAtIntervention "Distance of target at intervention";
CM_ SG_ 937 DAS_egoSpeedAtIntervention "Ego speed at intervention";
CM_ SG_ 328 DI_ptcActive "TRUE when Tesla traction control is active";
CM_ SG_ 328 DI_regenTcActive "TRUE when Tesla regen traction control is active.";
CM_ BO_ 872 "Drive Inverter status through GTW from the PT bus. Message is cyclic on the CH bus triggered by GTW receiving a cyclic message from the Drive Inverter.";
CM_ SG_ 872 DI_regenLight "TRUE to request lighting regen brake lights.";
CM_ SG_ 872 DI_cruiseState "Cruise control state.";
CM_ SG_ 872 DI_cruiseSet "Cruise control set point.";
CM_ BO_ 1016 "Drive Inverter state indicators 2.";
CM_ SG_ 1016 DI_autoparkState "Autopark control state.";
CM_ SG_ 1016 DI_parkBrakeState "DI Park Brake control and EPB interface state.";
CM_ SG_ 264 DI_torqueDriver "Driver requested torque command. SNA is 0xF000";
CM_ SG_ 264 DI_pedalPos "Drive Inverter measured pedal position.";
CM_ BO_ 280 "This message is temporarily sent by the gateway with special code";
CM_ SG_ 280 DI_gear "Current operating gear.";
CM_ SG_ 280 DI_brakePedal "TRUE if brake pedal input signal is active.";
CM_ SG_ 880 EPAS_steeringFault "Power steering is not-available";
CM_ SG_ 880 EPAS_steeringReduced "Power steering is functional, but reduced";
CM_ SG_ 880 EPAS_currentTuneMode "Feedback of selected tuning mode";
CM_ SG_ 880 EPAS_torsionBarTorque "Realtime estimated torque on torsion bar";
CM_ SG_ 880 EPAS_handsOnLevel "Hands on detection level defined by configurable thresholds";
CM_ SG_ 880 EPAS_eacStatus "Status of the EAC system, to indicate what mode is active";
CM_ SG_ 516 EPB_state "EPB state machine mode - EPB_STATE_PARK or EPB_STATE_HANDBRAKE means parking brake is applied";
CM_ BO_ 277 "Cycle time is 10ms in Bosch 5/2/11 software. Will be 20ms in 6/24 release";
CM_ SG_ 277 ESP_frontNegTorqueLimit "ESP front motor torque request: max.-mode 1=torque increase";
CM_ SG_ 293 Long_Acceleration "Positive acceleration when the vehicle is braking. Long term offset compensated.";
CM_ SG_ 293 Lat_Acceleration "Positive acceleration during a turn to the right. Long term offset compensated.";
CM_ SG_ 309 ESP_stabilityControlSts "{Off = 0, On, Engaged, Faulted, Not Configured}";
CM_ SG_ 325 ESP_longitudinalAccel "Positive acceleration when the vehicle is accelerating. Offset compensated.";
CM_ SG_ 325 ESP_lateralAccel "Positive acceleration during a left turn. Offset compensated.";
CM_ SG_ 341 ESP_wheelPulseCountReL "Wheel speed sensor cumulative pulse counter for rear left wheel.";
CM_ SG_ 341 ESP_wheelPulseCountReR "Wheel speed sensor cumulative pulse counter for rear right wheel.";
CM_ SG_ 522 ESP_driverBrakeApply "Indicates when the driver applies the brake pedal. ";
CM_ SG_ 522 ESP_yawRate "Yaw rate is positive during a left turn. Offset compensated.";
CM_ SG_ 373 ESP_wheelSpeedsCounter "Message counter for ESP_wheelSpeeds message: increments in each message.";
CM_ SG_ 776 AMB_TEMP "Ambience temperature";
CM_ SG_ 776 GTW_ODO "Odometer";
CM_ BO_ 536 "traction control signals are not used by ESP, they use GTW_ESP1 message";
CM_ SG_ 536 MCU_trailerModeCH "Indicates whether trailer mode is selected. To be used when towing a trailer. Signal on CH bus.";
CM_ SG_ 536 MCU_fcwEnable "Enable Forward Collision Warning";
CM_ SG_ 536 MCU_latControlEnable "Enable Lateral Control (lane centering, lane keeping, lane changing)";
CM_ SG_ 536 MCU_accOvertakeEnable "Enable ACC Overtake assistance (reduce follow distance when the turn signal is on)";
CM_ SG_ 536 MCU_ldwEnable "Enable Lane Departure Warning";
CM_ SG_ 536 MCU_aebEnable "Enable Autonomous Emergency Brakes";
CM_ SG_ 536 MCU_bsdEnable "Enable Blind Spot Detection";
CM_ SG_ 536 MCU_ahlbEnable "Enable Automatic High/Low Beams";
CM_ SG_ 536 MCU_redLightStopSignEnable "Enable Red Light and Stop Sign Warnings";
CM_ SG_ 536 MCU_aesEnable "Enable Automatic Emergency Steering";
CM_ SG_ 968 MCU_countryCode "Country Code from NAV as defined in http://en.wikipedia.org/wiki/ISO_3166-1_numeric";
CM_ BO_ 574 "OOC is Object on Course and refers to a collision object detected on the current travel path. ";
CM_ SG_ 574 PARK_oocDistance "The distance the vehicle would travel along its current trajectory until the detected object would collide with the vehicle. Units are in cm ";
CM_ SG_ 574 PARK_oocConfidence "0-100% Confidence that the detected object is real and on the current path. Units are in percent ";
CM_ SG_ 574 PARK_oocCollisionSide "The side of the car that the collision is expected to occur on (or no collision). ";
CM_ SG_ 574 PARK_oocUntrackedTime "Time since the last echo measurement on the detected object.";
CM_ SG_ 574 PARK_oocHeight "The detected object is a high object or not a high object. The high object is when the system detects two objects very close together. ";
CM_ SG_ 574 PARK_oocOffCourse "Distance nearest object is off from the edge of the tube of travel of the vehicle, eg 0 = side of car, and 100 is centerlines. Units are in cm ";
CM_ SG_ 846 PARK_frontLeftMiddleRawDistData "Zone defined as -38 degrees -> +12 degrees, distance to object in units of centimeters.";
CM_ SG_ 846 PARK_frontMiddleRawDistData "Zone defined as -12 degrees to +12 degrees, distance to object in units of centimeters.";
CM_ SG_ 846 PARK_frontRightMiddleRawDistData "Zone defined +12 degrees to +38 degreees, distance to object in units of centimeters.";
CM_ SG_ 862 PARK_rearLeftMiddleRawDistData "Zone defined as -124 degrees to -166 degrees, distance to object in units of centimeters.";
CM_ SG_ 862 PARK_rearMiddleRawDistData "Zone defined as -166 degrees to +166 degrees, distance to object in units of centimeters.";
CM_ SG_ 862 PARK_rearRightMiddleRawDistData "Zone defined as +166 degrees to +124 degrees, distance to object in units of centimeters.";
CM_ SG_ 542 PARK_pscMaxVelocity "The maximum velocity allowed during each manuever. Updated during each manuever.";
CM_ SG_ 542 PARK_pscManeuverDistance "Real time updated path length from center of vehicle reference frame to desired center of vehicle at end of current parking manuever. ";
CM_ BO_ 590 "Message to indicate the real time location of all possible parking slots with respect to the vehicle's frame of refence. ";
CM_ SG_ 590 PARK_pscLeftCrossPsi "Angle of car with respect to the front target vehicle. Set to NO_SPACE until status = pre-guidance.";
CM_ SG_ 590 PARK_pscLeftCrossSizeX "The x axis dimension of the pependicular space on the left side of the road. (x axis is along the length of the vehicle)";
CM_ SG_ 590 PARK_pscLeftCrossSizeY "The y-axis dimension of the pependicular space on the left side of the road. (y axis is along the width of the vehicle)";
CM_ BO_ 526 "Direct echo data from sensors in firing group 1, and some system wide status information. The sensors are numbered 1-12, starting the front left corner of the vehicle and going around clockwise. ";
CM_ BO_ 558 "Direct echo data from sensors in firing group 2, and some system wide status information. ";
CM_ SG_ 814 PARK_frontLeftRawDistData "Zone defined as -90 degrees -> -38 degrees, distance to object in units of centimeters.";
CM_ SG_ 814 PARK_frontRightRawDistData "Zone defined as +38 degrees -> +90 degrees, distance to object in units of centimeters.";
CM_ SG_ 830 PARK_rearLeftRawDistData "Zone defined as -90 degrees to -125 degrees, distance to object in units of centimeters.";
CM_ SG_ 830 PARK_rearRightRawDistData "Zone defined as +125 degrees to +90 degrees, distance to object in units of centimeters.";
CM_ SG_ 17 RCM_collisionChecksum "Message checksum for RCM_collision message: Sum of all bytes in message (Unused fields are set to 0) + 0x17.";
CM_ SG_ 529 RCM_statusChecksum "Message checksum for RCM_status message: Sum of all bytes in message (Unused fields are set to 0) + 0x13.";
CM_ SG_ 109 TSL_P_Psd_StW "Indicates when transmission selector lever 'P' switch is selected (steering wheel).";
CM_ SG_ 69 SpdCtrlLvr_Stat "Speed control lever status (For cruise control).";
CM_ SG_ 69 VSL_Enbl_Rq "Enable variable speed limiter request";
CM_ SG_ 69 DTR_Dist_Rq "Distronic distance factor request";
CM_ SG_ 69 TurnIndLvr_Stat "Turn indicator lever state";
CM_ SG_ 69 HiBmLvr_Stat "High beam lever state";
CM_ SG_ 69 WprWashSw_Psd "Wiper/washer switch pressed";
CM_ SG_ 14 StW_AnglHP "Steering wheel angle with high precision";
CM_ SG_ 14 StW_AnglHP_Spd "Steering wheel angle speed with high precision.";
CM_ SG_ 14 StW_AnglHP_Sens_Stat "Steering wheel angle with high presision sensor state";
CM_ SG_ 539 TAS_currentLevel "Current level of the air suspension";
BA_DEF_ SG_  "LogSignal" STRING ;
BA_DEF_ SG_  "GenSigTimeout_PTS" INT 0 65535;
BA_DEF_ SG_  "GenSigTimeout_MPC" INT 0 65535;
BA_DEF_ SG_  "GenSigTimeout_ESP_ABR" INT 0 65535;
BA_DEF_ SG_  "GenSigTimeout_CGW" INT 0 65535;
BA_DEF_ SG_  "GenSigStartValue" INT 0 0;
BA_DEF_ SG_  "GenSigSendType" ENUM  "Cyclic","OnWrite","OnWriteWithRepetition","OnChange","OnChangeWithRepetition","IfActive","IfActiveWithRepetition","NoSigSendType","NotUsed","NotUsed","NotUsed","NotUsed","NotUsed";
BA_DEF_ SG_  "GenSigSNA" STRING ;
BA_DEF_ SG_  "GenSigCycleTimeActive" INT 0 0;
BA_DEF_ SG_  "GenSigCycleTime" INT 0 0;
BA_DEF_ SG_  "FlexKomSigStartValue" STRING ;
BA_DEF_ SG_  "FlexKomSigStartPos" INT 0 63;
BA_DEF_ SG_  "FlexKomSigName" STRING ;
BA_DEF_ SG_  "FlexKomSigLaenge" INT 0 64;
BA_DEF_ SG_  "FlexKomSID" INT 0 2147483647;
BA_DEF_ SG_  "FlexKomIsMotorola" ENUM  "nein","ja";
BA_DEF_ SG_  "FlexKomComment" STRING ;
BA_DEF_ SG_  "FieldType" STRING ;
BA_DEF_ BO_  "UsesChecksum" ENUM  "No","Yes";
BA_DEF_ BO_  "NWMBotschaft" ENUM  "nein","ja";
BA_DEF_ BO_  "MessageIdType" ENUM  "normal","udsRequest","udsResponse","udsReserved","udsFunctionalRequest","networkManagement","bootloader","xcp","dtc","diagnostic","vendorExempt";
BA_DEF_ BO_  "GenMsgTimeOut" INT 0 0;
BA_DEF_ BO_  "GenMsgStartValue" STRING ;
BA_DEF_ BO_  "GenMsgSendType" ENUM  "Cyclic","NotUsed","NotUsed","NotUsed","NotUsed","NotUsed","NotUsed","IfActive","NoMsgSendType","Sporadic";
BA_DEF_ BO_  "GenMsgSaltingFunction" ENUM  "No","Yes";
BA_DEF_ BO_  "GenMsgILSupport" ENUM  "No","Yes";
BA_DEF_ BO_  "GenMsgForceMiaCheck" ENUM  "No","Yes";
BA_DEF_ BO_  "GenMsgDelayTime" INT 0 0;
BA_DEF_ BO_  "GenMsgCycleTimeFast" INT 0 0;
BA_DEF_ BO_  "GenMsgCycleTime" INT 0 0;
BA_DEF_ BO_  "GatewayMessageSendType" ENUM  "UseGenMsgSendType","onWrite","noAutoCode";
BA_DEF_ BO_  "GatewayHandlerEnum" ENUM  "noHandler","uds","alertLog","messageLogOnReception","udsClient";
BA_DEF_ BO_  "ETHId" STRING ;
BA_DEF_ BO_  "DiagResponse" ENUM  "No","Yes";
BA_DEF_ BO_  "DiagRequest" ENUM  "No","Yes";
BA_DEF_ BO_  "AppBotschaft" ENUM  "nein","ja";
BA_DEF_ BO_  "AlertType" INT 0 4;
BA_DEF_ BO_  "AlertLogSubSystemId" INT 0 0;
BA_DEF_DEF_  "LogSignal" "";
BA_DEF_DEF_  "GenSigTimeout_PTS" 0;
BA_DEF_DEF_  "GenSigTimeout_MPC" 0;
BA_DEF_DEF_  "GenSigTimeout_ESP_ABR" 0;
BA_DEF_DEF_  "GenSigTimeout_CGW" 0;
BA_DEF_DEF_  "GenSigStartValue" 0;
BA_DEF_DEF_  "GenSigSendType" "Cyclic";
BA_DEF_DEF_  "GenSigSNA" "";
BA_DEF_DEF_  "GenSigCycleTimeActive" 0;
BA_DEF_DEF_  "GenSigCycleTime" 0;
BA_DEF_DEF_  "FlexKomSigStartValue" "";
BA_DEF_DEF_  "FlexKomSigStartPos" 0;
BA_DEF_DEF_  "FlexKomSigName" "";
BA_DEF_DEF_  "FlexKomSigLaenge" 0;
BA_DEF_DEF_  "FlexKomSID" 0;
BA_DEF_DEF_  "FlexKomIsMotorola" "";
BA_DEF_DEF_  "FlexKomComment" "";
BA_DEF_DEF_  "FieldType" "";
BA_DEF_DEF_  "UsesChecksum" "No";
BA_DEF_DEF_  "NWMBotschaft" "nein";
BA_DEF_DEF_  "MessageIdType" "normal";
BA_DEF_DEF_  "GenMsgTimeOut" 0;
BA_DEF_DEF_  "GenMsgStartValue" "";
BA_DEF_DEF_  "GenMsgSendType" "Cyclic";
BA_DEF_DEF_  "GenMsgSaltingFunction" "No";
BA_DEF_DEF_  "GenMsgILSupport" "Yes";
BA_DEF_DEF_  "GenMsgForceMiaCheck" "No";
BA_DEF_DEF_  "GenMsgDelayTime" 0;
BA_DEF_DEF_  "GenMsgCycleTimeFast" 0;
BA_DEF_DEF_  "GenMsgCycleTime" 0;
BA_DEF_DEF_  "GatewayMessageSendType" "UseGenMsgSendType";
BA_DEF_DEF_  "GatewayHandlerEnum" "noHandler";
BA_DEF_DEF_  "ETHId" "";
BA_DEF_DEF_  "DiagResponse" "No";
BA_DEF_DEF_  "DiagRequest" "No";
BA_DEF_DEF_  "AppBotschaft" "nein";
BA_DEF_DEF_  "AlertType" 4;
BA_DEF_DEF_  "AlertLogSubSystemId" 0;
BA_ "GenMsgTimeOut" BO_ 1337 1000;
BA_ "GenMsgCycleTime" BO_ 1337 1000;
BA_ "GenMsgCycleTime" BO_ 665 60;
BA_ "GatewayMessageSendType" BO_ 665 1;
BA_ "GenMsgCycleTime" BO_ 569 100;
BA_ "GenMsgCycleTime" BO_ 777 30;
BA_ "GatewayMessageSendType" BO_ 777 1;
BA_ "GenMsgCycleTime" BO_ 537 40;
BA_ "GenMsgCycleTime" BO_ 921 500;
BA_ "GatewayMessageSendType" BO_ 921 1;
BA_ "GenMsgCycleTime" BO_ 905 500;
BA_ "GatewayMessageSendType" BO_ 905 1;
BA_ "GenMsgCycleTime" BO_ 1160 20;
BA_ "GenMsgCycleTime" BO_ 937 100;
BA_ "GenMsgCycleTime" BO_ 985 100;
BA_ "GenMsgCycleTime" BO_ 945 40;
BA_ "GenMsgCycleTime" BO_ 889 40;
BA_ "GenMsgCycleTime" BO_ 1545 5;
BA_ "MessageIdType" BO_ 1625 2;
BA_ "GenMsgSendType" BO_ 1625 8;
BA_ "GatewayHandlerEnum" BO_ 1625 4;
BA_ "DiagResponse" BO_ 1625 1;
BA_ "GenMsgCycleTime" BO_ 585 100;
BA_ "GatewayMessageSendType" BO_ 585 1;
BA_ "GenMsgCycleTime" BO_ 809 1000;
BA_ "GatewayMessageSendType" BO_ 809 1;
BA_ "ETHId" BO_ 809 "RETAIN_ID";
BA_ "AlertType" BO_ 809 0;
BA_ "GenMsgCycleTime" BO_ 873 1000;
BA_ "GatewayMessageSendType" BO_ 873 1;
BA_ "ETHId" BO_ 873 "RETAIN_ID";
BA_ "AlertType" BO_ 873 0;
BA_ "GenMsgCycleTime" BO_ 841 1000;
BA_ "GatewayMessageSendType" BO_ 841 1;
BA_ "ETHId" BO_ 841 "RETAIN_ID";
BA_ "AlertType" BO_ 841 1;
BA_ "GenMsgCycleTime" BO_ 328 20;
BA_ "GatewayMessageSendType" BO_ 328 2;
BA_ "GenMsgCycleTime" BO_ 872 100;
BA_ "GatewayMessageSendType" BO_ 872 1;
BA_ "GenMsgCycleTime" BO_ 1016 100;
BA_ "GatewayMessageSendType" BO_ 1016 1;
BA_ "GenMsgCycleTime" BO_ 264 10;
BA_ "GatewayMessageSendType" BO_ 264 2;
BA_ "GenMsgTimeOut" BO_ 280 500;
BA_ "GenMsgCycleTime" BO_ 280 10;
BA_ "GatewayMessageSendType" BO_ 280 2;
BA_ "GenMsgCycleTime" BO_ 880 40;
BA_ "GenMsgCycleTime" BO_ 516 100;
BA_ "GenMsgCycleTime" BO_ 277 20;
BA_ "GenMsgTimeOut" BO_ 293 500;
BA_ "GenMsgCycleTime" BO_ 293 100;
BA_ "GenMsgCycleTime" BO_ 309 100;
BA_ "GenMsgCycleTime" BO_ 325 20;
BA_ "GenMsgTimeOut" BO_ 341 500;
BA_ "GenMsgCycleTime" BO_ 341 20;
BA_ "MessageIdType" BO_ 522 10;
BA_ "GenMsgCycleTime" BO_ 522 20;
BA_ "GenMsgCycleTime" BO_ 373 10;
BA_ "GenMsgCycleTime" BO_ 920 1000;
BA_ "GenMsgSaltingFunction" BO_ 1048 1;
BA_ "GenMsgCycleTime" BO_ 1048 100;
BA_ "GenMsgTimeOut" BO_ 776 500;
BA_ "GenMsgDelayTime" BO_ 776 20;
BA_ "GenMsgCycleTimeFast" BO_ 776 100;
BA_ "GenMsgCycleTime" BO_ 776 100;
BA_ "GenMsgSaltingFunction" BO_ 840 1;
BA_ "GenMsgCycleTime" BO_ 840 100;
BA_ "GenMsgCycleTime" BO_ 536 500;
BA_ "GatewayMessageSendType" BO_ 536 1;
BA_ "GenMsgCycleTime" BO_ 728 100;
BA_ "GatewayMessageSendType" BO_ 728 1;
BA_ "GenMsgCycleTime" BO_ 744 100;
BA_ "GatewayMessageSendType" BO_ 744 1;
BA_ "GenMsgSendType" BO_ 1080 7;
BA_ "GenMsgCycleTime" BO_ 1080 1000;
BA_ "GatewayMessageSendType" BO_ 1080 1;
BA_ "GenMsgCycleTime" BO_ 1000 1000;
BA_ "GatewayMessageSendType" BO_ 1000 1;
BA_ "GenMsgCycleTime" BO_ 968 500;
BA_ "GatewayMessageSendType" BO_ 968 1;
BA_ "GenMsgCycleTime" BO_ 568 100;
BA_ "GatewayMessageSendType" BO_ 568 1;
BA_ "GenMsgCycleTime" BO_ 760 1000;
BA_ "GatewayMessageSendType" BO_ 760 1;
BA_ "GenMsgCycleTime" BO_ 984 1000;
BA_ "GatewayMessageSendType" BO_ 984 1;
BA_ "GenMsgCycleTime" BO_ 696 100;
BA_ "GatewayMessageSendType" BO_ 696 1;
BA_ "GenMsgCycleTime" BO_ 712 100;
BA_ "GatewayMessageSendType" BO_ 712 1;
BA_ "GenMsgSendType" BO_ 1064 7;
BA_ "GenMsgCycleTime" BO_ 1064 1000;
BA_ "GatewayMessageSendType" BO_ 1064 1;
BA_ "GenMsgCycleTime" BO_ 622 20;
BA_ "GenMsgCycleTime" BO_ 574 40;
BA_ "GenMsgCycleTime" BO_ 846 100;
BA_ "GenMsgCycleTime" BO_ 862 100;
BA_ "GenMsgCycleTime" BO_ 542 40;
BA_ "GenMsgCycleTime" BO_ 590 100;
BA_ "GenMsgCycleTime" BO_ 526 40;
BA_ "GenMsgCycleTime" BO_ 558 40;
BA_ "GenMsgCycleTime" BO_ 814 100;
BA_ "GenMsgCycleTime" BO_ 830 100;
BA_ "GenMsgCycleTime" BO_ 798 500;
BA_ "GenMsgCycleTime" BO_ 782 250;
BA_ "GenMsgCycleTime" BO_ 1329 2000;
BA_ "MessageIdType" BO_ 1665 2;
BA_ "GenMsgSendType" BO_ 1665 8;
BA_ "GatewayHandlerEnum" BO_ 1665 4;
BA_ "DiagResponse" BO_ 1665 1;
BA_ "MessageIdType" BO_ 1668 2;
BA_ "GenMsgSendType" BO_ 1668 8;
BA_ "GatewayHandlerEnum" BO_ 1668 4;
BA_ "DiagResponse" BO_ 1668 1;
BA_ "MessageIdType" BO_ 1669 2;
BA_ "GenMsgSendType" BO_ 1669 8;
BA_ "GatewayHandlerEnum" BO_ 1669 4;
BA_ "DiagResponse" BO_ 1669 1;
BA_ "MessageIdType" BO_ 1666 2;
BA_ "GenMsgSendType" BO_ 1666 8;
BA_ "GatewayHandlerEnum" BO_ 1666 4;
BA_ "DiagResponse" BO_ 1666 1;
BA_ "MessageIdType" BO_ 1667 2;
BA_ "GenMsgSendType" BO_ 1667 8;
BA_ "GatewayHandlerEnum" BO_ 1667 4;
BA_ "DiagResponse" BO_ 1667 1;
BA_ "UsesChecksum" BO_ 17 1;
BA_ "GenMsgSendType" BO_ 17 7;
BA_ "GenMsgCycleTime" BO_ 17 10;
BA_ "UsesChecksum" BO_ 273 1;
BA_ "GenMsgSendType" BO_ 273 7;
BA_ "GenMsgCycleTime" BO_ 273 10;
BA_ "UsesChecksum" BO_ 529 1;
BA_ "GenMsgCycleTime" BO_ 529 100;
BA_ "MessageIdType" BO_ 109 10;
BA_ "GenMsgStartValue" BO_ 109 "00E600FFh";
BA_ "GenMsgCycleTime" BO_ 109 10;
BA_ "UsesChecksum" BO_ 69 1;
BA_ "MessageIdType" BO_ 69 10;
BA_ "GenMsgStartValue" BO_ 69 "00FF0000000007FFh";
BA_ "GenMsgCycleTime" BO_ 69 100;
BA_ "MessageIdType" BO_ 14 10;
BA_ "GenMsgStartValue" BO_ 14 "3FFF3FFF03FF00FFh";
BA_ "GenMsgCycleTime" BO_ 14 10;
BA_ "GenMsgCycleTime" BO_ 539 100;
BA_ "MessageIdType" BO_ 1609 1;
BA_ "GenMsgSendType" BO_ 1609 8;
BA_ "DiagRequest" BO_ 1609 1;
BA_ "MessageIdType" BO_ 2015 4;
BA_ "GenMsgSendType" BO_ 2015 8;
BA_ "GenMsgDelayTime" BO_ 2015 20;
BA_ "GenMsgCycleTimeFast" BO_ 2015 100;
BA_ "GenMsgCycleTime" BO_ 2015 100;
BA_ "DiagRequest" BO_ 2015 1;
BA_ "MessageIdType" BO_ 1649 1;
BA_ "GenMsgSendType" BO_ 1649 8;
BA_ "DiagRequest" BO_ 1649 1;
BA_ "GenMsgSaltingFunction" BO_ 1029 1;
BA_ "GenMsgCycleTime" BO_ 1029 250;
BA_ "GenSigCycleTime" SG_ 1337 DAS_infoIndex 1000;
BA_ "FieldType" SG_ 1337 DAS_infoIndex "DAS_infoIndex";
BA_ "GenSigStartValue" SG_ 1337 DAS_infoApplicationCRC 4294967295;
BA_ "GenSigStartValue" SG_ 1337 DAS_infoEyeQBootCRC 4294967295;
BA_ "GenSigCycleTime" SG_ 1337 DAS_infoEyeQBootCRC 1000;
BA_ "GenSigStartValue" SG_ 1337 DAS_infoPlatformType 255;
BA_ "GenSigStartValue" SG_ 1337 DAS_infoEyeQAppCRC 4294967295;
BA_ "GenSigCycleTime" SG_ 1337 DAS_infoEyeQAppCRC 1000;
BA_ "GenSigStartValue" SG_ 1337 DAS_infoEyeQFfsCRC 4294967295;
BA_ "GenSigCycleTime" SG_ 1337 DAS_infoEyeQFfsCRC 1000;
BA_ "LogSignal" SG_ 777 DAS_leadVehDx "periodic ONE_SECOND driveModeModelS";
BA_ "LogSignal" SG_ 921 DAS_autopilotState "onChange";
BA_ "LogSignal" SG_ 921 DAS_autoparkReady "periodic ONE_SECOND driveModeModelS";
BA_ "LogSignal" SG_ 921 DAS_csaState "onChange";
BA_ "LogSignal" SG_ 921 DAS_autopilotHandsOnState "onChange";
BA_ "FieldType" SG_ 921 DAS_autopilotHandsOnState "LC_autopilotHandsOnState";
BA_ "LogSignal" SG_ 921 DAS_autoLaneChangeState "onChange";
BA_ "FieldType" SG_ 921 DAS_autoLaneChangeState "TP_autoLaneChangeState";
BA_ "LogSignal" SG_ 905 DAS_accSpeedLimit "onChange";
BA_ "FieldType" SG_ 905 DAS_pmmObstacleSeverity "PMM_obstacleSeverity";
BA_ "FieldType" SG_ 905 DAS_activationFailureStatus "LC_Activation";
BA_ "LogSignal" SG_ 905 DAS_pmmUltrasonicsFaultReason "periodic HALF_SECOND parkOocValid";
BA_ "FieldType" SG_ 905 DAS_pmmUltrasonicsFaultReason "PMM_ultrasonicsFaultReason";
BA_ "LogSignal" SG_ 905 DAS_pmmRadarFaultReason "periodic HALF_SECOND parkOocValid";
BA_ "FieldType" SG_ 905 DAS_pmmRadarFaultReason "PMM_radarFaultReason";
BA_ "LogSignal" SG_ 905 DAS_pmmSysFaultReason "periodic HALF_SECOND parkOocValid";
BA_ "FieldType" SG_ 905 DAS_pmmSysFaultReason "PMM_sysFaultReason";
BA_ "LogSignal" SG_ 905 DAS_pmmCameraFaultReason "periodic HALF_SECOND parkOocValid";
BA_ "FieldType" SG_ 905 DAS_pmmCameraFaultReason "PMM_cameraFaultReason";
BA_ "LogSignal" SG_ 905 DAS_ACC_report "onChange";
BA_ "FieldType" SG_ 905 DAS_ACC_report "ACC_Report";
BA_ "LogSignal" SG_ 905 DAS_TR_trigger "onChange";
BA_ "FieldType" SG_ 905 DAS_TR_trigger "DAS_TR_trigger";
BA_ "FieldType" SG_ 905 DAS_driverInteractionLevel "DAS_driverInteractionLevel";
BA_ "LogSignal" SG_ 905 DAS_ppOffsetDesiredRamp "periodic ONE_SECOND driveModeModelS";
BA_ "FieldType" SG_ 905 DAS_longCollisionWarning "FCM_longCollisionWarning";
BA_ "LogSignal" SG_ 1160 DAS_steeringAngleRequest "periodic ONE_SECOND driveModeModelS";
BA_ "LogSignal" SG_ 1160 DAS_steeringHapticRequest "onChange";
BA_ "FieldType" SG_ 1545 DAS_TR_Obj00_Class "DAS_radarObjClass";
BA_ "FieldType" SG_ 1545 DAS_TR_Obj00_MovingState "DAS_radarObjMovingState";
BA_ "GenSigSendType" SG_ 1625 DAS_udsResponseData 7;
BA_ "LogSignal" SG_ 585 DAS_plannerState "onChange";
BA_ "FieldType" SG_ 585 DAS_lastAutosteerAbortReason "DAS_lastAutosteerAbortReason";
BA_ "LogSignal" SG_ 585 DAS_accSmartSpeedState "onChange";
BA_ "GenSigSendType" SG_ 328 DI_ptcActive 1;
BA_ "GenSigSendType" SG_ 328 DI_regenTcActive 1;
BA_ "GenSigSendType" SG_ 872 DI_regenLight 1;
BA_ "FieldType" SG_ 872 DI_aebState "DI_aebState";
BA_ "GenSigStartValue" SG_ 872 DI_digitalSpeed 255;
BA_ "GenSigSNA" SG_ 1016 DI_parkBrakeState "15";
BA_ "FieldType" SG_ 1016 DI_parkBrakeState "DI_parkBrakeState";
BA_ "GenSigSNA" SG_ 1016 DI_pmmStatus "3";
BA_ "FieldType" SG_ 1016 DI_pmmStatus "DI_pmmStatus";
BA_ "GenSigStartValue" SG_ 264 DI_torqueDriver -4096;
BA_ "GenSigSendType" SG_ 264 DI_torqueDriver 7;
BA_ "GenSigCycleTime" SG_ 264 DI_torqueDriver 10;
BA_ "GenSigStartValue" SG_ 264 DI_pedalPos 255;
BA_ "GenSigSendType" SG_ 264 DI_pedalPos 7;
BA_ "GenSigCycleTime" SG_ 264 DI_pedalPos 10;
BA_ "GenSigSendType" SG_ 280 DI_gear 7;
BA_ "GenSigSNA" SG_ 280 DI_gear "7";
BA_ "GenSigCycleTime" SG_ 280 DI_gear 10;
BA_ "GenSigSendType" SG_ 280 DI_brakePedal 7;
BA_ "GenSigCycleTime" SG_ 280 DI_brakePedal 10;
BA_ "GenSigStartValue" SG_ 280 DI_vehicleSpeed 500;
BA_ "GenSigSendType" SG_ 280 DI_brakePedalState 7;
BA_ "GenSigSNA" SG_ 280 DI_brakePedalState "3";
BA_ "GenSigCycleTime" SG_ 280 DI_brakePedalState 10;
BA_ "LogSignal" SG_ 880 EPAS_torsionBarTorque "periodic ONE_SECOND driveModeModelS";
BA_ "LogSignal" SG_ 880 EPAS_internalSAS "periodic ONE_SECOND driveModeModelS";
BA_ "LogSignal" SG_ 880 EPAS_eacStatus "onChange";
BA_ "LogSignal" SG_ 516 EPB_state "onChange";
BA_ "FieldType" SG_ 516 EPB_state "EPB_state";
BA_ "LogSignal" SG_ 277 ESP_frontNegTorqueLimit "onChange";
BA_ "GenSigCycleTime" SG_ 277 ESP_frontNegTorqueLimit 10;
BA_ "FlexKomSigStartValue" SG_ 277 ESP_frontNegTorqueLimit "8000001FFFh";
BA_ "FlexKomSigStartPos" SG_ 277 ESP_frontNegTorqueLimit 15;
BA_ "FlexKomSigLaenge" SG_ 277 ESP_frontNegTorqueLimit 40;
BA_ "FlexKomSID" SG_ 277 ESP_frontNegTorqueLimit 33554835;
BA_ "FlexKomIsMotorola" SG_ 277 ESP_frontNegTorqueLimit 1;
BA_ "FlexKomComment" SG_ 277 ESP_frontNegTorqueLimit "Momentenanforderung ESP";
BA_ "LogSignal" SG_ 309 ESP_stabilityControlSts "onChange";
BA_ "LogSignal" SG_ 325 ESP_longitudinalAccel "periodic ONE_SECOND driveModeModelS";
BA_ "GenSigStartValue" SG_ 325 ESP_longitudinalAccel 512;
BA_ "LogSignal" SG_ 325 ESP_lateralAccel "periodic ONE_SECOND driveModeModelS";
BA_ "GenSigStartValue" SG_ 325 ESP_lateralAccel 512;
BA_ "LogSignal" SG_ 522 ESP_driverBrakeApply "onChange";
BA_ "GenSigStartValue" SG_ 522 ESP_yawRate 2000;
BA_ "LogSignal" SG_ 1048 GTW_chGotoSleep "onChange";
BA_ "GenSigStartValue" SG_ 776 AMB_TEMP 254;
BA_ "GenSigCycleTimeActive" SG_ 776 AMB_TEMP 100;
BA_ "GenSigCycleTime" SG_ 776 AMB_TEMP 100;
BA_ "GenSigCycleTimeActive" SG_ 776 GTW_ODO 100;
BA_ "GenSigCycleTime" SG_ 776 GTW_ODO 100;
BA_ "FieldType" SG_ 536 MCU_trailerModeCH "MCU_trailerMode";
BA_ "FieldType" SG_ 536 MCU_latControlEnable "MCU_latControlEnable";
BA_ "GenSigSNA" SG_ 536 MCU_ahlbEnable "3";
BA_ "FieldType" SG_ 1000 MCU_drivingSide "MCU_drivingSide";
BA_ "GenSigStartValue" SG_ 968 MCU_speedLimitDependency 7;
BA_ "GenSigSendType" SG_ 968 MCU_speedLimitDependency 1;
BA_ "GenSigSendType" SG_ 968 MCU_roadClass 1;
BA_ "GenSigSendType" SG_ 968 MCU_speedUnits 1;
BA_ "GenSigStartValue" SG_ 968 MCU_speedLimit 31;
BA_ "GenSigSendType" SG_ 968 MCU_speedLimit 1;
BA_ "GenSigSendType" SG_ 968 MCU_speedLimitType 1;
BA_ "GenSigStartValue" SG_ 968 MCU_countryCode 1023;
BA_ "GenSigSendType" SG_ 968 MCU_countryCode 1;
BA_ "GenSigStartValue" SG_ 760 MCU_gpsHDOP 255;
BA_ "GenSigSendType" SG_ 760 MCU_userSpeedOffset 1;
BA_ "GenSigSendType" SG_ 760 MCU_speedLimitUnits 1;
BA_ "GenSigSendType" SG_ 760 MCU_userSpeedOffsetUnits 1;
BA_ "GenSigSendType" SG_ 760 MCU_mppSpeedLimit 1;
BA_ "GenSigStartValue" SG_ 984 MCU_gpsAccuracy 127;
BA_ "LogSignal" SG_ 574 PARK_oocDistance "periodic HALF_SECOND parkOocValid";
BA_ "LogSignal" SG_ 574 PARK_oocConfidence "periodic HALF_SECOND parkOocValid";
BA_ "LogSignal" SG_ 574 PARK_oocCollisionSide "periodic HALF_SECOND parkOocValid";
BA_ "LogSignal" SG_ 574 PARK_oocUntrackedTime "periodic HALF_SECOND parkOocValid";
BA_ "LogSignal" SG_ 574 PARK_oocHeight "periodic HALF_SECOND parkOocValid";
BA_ "LogSignal" SG_ 574 PARK_oocOffCourse "periodic HALF_SECOND parkOocValid";
BA_ "GenSigStartValue" SG_ 798 PARK_majorVersion 255;
BA_ "GenSigStartValue" SG_ 798 PARK_minorVersion 255;
BA_ "GenSigStartValue" SG_ 798 PARK_subMinorVersion 255;
BA_ "LogSignal" SG_ 782 PARK_frontSVACharID "periodic TEN_SECONDS driveModeModelS";
BA_ "LogSignal" SG_ 782 PARK_pscRightCurbType "onChange";
BA_ "LogSignal" SG_ 782 PARK_rearSVACharID "periodic TEN_SECONDS driveModeModelS";
BA_ "LogSignal" SG_ 782 PARK_pscLeftCurbType "onChange";
BA_ "GenSigCycleTime" SG_ 1329 RADC_infoIndex 2000;
BA_ "FieldType" SG_ 1329 RADC_infoIndex "infoIndex";
BA_ "GenSigStartValue" SG_ 1329 RADC_infoApplicationCRC 4294967295;
BA_ "GenSigStartValue" SG_ 1329 RADC_infoPlatformType 255;
BA_ "GenSigSendType" SG_ 1665 RADC_udsResponseData 1;
BA_ "GenSigSendType" SG_ 1668 RADFL_udsResponseData 1;
BA_ "GenSigSendType" SG_ 1669 RADFR_udsResponseData 1;
BA_ "GenSigSendType" SG_ 1666 RADRL_udsResponseData 1;
BA_ "GenSigSendType" SG_ 1667 RADRR_udsResponseData 1;
BA_ "LogSignal" SG_ 17 RCM_rearCrash "onChange";
BA_ "LogSignal" SG_ 17 RCM_rightSideCrash "onChange";
BA_ "LogSignal" SG_ 17 RCM_leftSideCrash "onChange";
BA_ "LogSignal" SG_ 17 RCM_frontCrash "onChange";
BA_ "LogSignal" SG_ 17 RCM_chargerCrash "onChange";
BA_ "LogSignal" SG_ 17 RCM_pedProEvent "onChange";
BA_ "LogSignal" SG_ 17 RCM_rollOverCrash "onChange";
BA_ "LogSignal" SG_ 273 RCM_ndRearCollision "onChange";
BA_ "LogSignal" SG_ 273 RCM_ndRightSideCollision "onChange";
BA_ "LogSignal" SG_ 273 RCM_ndLeftSideCollision "onChange";
BA_ "LogSignal" SG_ 273 RCM_ndFrontCollision "onChange";
BA_ "LogSignal" SG_ 273 RCM_ndPedProEvent "onChange";
BA_ "LogSignal" SG_ 273 RCM_ndRollOverCollision "onChange";
BA_ "LogSignal" SG_ 529 RCM_tellTalePassengerState "onChange";
BA_ "GenSigStartValue" SG_ 529 RCM_tellTalePassengerState 3;
BA_ "LogSignal" SG_ 529 RCM_buckleDriverStatus "onChange";
BA_ "GenSigStartValue" SG_ 529 RCM_buckleDriverStatus 3;
BA_ "LogSignal" SG_ 109 TSL_P_Psd_StW "onChange";
BA_ "GenSigStartValue" SG_ 109 TSL_P_Psd_StW 2;
BA_ "GenSigSNA" SG_ 109 TSL_P_Psd_StW "3";
BA_ "GenSigCycleTime" SG_ 109 TSL_P_Psd_StW 10;
BA_ "FlexKomSigStartValue" SG_ 109 TSL_P_Psd_StW "00E600FFh";
BA_ "FlexKomSigStartPos" SG_ 109 TSL_P_Psd_StW 7;
BA_ "FlexKomSigName" SG_ 109 TSL_P_Psd_StW "SBW_Rq_SCCM";
BA_ "FlexKomSigLaenge" SG_ 109 TSL_P_Psd_StW 32;
BA_ "FlexKomSID" SG_ 109 TSL_P_Psd_StW 117441584;
BA_ "FlexKomIsMotorola" SG_ 109 TSL_P_Psd_StW 1;
BA_ "FlexKomComment" SG_ 109 TSL_P_Psd_StW "Shift by Wire request";
BA_ "LogSignal" SG_ 69 SpdCtrlLvr_Stat "onChange";
BA_ "GenSigTimeout_ESP_ABR" SG_ 69 SpdCtrlLvr_Stat 550;
BA_ "GenSigTimeout_CGW" SG_ 69 SpdCtrlLvr_Stat 1050;
BA_ "GenSigSendType" SG_ 69 SpdCtrlLvr_Stat 5;
BA_ "GenSigCycleTime" SG_ 69 SpdCtrlLvr_Stat 100;
BA_ "FlexKomSigStartValue" SG_ 69 SpdCtrlLvr_Stat "00FF0000000007FFh";
BA_ "FlexKomSigStartPos" SG_ 69 SpdCtrlLvr_Stat 7;
BA_ "FlexKomSigName" SG_ 69 SpdCtrlLvr_Stat "StW_Actn_Rq";
BA_ "FlexKomSigLaenge" SG_ 69 SpdCtrlLvr_Stat 64;
BA_ "FlexKomSID" SG_ 69 SpdCtrlLvr_Stat 117440568;
BA_ "FlexKomIsMotorola" SG_ 69 SpdCtrlLvr_Stat 1;
BA_ "FlexKomComment" SG_ 69 SpdCtrlLvr_Stat "Steering wheel actuation request";
BA_ "LogSignal" SG_ 69 VSL_Enbl_Rq "onChange";
BA_ "GenSigTimeout_MPC" SG_ 69 VSL_Enbl_Rq 1050;
BA_ "GenSigTimeout_ESP_ABR" SG_ 69 VSL_Enbl_Rq 550;
BA_ "GenSigTimeout_CGW" SG_ 69 VSL_Enbl_Rq 1050;
BA_ "GenSigSendType" SG_ 69 VSL_Enbl_Rq 5;
BA_ "GenSigCycleTime" SG_ 69 VSL_Enbl_Rq 100;
BA_ "FlexKomSigStartValue" SG_ 69 VSL_Enbl_Rq "00FF0000000007FFh";
BA_ "FlexKomSigStartPos" SG_ 69 VSL_Enbl_Rq 7;
BA_ "FlexKomSigName" SG_ 69 VSL_Enbl_Rq "StW_Actn_Rq";
BA_ "FlexKomSigLaenge" SG_ 69 VSL_Enbl_Rq 64;
BA_ "FlexKomSID" SG_ 69 VSL_Enbl_Rq 117440568;
BA_ "FlexKomIsMotorola" SG_ 69 VSL_Enbl_Rq 1;
BA_ "FlexKomComment" SG_ 69 VSL_Enbl_Rq "Steering wheel actuation request";
BA_ "LogSignal" SG_ 69 DTR_Dist_Rq "onChange";
BA_ "GenSigTimeout_ESP_ABR" SG_ 69 DTR_Dist_Rq 550;
BA_ "GenSigTimeout_CGW" SG_ 69 DTR_Dist_Rq 1050;
BA_ "GenSigStartValue" SG_ 69 DTR_Dist_Rq 255;
BA_ "GenSigSendType" SG_ 69 DTR_Dist_Rq 10;
BA_ "FlexKomSigStartValue" SG_ 69 DTR_Dist_Rq "00FF0000000007FFh";
BA_ "FlexKomSigStartPos" SG_ 69 DTR_Dist_Rq 7;
BA_ "FlexKomSigName" SG_ 69 DTR_Dist_Rq "StW_Actn_Rq";
BA_ "FlexKomSigLaenge" SG_ 69 DTR_Dist_Rq 64;
BA_ "FlexKomSID" SG_ 69 DTR_Dist_Rq 117440568;
BA_ "FlexKomIsMotorola" SG_ 69 DTR_Dist_Rq 1;
BA_ "FlexKomComment" SG_ 69 DTR_Dist_Rq "Steering wheel actuation request";
BA_ "GenSigTimeout_PTS" SG_ 69 TurnIndLvr_Stat 550;
BA_ "GenSigTimeout_MPC" SG_ 69 TurnIndLvr_Stat 1050;
BA_ "GenSigTimeout_ESP_ABR" SG_ 69 TurnIndLvr_Stat 550;
BA_ "GenSigTimeout_CGW" SG_ 69 TurnIndLvr_Stat 1050;
BA_ "GenSigSendType" SG_ 69 TurnIndLvr_Stat 5;
BA_ "GenSigSNA" SG_ 69 TurnIndLvr_Stat "3";
BA_ "GenSigCycleTime" SG_ 69 TurnIndLvr_Stat 100;
BA_ "FlexKomSigStartValue" SG_ 69 TurnIndLvr_Stat "00FF0000000007FFh";
BA_ "FlexKomSigStartPos" SG_ 69 TurnIndLvr_Stat 7;
BA_ "FlexKomSigName" SG_ 69 TurnIndLvr_Stat "StW_Actn_Rq";
BA_ "FlexKomSigLaenge" SG_ 69 TurnIndLvr_Stat 64;
BA_ "FlexKomSID" SG_ 69 TurnIndLvr_Stat 117440568;
BA_ "FlexKomIsMotorola" SG_ 69 TurnIndLvr_Stat 1;
BA_ "FlexKomComment" SG_ 69 TurnIndLvr_Stat "Steering wheel actuation request";
BA_ "GenSigTimeout_ESP_ABR" SG_ 69 HiBmLvr_Stat 550;
BA_ "GenSigTimeout_CGW" SG_ 69 HiBmLvr_Stat 1050;
BA_ "GenSigSendType" SG_ 69 HiBmLvr_Stat 5;
BA_ "GenSigSNA" SG_ 69 HiBmLvr_Stat "3";
BA_ "GenSigCycleTime" SG_ 69 HiBmLvr_Stat 100;
BA_ "FlexKomSigStartValue" SG_ 69 HiBmLvr_Stat "00FF0000000007FFh";
BA_ "FlexKomSigStartPos" SG_ 69 HiBmLvr_Stat 7;
BA_ "FlexKomSigName" SG_ 69 HiBmLvr_Stat "StW_Actn_Rq";
BA_ "FlexKomSigLaenge" SG_ 69 HiBmLvr_Stat 64;
BA_ "FlexKomSID" SG_ 69 HiBmLvr_Stat 117440568;
BA_ "FlexKomIsMotorola" SG_ 69 HiBmLvr_Stat 1;
BA_ "FlexKomComment" SG_ 69 HiBmLvr_Stat "Steering wheel actuation request";
BA_ "GenSigTimeout_MPC" SG_ 69 WprWashSw_Psd 1050;
BA_ "GenSigTimeout_ESP_ABR" SG_ 69 WprWashSw_Psd 550;
BA_ "GenSigTimeout_CGW" SG_ 69 WprWashSw_Psd 1050;
BA_ "GenSigSendType" SG_ 69 WprWashSw_Psd 5;
BA_ "GenSigSNA" SG_ 69 WprWashSw_Psd "3";
BA_ "GenSigCycleTime" SG_ 69 WprWashSw_Psd 100;
BA_ "FlexKomSigStartValue" SG_ 69 WprWashSw_Psd "00FF0000000007FFh";
BA_ "FlexKomSigStartPos" SG_ 69 WprWashSw_Psd 7;
BA_ "FlexKomSigName" SG_ 69 WprWashSw_Psd "StW_Actn_Rq";
BA_ "FlexKomSigLaenge" SG_ 69 WprWashSw_Psd 64;
BA_ "FlexKomSID" SG_ 69 WprWashSw_Psd 117440568;
BA_ "FlexKomIsMotorola" SG_ 69 WprWashSw_Psd 1;
BA_ "FlexKomComment" SG_ 69 WprWashSw_Psd "Steering wheel actuation request";
BA_ "GenSigTimeout_ESP_ABR" SG_ 14 StW_AnglHP 155;
BA_ "GenSigStartValue" SG_ 14 StW_AnglHP 16383;
BA_ "GenSigCycleTime" SG_ 14 StW_AnglHP 10;
BA_ "FlexKomSigStartValue" SG_ 14 StW_AnglHP "3FFF3FFF03FF00FFh";
BA_ "FlexKomSigStartPos" SG_ 14 StW_AnglHP 7;
BA_ "FlexKomSigName" SG_ 14 StW_AnglHP "StW_AnglHP_Stat";
BA_ "FlexKomSigLaenge" SG_ 14 StW_AnglHP 64;
BA_ "FlexKomSID" SG_ 14 StW_AnglHP 117443381;
BA_ "FlexKomIsMotorola" SG_ 14 StW_AnglHP 1;
BA_ "FlexKomComment" SG_ 14 StW_AnglHP "Steering wheel angle with high precision state";
BA_ "GenSigTimeout_ESP_ABR" SG_ 14 StW_AnglHP_Spd 155;
BA_ "GenSigStartValue" SG_ 14 StW_AnglHP_Spd 8192;
BA_ "GenSigCycleTime" SG_ 14 StW_AnglHP_Spd 10;
BA_ "FlexKomSigStartValue" SG_ 14 StW_AnglHP_Spd "3FFF3FFF03FF00FFh";
BA_ "FlexKomSigStartPos" SG_ 14 StW_AnglHP_Spd 7;
BA_ "FlexKomSigName" SG_ 14 StW_AnglHP_Spd "StW_AnglHP_Stat";
BA_ "FlexKomSigLaenge" SG_ 14 StW_AnglHP_Spd 64;
BA_ "FlexKomSID" SG_ 14 StW_AnglHP_Spd 117443381;
BA_ "FlexKomIsMotorola" SG_ 14 StW_AnglHP_Spd 1;
BA_ "FlexKomComment" SG_ 14 StW_AnglHP_Spd "Steering wheel angle with high precision state";
BA_ "GenSigTimeout_ESP_ABR" SG_ 14 StW_AnglHP_Sens_Stat 155;
BA_ "GenSigStartValue" SG_ 14 StW_AnglHP_Sens_Stat 3;
BA_ "GenSigCycleTime" SG_ 14 StW_AnglHP_Sens_Stat 10;
BA_ "FlexKomSigStartValue" SG_ 14 StW_AnglHP_Sens_Stat "3FFF3FFF03FF00FFh";
BA_ "FlexKomSigStartPos" SG_ 14 StW_AnglHP_Sens_Stat 7;
BA_ "FlexKomSigName" SG_ 14 StW_AnglHP_Sens_Stat "StW_AnglHP_Stat";
BA_ "FlexKomSigLaenge" SG_ 14 StW_AnglHP_Sens_Stat 64;
BA_ "FlexKomSID" SG_ 14 StW_AnglHP_Sens_Stat 117443381;
BA_ "FlexKomIsMotorola" SG_ 14 StW_AnglHP_Sens_Stat 1;
BA_ "FlexKomComment" SG_ 14 StW_AnglHP_Sens_Stat "Steering wheel angle with high precision state";
BA_ "FieldType" SG_ 539 TAS_currentLevel "suspLevel";
BA_ "GenSigSendType" SG_ 1609 UDS_dasRequestData 7;
BA_ "GenSigSendType" SG_ 2015 UDS_functionalRequestData_0 1;
BA_ "GenSigSendType" SG_ 2015 UDS_functionalRequestData_1 1;
BA_ "GenSigSendType" SG_ 2015 UDS_functionalRequestData_2 1;
BA_ "GenSigSendType" SG_ 2015 UDS_functionalRequestData_3 1;
BA_ "GenSigSendType" SG_ 2015 UDS_functionalRequestData_4 1;
BA_ "GenSigSendType" SG_ 2015 UDS_functionalRequestData_5 1;
BA_ "GenSigSendType" SG_ 2015 UDS_functionalRequestData_6 1;
BA_ "GenSigSendType" SG_ 2015 UDS_functionalRequestData_7 1;
BA_ "GenSigSendType" SG_ 1649 UDS_radcRequestData 1;
BA_ "GenSigCycleTimeActive" SG_ 1029 EPASParamMux 100;
BA_ "GenSigCycleTime" SG_ 1029 EPASParamMux 100;
VAL_ 1337 DAS_infoIndex 255 "DAS_INFO_END" 24 "DAS_INFO_EYEQ_FFS" 23 "DAS_INFO_EYEQ_APP" 20 "DAS_INFO_UDS_PROTOCOL_BOOTCRC" 19 "DAS_INFO_VERSION_DEPRECATED" 18 "DAS_INFO_BOOTLOADER_GITHASH" 17 "DAS_INFO_APP_GITHASH" 16 "DAS_INFO_EYEQ_BOOT" 15 "DAS_INFO_BOOTLOADER_CRC" 14 "DAS_INFO_BOOTLOADER_SVN" 13 "DAS_INFO_APP_CRC" 11 "DAS_INFO_PCBAID_ASSYID_USAGEID" 10 "DAS_INFO_BUILD_HWID_COMPONENTID" 9 "DAS_INFO_DEPRECATED_9" 8 "DAS_INFO_DEPRECATED_8" 7 "DAS_INFO_DEPRECATED_7" 6 "DAS_INFO_DEPRECATED_6" 5 "DAS_INFO_DEPRECATED_5" 4 "DAS_INFO_DEPRECATED_4" 3 "DAS_INFO_DEPRECATED_3" 2 "DAS_INFO_DEPRECATED_2" 1 "DAS_INFO_DEPRECATED_1" 0 "DAS_INFO_DEPRECATED_0" ;
VAL_ 1337 DAS_infoHardwareRevision 252 "CONFIGURABLE_HWID_PLACEHOLDER" ;
VAL_ 665 DAS_timeToImpactFront 511 "SNA" ;
VAL_ 665 DAS_timeToImpactFrontQF 1 "NOT_FAULTED" 0 "FAULTED" ;
VAL_ 665 DAS_relativeAccelFrontSign 1 "NEGATIVE" 0 "POSITIVE" ;
VAL_ 665 DAS_relativeVelocityFrontSign 1 "NEGATIVE" 0 "POSITIVE" ;
VAL_ 665 DAS_closingVelocityFront 15 "SNA" ;
VAL_ 665 DAS_closingVelocityFrontQF 1 "NOT_FAULTED" 0 "FAULTED" ;
VAL_ 665 DAS_targetDistanceFront 127 "SNA" ;
VAL_ 665 DAS_targetDistanceFrontQF 1 "NOT_FAULTED" 0 "FAULTED" ;
VAL_ 665 DAS_relativeVelocityFront 31 "SNA" ;
VAL_ 665 DAS_relativeVelocityFrontQF 1 "NOT_FAULTED" 0 "FAULTED" ;
VAL_ 665 DAS_relativeAccelerationFront 127 "SNA" ;
VAL_ 665 DAS_relativeAccelerationFrontQF 1 "NOT_FAULTED" 0 "FAULTED" ;
VAL_ 665 DAS_forwardCollisionWarning_RCM 3 "SNA" 1 "FORWARD_COLLISION_WARNING" 0 "NONE" ;
VAL_ 569 DAS_leftLineType 15 "SNA" 6 "BARRIER" 5 "BOTTS_DOTS" 4 "DOUBLE_LANE" 3 "DASHED" 2 "ROAD_EDGE" 1 "SOLID" 0 "UNDECIDED" ;
VAL_ 569 DAS_rightLineType 15 "SNA" 6 "BARRIER" 5 "BOTTS_DOTS" 4 "DOUBLE_LANE" 3 "DASHED" 2 "ROAD_EDGE" 1 "SOLID" 0 "UNDECIDED" ;
VAL_ 569 DAS_leftLineQuality 3 "HIGH" 2 "MEDIUM" 1 "LOW" 0 "LOWEST" ;
VAL_ 569 DAS_rightLineQuality 3 "HIGH" 2 "MEDIUM" 1 "LOW" 0 "LOWEST" ;
VAL_ 777 DAS_objectId 5 "VEHICLE_HEADINGS" 4 "ROAD_SIGN" 3 "CUTIN_VEHICLE" 2 "RIGHT_VEHICLES" 1 "LEFT_VEHICLES" 0 "LEAD_VEHICLES" ;
VAL_ 777 DAS_leadVehType 6 "IPSO" 5 "PEDESTRIAN" 4 "BICYCLE" 3 "MOTORCYCLE" 2 "CAR" 1 "TRUCK" 0 "UNKNOWN" ;
VAL_ 777 DAS_leadVehDx 255 "SNA" ;
VAL_ 777 DAS_leadVehVxRel 15 "SNA" ;
VAL_ 777 DAS_leadVehDy 127 "SNA" ;
VAL_ 777 DAS_leadVehId 127 "SNA" ;
VAL_ 777 DAS_leadVeh2Type 5 "PEDESTRIAN" 4 "BICYCLE" 3 "MOTORCYCLE" 2 "CAR" 1 "TRUCK" 0 "UNKNOWN" ;
VAL_ 777 DAS_leadVeh2Dx 255 "SNA" ;
VAL_ 777 DAS_leadVeh2VxRel 15 "SNA" ;
VAL_ 777 DAS_leadVeh2Dy 127 "SNA" ;
VAL_ 777 DAS_leadVeh2Id 0 "SNA" ;
VAL_ 777 DAS_leftVehType 5 "PEDESTRIAN" 4 "BICYCLE" 3 "MOTORCYCLE" 2 "CAR" 1 "TRUCK" 0 "UNKNOWN" ;
VAL_ 777 DAS_leftVehDx 255 "SNA" ;
VAL_ 777 DAS_leftVehVxRel 15 "SNA" ;
VAL_ 777 DAS_leftVehDy 127 "SNA" ;
VAL_ 777 DAS_leftVehId 127 "SNA" ;
VAL_ 777 DAS_leftVeh2Type 5 "PEDESTRIAN" 4 "BICYCLE" 3 "MOTORCYCLE" 2 "CAR" 1 "TRUCK" 0 "UNKNOWN" ;
VAL_ 777 DAS_leftVeh2Dx 255 "SNA" ;
VAL_ 777 DAS_leftVeh2VxRel 15 "SNA" ;
VAL_ 777 DAS_leftVeh2Dy 127 "SNA" ;
VAL_ 777 DAS_leftVeh2Id 0 "SNA" ;
VAL_ 777 DAS_rightVehType 5 "PEDESTRIAN" 4 "BICYCLE" 3 "MOTORCYCLE" 2 "CAR" 1 "TRUCK" 0 "UNKNOWN" ;
VAL_ 777 DAS_rightVehDx 255 "SNA" ;
VAL_ 777 DAS_rightVehVxRel 15 "SNA" ;
VAL_ 777 DAS_rightVehDy 127 "SNA" ;
VAL_ 777 DAS_rightVehId 127 "SNA" ;
VAL_ 777 DAS_rightVeh2Type 5 "PEDESTRIAN" 4 "BICYCLE" 3 "MOTORCYCLE" 2 "CAR" 1 "TRUCK" 0 "UNKNOWN" ;
VAL_ 777 DAS_rightVeh2Dx 255 "SNA" ;
VAL_ 777 DAS_rightVeh2VxRel 15 "SNA" ;
VAL_ 777 DAS_rightVeh2Dy 127 "SNA" ;
VAL_ 777 DAS_rightVeh2Id 0 "SNA" ;
VAL_ 777 DAS_cutinVehType 5 "PEDESTRIAN" 4 "BICYCLE" 3 "MOTORCYCLE" 2 "CAR" 1 "TRUCK" 0 "UNKNOWN" ;
VAL_ 777 DAS_cutinVehDx 255 "SNA" ;
VAL_ 777 DAS_cutinVehVxRel 15 "SNA" ;
VAL_ 777 DAS_cutinVehDy 127 "SNA" ;
VAL_ 777 DAS_cutinVehId 127 "SNA" ;
VAL_ 777 DAS_roadSignColor 4 "RED_YELLOW" 3 "GREEN" 2 "YELLOW" 1 "RED" 0 "NONE" ;
VAL_ 777 DAS_roadSignId 255 "SNA" 1 "TRAFFIC_LIGHT" 0 "STOP_SIGN" ;
VAL_ 777 DAS_roadSignStopLineDist 1023 "SNA" ;
VAL_ 777 DAS_roadSignSource 2 "VISION" 1 "NAV" 0 "NONE" ;
VAL_ 777 DAS_roadSignArrow 4 "UNKNOWN" 3 "STRAIGHT" 2 "RIGHT" 1 "LEFT" 0 "CIRCLE" ;
VAL_ 777 DAS_roadSignOrientation 2 "HORIZONTAL_3_LIGHT" 1 "VERTICAL_3_LIGHT" 0 "UNKNOWN" ;
VAL_ 777 DAS_leadVehHeading 255 "SNA" ;
VAL_ 777 DAS_leadVeh2Heading 255 "SNA" ;
VAL_ 777 DAS_leftVehHeading 255 "SNA" ;
VAL_ 777 DAS_leftVeh2Heading 255 "SNA" ;
VAL_ 777 DAS_rightVehHeading 255 "SNA" ;
VAL_ 777 DAS_rightVeh2Heading 255 "SNA" ;
VAL_ 777 DAS_cutinVehHeading 255 "SNA" ;
VAL_ 537 DAS_pscParkState 15 "SNA" 14 "SUMMON" 10 "PAUSE" 9 "SEARCH" 8 "COMPLETE" 7 "ABORT" 6 "PARALLEL_PULL_OUT_TO_RIGHT" 5 "PARALLEL_PULL_OUT_TO_LEFT" 4 "PARK_RIGHT_CROSS" 3 "PARK_RIGHT_PARALLEL" 2 "PARK_LEFT_CROSS" 1 "PARK_LEFT_PARALLEL" 0 "NONE" ;
VAL_ 1025 DAS_robDebugMultiplexer 5 "ROB_MAP_DEBUG" 4 "ROB_GENERAL_DEBUG" 3 "ROB_EOBJ_03" 2 "ROB_EOBJ_02" 1 "ROB_EOBJ_01" 0 "ROB_EOBJ_00" ;
VAL_ 1025 DAS_robState 2 "ROB_STATE_ACTIVE" 1 "ROB_STATE_MEASURE" 0 "ROB_STATE_INHIBITED" ;
VAL_ 1025 DAS_robOverlapObstacle 255 "NO_OVERLAP" ;
VAL_ 1025 DAS_robTimeCollision 255 "NO_COLLISION" ;
VAL_ 921 DAS_autopilotState 15 "SNA" 14 "FAULT" 9 "ABORTED" 8 "ABORTING" 4 "ACTIVE_RESTRICTED" 3 "ACTIVE_NOMINAL" 2 "AVAILABLE" 1 "UNAVAILABLE" 0 "DISABLED" ;
VAL_ 921 DAS_blindSpotRearLeft 3 "SNA" 2 "WARNING_LEVEL_2" 1 "WARNING_LEVEL_1" 0 "NO_WARNING" ;
VAL_ 921 DAS_blindSpotRearRight 3 "SNA" 2 "WARNING_LEVEL_2" 1 "WARNING_LEVEL_1" 0 "NO_WARNING" ;
VAL_ 921 DAS_fusedSpeedLimit 31 "NONE" 0 "UNKNOWN_SNA" ;
VAL_ 921 DAS_suppressSpeedWarning 1 "Suppress_Speed_Warning" 0 "Do_Not_Suppress" ;
VAL_ 921 DAS_visionOnlySpeedLimit 31 "NONE" 0 "UNKNOWN_SNA" ;
VAL_ 921 DAS_heaterState 1 "HEATER_ON" 0 "HEATER_OFF_SNA" ;
VAL_ 921 DAS_forwardCollisionWarning 3 "SNA" 1 "FORWARD_COLLISION_WARNING" 0 "NONE" ;
VAL_ 921 DAS_autoparkReady 1 "AUTOPARK_READY" 0 "AUTOPARK_UNAVAILABLE" ;
VAL_ 921 DAS_sideCollisionAvoid 3 "SNA" 2 "AVOID_RIGHT" 1 "AVOID_LEFT" 0 "NONE" ;
VAL_ 921 DAS_sideCollisionWarning 3 "WARN_LEFT_RIGHT" 2 "WARN_RIGHT" 1 "WARN_LEFT" 0 "NONE" ;
VAL_ 921 DAS_sideCollisionInhibit 1 "INHIBIT" 0 "NO_INHIBIT" ;
VAL_ 921 DAS_csaState 3 "CSA_EXTERNAL_STATE_HOLD" 2 "CSA_EXTERNAL_STATE_ENABLE" 1 "CSA_EXTERNAL_STATE_AVAILABLE" 0 "CSA_EXTERNAL_STATE_UNAVAILABLE" ;
VAL_ 921 DAS_laneDepartureWarning 5 "SNA" 4 "RIGHT_WARNING_SEVERE" 3 "LEFT_WARNING_SEVERE" 2 "RIGHT_WARNING" 1 "LEFT_WARNING" 0 "NONE" ;
VAL_ 921 DAS_autopilotHandsOnState 15 "LC_HANDS_ON_SNA" 7 "LC_HANDS_ON_REQD_STRUCK_OUT" 5 "LC_HANDS_ON_REQD_CHIME_2" 4 "LC_HANDS_ON_REQD_CHIME_1" 3 "LC_HANDS_ON_REQD_VISUAL" 2 "LC_HANDS_ON_REQD_NOT_DETECTED" 1 "LC_HANDS_ON_REQD_DETECTED" 0 "LC_HANDS_ON_NOT_REQD" ;
VAL_ 921 DAS_autoLaneChangeState 31 "ALC_SNA" 21 "ALC_UNAVAILABLE_SOLID_LANE_LINE" 20 "ALC_ABORT_OTHER_REASON" 19 "ALC_ABORT_BLINKER_TURNED_OFF" 18 "ALC_ABORT_LC_HEALTH_BAD" 17 "ALC_ABORT_POOR_VIEW_RANGE" 16 "ALC_ABORT_SIDE_OBSTACLE_PRESENT_R" 15 "ALC_ABORT_SIDE_OBSTACLE_PRESENT_L" 14 "ALC_WAITING_FOR_FWD_OBST_TO_PASS_R" 13 "ALC_WAITING_FOR_FWD_OBST_TO_PASS_L" 12 "ALC_WAITING_FOR_SIDE_OBST_TO_PASS_R" 11 "ALC_WAITING_FOR_SIDE_OBST_TO_PASS_L" 10 "ALC_IN_PROGRESS_R" 9 "ALC_IN_PROGRESS_L" 8 "ALC_AVAILABLE_BOTH" 7 "ALC_AVAILABLE_ONLY_R" 6 "ALC_AVAILABLE_ONLY_L" 5 "ALC_UNAVAILABLE_VEHICLE_SPEED" 4 "ALC_UNAVAILABLE_EXITING_HIGHWAY" 3 "ALC_UNAVAILABLE_TP_FOLLOW" 2 "ALC_UNAVAILABLE_SONICS_INVALID" 1 "ALC_UNAVAILABLE_NO_LANES" 0 "ALC_UNAVAILABLE_DISABLED" ;
VAL_ 905 DAS_accSpeedLimit 1023 "SNA" 0 "NONE" ;
VAL_ 905 DAS_pmmObstacleSeverity 7 "PMM_SNA" 5 "PMM_CRASH_FRONT" 4 "PMM_CRASH_REAR" 3 "PMM_BRAKE_REQUEST" 2 "PMM_IMMINENT_FRONT" 1 "PMM_IMMINENT_REAR" 0 "PMM_NONE" ;
VAL_ 905 DAS_pmmLoggingRequest 1 "TRUE" 0 "FALSE" ;
VAL_ 905 DAS_activationFailureStatus 2 "LC_ACTIVATION_FAILED_2" 1 "LC_ACTIVATION_FAILED_1" 0 "LC_ACTIVATION_IDLE" ;
VAL_ 905 DAS_pmmUltrasonicsFaultReason 4 "PMM_ULTRASONICS_INVALID_MIA" 3 "PMM_ULTRASONICS_BLOCKED_BOTH" 2 "PMM_ULTRASONICS_BLOCKED_REAR" 1 "PMM_ULTRASONICS_BLOCKED_FRONT" 0 "PMM_ULTRASONICS_NO_FAULT" ;
VAL_ 905 DAS_pmmRadarFaultReason 2 "PMM_RADAR_INVALID_MIA" 1 "PMM_RADAR_BLOCKED_FRONT" 0 "PMM_RADAR_NO_FAULT" ;
VAL_ 905 DAS_pmmSysFaultReason 7 "PMM_FAULT_BRAKE_PEDAL_INHIBIT" 6 "PMM_FAULT_ROAD_TYPE" 5 "PMM_FAULT_DISABLED_BY_USER" 4 "PMM_FAULT_STEERING_ANGLE_RATE" 3 "PMM_FAULT_DI_FAULT" 2 "PMM_FAULT_SPEED" 1 "PMM_FAULT_DAS_DISABLED" 0 "PMM_FAULT_NONE" ;
VAL_ 905 DAS_pmmCameraFaultReason 2 "PMM_CAMERA_INVALID_MIA" 1 "PMM_CAMERA_BLOCKED_FRONT" 0 "PMM_CAMERA_NO_FAULT" ;
VAL_ 905 DAS_ACC_report 22 "ACC_REPORT_RADAR_OBJ_FIVE" 21 "ACC_REPORT_CIPV_CUTTING_OUT" 20 "ACC_REPORT_MCVLR_IN_PATH" 19 "ACC_REPORT_MCVLR_DPP" 18 "ACC_REPORT_FLEET_SPEEDS" 17 "ACC_REPORT_TARGET_MCP" 16 "ACC_REPORT_RADAR_OBJ_TWO" 15 "ACC_REPORT_RADAR_OBJ_ONE" 14 "ACC_REPORT_LC_EXTERNAL_STATE_ACTIVE_RESTRICTED" 13 "ACC_REPORT_LC_EXTERNAL_STATE_ABORTED" 12 "ACC_REPORT_LC_EXTERNAL_STATE_ABORTING" 11 "ACC_REPORT_LC_HANDS_ON_REQD_STRUCK_OUT" 10 "ACC_REPORT_CSA" 9 "ACC_REPORT_TARGET_TYPE_FAULT" 8 "ACC_REPORT_TARGET_TYPE_IPSO" 7 "ACC_REPORT_TARGET_TYPE_TRAFFIC_LIGHT" 6 "ACC_REPORT_TARGET_TYPE_STOP_SIGN" 5 "ACC_REPORT_TARGET_CUTIN" 4 "ACC_REPORT_TARGET_MCVR" 3 "ACC_REPORT_TARGET_MCVL" 2 "ACC_REPORT_TARGET_IN_FRONT_OF_CIPV" 1 "ACC_REPORT_TARGET_CIPV" 0 "ACC_REPORT_TARGET_NONE" ;
VAL_ 905 DAS_TR_trigger 1 "WRITE_RADAR_TELEMETRY" 0 "RADAR_TELEMETRY_IDLE" ;
VAL_ 905 DAS_driverInteractionLevel 2 "CONTINUED_DRIVER_NOT_INTERACTING" 1 "DRIVER_NOT_INTERACTING" 0 "DRIVER_INTERACTING" ;
VAL_ 905 DAS_ppOffsetDesiredRamp 128 "PP_NO_OFFSET" ;
VAL_ 905 DAS_longCollisionWarning 15 "FCM_LONG_COLLISION_WARNING_SNA" 12 "FCM_LONG_COLLISION_WARNING_VEHICLE_CIPV2" 11 "FCM_LONG_COLLISION_WARNING_VEHICLE_MCVR2" 10 "FCM_LONG_COLLISION_WARNING_VEHICLE_MCVR" 9 "FCM_LONG_COLLISION_WARNING_VEHICLE_MCVL2" 8 "FCM_LONG_COLLISION_WARNING_VEHICLE_MCVL" 7 "FCM_LONG_COLLISION_WARNING_VEHICLE_CUTIN" 6 "FCM_LONG_COLLISION_WARNING_VEHICLE_CIPV" 5 "FCM_LONG_COLLISION_WARNING_TFL_STOPLINE" 4 "FCM_LONG_COLLISION_WARNING_STOPSIGN_STOPLINE" 3 "FCM_LONG_COLLISION_WARNING_IPSO" 2 "FCM_LONG_COLLISION_WARNING_PEDESTRIAN" 1 "FCM_LONG_COLLISION_WARNING_VEHICLE_UNKNOWN" 0 "FCM_LONG_COLLISION_WARNING_NONE" ;
VAL_ 1160 DAS_steeringAngleRequest 16384 "ZERO_ANGLE" ;
VAL_ 1160 DAS_steeringHapticRequest 1 "HAPTIC_ACTIVE" 0 "HAPTIC_IDLE" ;
VAL_ 1160 DAS_steeringControlType 3 "DISABLED" 2 "RESERVED" 1 "ANGLE_CONTROL" 0 "NONE" ;
VAL_ 937 DAS_telemetryMultiplexer 9 "DAS_TELEMETRY_CRUISE_STALK_INPUT" 8 "DAS_TELEMETRY_STATIONARY_OBST" 7 "DAS_TELEMETRY_CSA_EVENT" 2 "DAS_TELEMETRY_TRAFFIC_SIGNS" 1 "DAS_TELEMETRY_ACC_DRIVER_MONITOR" 0 "DAS_TELEMETRY_ROAD_INFORMATION" ;
VAL_ 937 DAS_telLeftLaneType 6 "BARRIER" 5 "BOTTS DOTS" 4 "DOUBLE" 3 "DASHED" 2 "ROAD EDGE" 1 "SOLID" 0 "UNDECIDED" ;
VAL_ 937 DAS_telRightLaneType 6 "BARRIER" 5 "BOTTS DOTS" 4 "DOUBLE" 3 "DASHED" 2 "ROAD EDGE" 1 "SOLID" 0 "UNDECIDED" ;
VAL_ 937 DAS_telLeftMarkerQuality 3 "HIGH" 2 "MEDIUM" 1 "LOW" 0 "LOWEST" ;
VAL_ 937 DAS_telRightMarkerQuality 3 "HIGH" 2 "MEDIUM" 1 "LOW" 0 "LOWEST" ;
VAL_ 937 DAS_telLeftMarkerColor 3 "BLUE" 2 "YELLOW" 1 "WHITE" 0 "UNKNOWN" ;
VAL_ 937 DAS_telRightMarkerColor 3 "BLUE" 2 "YELLOW" 1 "WHITE" 0 "UNKNOWN" ;
VAL_ 937 DAS_telLeftLaneCrossing 1 "CROSSING" 0 "NOT_CROSSING" ;
VAL_ 937 DAS_telRightLaneCrossing 1 "CROSSING" 0 "NOT_CROSSING" ;
VAL_ 937 DAS_stopSignLongitudinalDist 1023 "SNA" ;
VAL_ 937 DAS_stopSignLateralDist 255 "SNA" ;
VAL_ 937 DAS_stopSignHeight 63 "SNA" ;
VAL_ 937 DAS_stopSignStopLineDistance 1023 "SNA" ;
VAL_ 937 DAS_stopSignCIPVDistance 63 "SNA" ;
VAL_ 937 DAS_stopSignHostAccel 1023 "SNA" ;
VAL_ 937 DAS_csaIntState 4 "CSA_INTERNAL_STATE_ENABLE_HOLD" 3 "CSA_INTERNAL_STATE_ENABLE_ACCELEROMETER" 2 "CSA_INTERNAL_STATE_ENABLE_PREDICTED" 1 "CSA_INTERNAL_STATE_AVAILABLE" 0 "CSA_INTERNAL_STATE_UNAVAILABLE" ;
VAL_ 937 DAS_soCamCipvStatus 3 "CAM_CIPV_FUSED_W_RAD5" 2 "CAM_CIPV_FUSED_W_OTHER_RAD_OBJ" 1 "CAM_CIPV_UNFUSED" 0 "CAM_CIPV_INVALID" ;
VAL_ 937 DAS_soRad5Status 3 "RAD5_FUSED_W_OTHER_CAMOBJ" 2 "RAD5_FUSED_W_CIPV" 1 "RAD5_UNFUSED" 0 "RAD5_INVALID" ;
VAL_ 937 DAS_soRad1Status 3 "RAD1_FUSED_W_OTHER_CAMOBJ" 2 "RAD1_FUSED_W_CIPV" 1 "RAD1_UNFUSED" 0 "RAD1_INVALID" ;
VAL_ 985 DAS_TE_multiplexer 9 "END" 8 "IPSO" 7 "FCM" 6 "ACC" 5 "VL" 4 "NAV" 3 "HPP" 2 "RIGHT_LANE" 1 "LEFT_LANE" 0 "START" ;
VAL_ 985 DAS_TE_eventType 14 "TM_EVENT_ROB" 13 "TM_EVENT_AEB" 12 "TM_EVENT_CRASH" 11 "TM_EVENT_IPSO" 10 "SCA_RIGHT" 9 "SCA_LEFT" 8 "ALC_ABORT_RIGHT" 7 "ALC_ABORT_LEFT" 6 "LDW_RIGHT" 5 "LDW_LEFT" 4 "ANGLE_RATE_SATURATION" 3 "ANGLE_SATURATION" 2 "AUTOSTEER_ABORT" 1 "DRIVER_INTERVENTION" 0 "NONE" ;
VAL_ 985 DAS_TE_lcAbortReason 31 "NO_ABORT" 30 "CAMERA_FAILSAFES" 29 "ACC_CANCEL" 28 "EPAS_ERROR_CODE" 27 "PLANNER_OUTPUT_INVALID" 26 "FOLLOWER_OUTPUT_INVALID" 25 "VEHICLE_SPEED_ABOVE_MAX" 24 "DRIVING_OFF_NAV" 23 "CID_SWITCH_DISABLED" 22 "CRUISE_FAULT" 21 "COMPONENT_MIA" 20 "EPAS_EAC_DENIED" 19 "SIDE_COLLISION_IMMINENT" 18 "TRAILER_MODE" 17 "CAM_WATCHDOG" 16 "CAM_MSG_MIA" 1 "HM_VIRTUAL_LANE_NO_INPUTS" 0 "HM_LANE_VIEW_RANGE" ;
VAL_ 945 DAS_TF_multiplexer 2 "TFL_DATA" 1 "FURNITURE_DATA" 0 "ENVIRONMENT_DATA" ;
VAL_ 945 DAS_TF_llType 7 "INVALID" 6 "BARRIER" 5 "BOTTS_DOTS" 4 "DOUBLE_LANE" 3 "DASHED" 2 "ROAD_EDGE" 1 "SOLID" 0 "UNDECIDED" ;
VAL_ 945 DAS_TF_rlType 7 "INVALID" 6 "BARRIER" 5 "BOTTS_DOTS" 4 "DOUBLE_LANE" 3 "DASHED" 2 "ROAD_EDGE" 1 "SOLID" 0 "UNDECIDED" ;
VAL_ 945 DAS_TF_cipvDist 511 "SNA" ;
VAL_ 945 DAS_TF_transmissionStatus 2 "FINAL" 1 "INTERMEDIATE" 0 "INITIAL" ;
VAL_ 889 DAS_TP_multiplexer 9 "END" 8 "LANE_INFO" 7 "RIGHT_BOTTS_DOTS" 6 "LEFT_BOTTS_DOTS" 5 "VIRTUAL_LANE" 4 "NAV" 3 "HPP" 2 "RIGHT_LANE" 1 "LEFT_LANE" 0 "START" ;
VAL_ 889 DAS_TP_laneChange 2 "RIGHT" 1 "LEFT" 0 "NONE" ;
VAL_ 889 DAS_TP_llType 7 "INVALID" 6 "BARRIER" 5 "BOTTS_DOTS" 4 "DOUBLE_LANE" 3 "DASHED" 2 "ROAD_EDGE" 1 "SOLID" 0 "UNDECIDED" ;
VAL_ 889 DAS_TP_rlType 7 "INVALID" 6 "BARRIER" 5 "BOTTS_DOTS" 4 "DOUBLE_LANE" 3 "DASHED" 2 "ROAD_EDGE" 1 "SOLID" 0 "UNDECIDED" ;
VAL_ 889 DAS_TP_plannerState 7 "LANECHANGE_ABORT" 6 "LANECHANGE_WAIT_FOR_FWD_OBSTACLE" 5 "LANECHANGE_WAIT_FOR_SIDE_OBSTACLE" 4 "LANECHANGE_IN_PROGRESS" 3 "LANECHANGE_REQUESTED" 2 "FOLLOW" 1 "VIRTUAL_LANE" 0 "DISABLED" ;
VAL_ 889 DAS_TP_lcState 15 "SNA" 14 "FAULT" 9 "ABORTED" 8 "ABORTING" 4 "ACTIVE_RESTRICTED" 3 "ACTIVE_NOMINAL" 2 "AVAILABLE" 1 "UNAVAILABLE" 0 "DISABLED" ;
VAL_ 889 DAS_TP_llQltyME 3 "HIGH" 2 "MEDIUM" 1 "LOW" 0 "LOWEST" ;
VAL_ 889 DAS_TP_rlQltyME 3 "HIGH" 2 "MEDIUM" 1 "LOW" 0 "LOWEST" ;
VAL_ 889 DAS_TP_bdlQltyME 3 "HIGH" 2 "MEDIUM" 1 "LOW" 0 "LOWEST" ;
VAL_ 889 DAS_TP_bdrQltyME 3 "HIGH" 2 "MEDIUM" 1 "LOW" 0 "LOWEST" ;
VAL_ 1545 DAS_TR_Obj00_Class 4 "RADAR_CLASS_CONSTRUCTION_ELEMENT" 3 "RADAR_CLASS_MOVING_PEDESTRIAN" 2 "RADAR_CLASS_MOVING_TWO_WHEEL_VEHICLE" 1 "RADAR_CLASS_MOVING_FOUR_WHEEL_VEHICLE" 0 "RADAR_CLASS_UNKNOWN" ;
VAL_ 1545 DAS_TR_Obj00_MovingState 3 "RADAR_MOVESTATE_STANDING" 2 "RADAR_MOVESTATE_STOPPED" 1 "RADAR_MOVESTATE_MOVING" 0 "RADAR_MOVESTATE_INDETERMINATE" ;
VAL_ 1545 DAS_TR_Obj01_Class 4 "RADAR_CLASS_CONSTRUCTION_ELEMENT" 3 "RADAR_CLASS_MOVING_PEDESTRIAN" 2 "RADAR_CLASS_MOVING_TWO_WHEEL_VEHICLE" 1 "RADAR_CLASS_MOVING_FOUR_WHEEL_VEHICLE" 0 "RADAR_CLASS_UNKNOWN" ;
VAL_ 1545 DAS_TR_Obj01_MovingState 3 "RADAR_MOVESTATE_STANDING" 2 "RADAR_MOVESTATE_STOPPED" 1 "RADAR_MOVESTATE_MOVING" 0 "RADAR_MOVESTATE_INDETERMINATE" ;
VAL_ 1545 DAS_TR_Obj02_Class 4 "RADAR_CLASS_CONSTRUCTION_ELEMENT" 3 "RADAR_CLASS_MOVING_PEDESTRIAN" 2 "RADAR_CLASS_MOVING_TWO_WHEEL_VEHICLE" 1 "RADAR_CLASS_MOVING_FOUR_WHEEL_VEHICLE" 0 "RADAR_CLASS_UNKNOWN" ;
VAL_ 1545 DAS_TR_Obj02_MovingState 3 "RADAR_MOVESTATE_STANDING" 2 "RADAR_MOVESTATE_STOPPED" 1 "RADAR_MOVESTATE_MOVING" 0 "RADAR_MOVESTATE_INDETERMINATE" ;
VAL_ 1545 DAS_TR_Obj03_Class 4 "RADAR_CLASS_CONSTRUCTION_ELEMENT" 3 "RADAR_CLASS_MOVING_PEDESTRIAN" 2 "RADAR_CLASS_MOVING_TWO_WHEEL_VEHICLE" 1 "RADAR_CLASS_MOVING_FOUR_WHEEL_VEHICLE" 0 "RADAR_CLASS_UNKNOWN" ;
VAL_ 1545 DAS_TR_Obj03_MovingState 3 "RADAR_MOVESTATE_STANDING" 2 "RADAR_MOVESTATE_STOPPED" 1 "RADAR_MOVESTATE_MOVING" 0 "RADAR_MOVESTATE_INDETERMINATE" ;
VAL_ 1545 DAS_TR_Obj04_Class 4 "RADAR_CLASS_CONSTRUCTION_ELEMENT" 3 "RADAR_CLASS_MOVING_PEDESTRIAN" 2 "RADAR_CLASS_MOVING_TWO_WHEEL_VEHICLE" 1 "RADAR_CLASS_MOVING_FOUR_WHEEL_VEHICLE" 0 "RADAR_CLASS_UNKNOWN" ;
VAL_ 1545 DAS_TR_Obj04_MovingState 3 "RADAR_MOVESTATE_STANDING" 2 "RADAR_MOVESTATE_STOPPED" 1 "RADAR_MOVESTATE_MOVING" 0 "RADAR_MOVESTATE_INDETERMINATE" ;
VAL_ 1545 DAS_TR_Obj05_Class 4 "RADAR_CLASS_CONSTRUCTION_ELEMENT" 3 "RADAR_CLASS_MOVING_PEDESTRIAN" 2 "RADAR_CLASS_MOVING_TWO_WHEEL_VEHICLE" 1 "RADAR_CLASS_MOVING_FOUR_WHEEL_VEHICLE" 0 "RADAR_CLASS_UNKNOWN" ;
VAL_ 1545 DAS_TR_Obj05_MovingState 3 "RADAR_MOVESTATE_STANDING" 2 "RADAR_MOVESTATE_STOPPED" 1 "RADAR_MOVESTATE_MOVING" 0 "RADAR_MOVESTATE_INDETERMINATE" ;
VAL_ 1545 DAS_TR_Obj06_Class 4 "RADAR_CLASS_CONSTRUCTION_ELEMENT" 3 "RADAR_CLASS_MOVING_PEDESTRIAN" 2 "RADAR_CLASS_MOVING_TWO_WHEEL_VEHICLE" 1 "RADAR_CLASS_MOVING_FOUR_WHEEL_VEHICLE" 0 "RADAR_CLASS_UNKNOWN" ;
VAL_ 1545 DAS_TR_Obj06_MovingState 3 "RADAR_MOVESTATE_STANDING" 2 "RADAR_MOVESTATE_STOPPED" 1 "RADAR_MOVESTATE_MOVING" 0 "RADAR_MOVESTATE_INDETERMINATE" ;
VAL_ 1545 DAS_TR_Obj07_Class 4 "RADAR_CLASS_CONSTRUCTION_ELEMENT" 3 "RADAR_CLASS_MOVING_PEDESTRIAN" 2 "RADAR_CLASS_MOVING_TWO_WHEEL_VEHICLE" 1 "RADAR_CLASS_MOVING_FOUR_WHEEL_VEHICLE" 0 "RADAR_CLASS_UNKNOWN" ;
VAL_ 1545 DAS_TR_Obj07_MovingState 3 "RADAR_MOVESTATE_STANDING" 2 "RADAR_MOVESTATE_STOPPED" 1 "RADAR_MOVESTATE_MOVING" 0 "RADAR_MOVESTATE_INDETERMINATE" ;
VAL_ 1545 DAS_TR_Obj08_Class 4 "RADAR_CLASS_CONSTRUCTION_ELEMENT" 3 "RADAR_CLASS_MOVING_PEDESTRIAN" 2 "RADAR_CLASS_MOVING_TWO_WHEEL_VEHICLE" 1 "RADAR_CLASS_MOVING_FOUR_WHEEL_VEHICLE" 0 "RADAR_CLASS_UNKNOWN" ;
VAL_ 1545 DAS_TR_Obj08_MovingState 3 "RADAR_MOVESTATE_STANDING" 2 "RADAR_MOVESTATE_STOPPED" 1 "RADAR_MOVESTATE_MOVING" 0 "RADAR_MOVESTATE_INDETERMINATE" ;
VAL_ 1545 DAS_TR_Obj09_Class 4 "RADAR_CLASS_CONSTRUCTION_ELEMENT" 3 "RADAR_CLASS_MOVING_PEDESTRIAN" 2 "RADAR_CLASS_MOVING_TWO_WHEEL_VEHICLE" 1 "RADAR_CLASS_MOVING_FOUR_WHEEL_VEHICLE" 0 "RADAR_CLASS_UNKNOWN" ;
VAL_ 1545 DAS_TR_Obj09_MovingState 3 "RADAR_MOVESTATE_STANDING" 2 "RADAR_MOVESTATE_STOPPED" 1 "RADAR_MOVESTATE_MOVING" 0 "RADAR_MOVESTATE_INDETERMINATE" ;
VAL_ 1545 DAS_TR_Obj10_Class 4 "RADAR_CLASS_CONSTRUCTION_ELEMENT" 3 "RADAR_CLASS_MOVING_PEDESTRIAN" 2 "RADAR_CLASS_MOVING_TWO_WHEEL_VEHICLE" 1 "RADAR_CLASS_MOVING_FOUR_WHEEL_VEHICLE" 0 "RADAR_CLASS_UNKNOWN" ;
VAL_ 1545 DAS_TR_Obj10_MovingState 3 "RADAR_MOVESTATE_STANDING" 2 "RADAR_MOVESTATE_STOPPED" 1 "RADAR_MOVESTATE_MOVING" 0 "RADAR_MOVESTATE_INDETERMINATE" ;
VAL_ 1545 DAS_TR_Obj11_Class 4 "RADAR_CLASS_CONSTRUCTION_ELEMENT" 3 "RADAR_CLASS_MOVING_PEDESTRIAN" 2 "RADAR_CLASS_MOVING_TWO_WHEEL_VEHICLE" 1 "RADAR_CLASS_MOVING_FOUR_WHEEL_VEHICLE" 0 "RADAR_CLASS_UNKNOWN" ;
VAL_ 1545 DAS_TR_Obj11_MovingState 3 "RADAR_MOVESTATE_STANDING" 2 "RADAR_MOVESTATE_STOPPED" 1 "RADAR_MOVESTATE_MOVING" 0 "RADAR_MOVESTATE_INDETERMINATE" ;
VAL_ 1545 DAS_TR_Obj12_Class 4 "RADAR_CLASS_CONSTRUCTION_ELEMENT" 3 "RADAR_CLASS_MOVING_PEDESTRIAN" 2 "RADAR_CLASS_MOVING_TWO_WHEEL_VEHICLE" 1 "RADAR_CLASS_MOVING_FOUR_WHEEL_VEHICLE" 0 "RADAR_CLASS_UNKNOWN" ;
VAL_ 1545 DAS_TR_Obj12_MovingState 3 "RADAR_MOVESTATE_STANDING" 2 "RADAR_MOVESTATE_STOPPED" 1 "RADAR_MOVESTATE_MOVING" 0 "RADAR_MOVESTATE_INDETERMINATE" ;
VAL_ 1545 DAS_TR_Obj13_Class 4 "RADAR_CLASS_CONSTRUCTION_ELEMENT" 3 "RADAR_CLASS_MOVING_PEDESTRIAN" 2 "RADAR_CLASS_MOVING_TWO_WHEEL_VEHICLE" 1 "RADAR_CLASS_MOVING_FOUR_WHEEL_VEHICLE" 0 "RADAR_CLASS_UNKNOWN" ;
VAL_ 1545 DAS_TR_Obj13_MovingState 3 "RADAR_MOVESTATE_STANDING" 2 "RADAR_MOVESTATE_STOPPED" 1 "RADAR_MOVESTATE_MOVING" 0 "RADAR_MOVESTATE_INDETERMINATE" ;
VAL_ 1545 DAS_TR_Obj14_Class 4 "RADAR_CLASS_CONSTRUCTION_ELEMENT" 3 "RADAR_CLASS_MOVING_PEDESTRIAN" 2 "RADAR_CLASS_MOVING_TWO_WHEEL_VEHICLE" 1 "RADAR_CLASS_MOVING_FOUR_WHEEL_VEHICLE" 0 "RADAR_CLASS_UNKNOWN" ;
VAL_ 1545 DAS_TR_Obj14_MovingState 3 "RADAR_MOVESTATE_STANDING" 2 "RADAR_MOVESTATE_STOPPED" 1 "RADAR_MOVESTATE_MOVING" 0 "RADAR_MOVESTATE_INDETERMINATE" ;
VAL_ 1545 DAS_TR_Obj15_Class 4 "RADAR_CLASS_CONSTRUCTION_ELEMENT" 3 "RADAR_CLASS_MOVING_PEDESTRIAN" 2 "RADAR_CLASS_MOVING_TWO_WHEEL_VEHICLE" 1 "RADAR_CLASS_MOVING_FOUR_WHEEL_VEHICLE" 0 "RADAR_CLASS_UNKNOWN" ;
VAL_ 1545 DAS_TR_Obj15_MovingState 3 "RADAR_MOVESTATE_STANDING" 2 "RADAR_MOVESTATE_STOPPED" 1 "RADAR_MOVESTATE_MOVING" 0 "RADAR_MOVESTATE_INDETERMINATE" ;
VAL_ 1545 DAS_TR_Obj16_Class 4 "RADAR_CLASS_CONSTRUCTION_ELEMENT" 3 "RADAR_CLASS_MOVING_PEDESTRIAN" 2 "RADAR_CLASS_MOVING_TWO_WHEEL_VEHICLE" 1 "RADAR_CLASS_MOVING_FOUR_WHEEL_VEHICLE" 0 "RADAR_CLASS_UNKNOWN" ;
VAL_ 1545 DAS_TR_Obj16_MovingState 3 "RADAR_MOVESTATE_STANDING" 2 "RADAR_MOVESTATE_STOPPED" 1 "RADAR_MOVESTATE_MOVING" 0 "RADAR_MOVESTATE_INDETERMINATE" ;
VAL_ 1545 DAS_TR_Obj17_Class 4 "RADAR_CLASS_CONSTRUCTION_ELEMENT" 3 "RADAR_CLASS_MOVING_PEDESTRIAN" 2 "RADAR_CLASS_MOVING_TWO_WHEEL_VEHICLE" 1 "RADAR_CLASS_MOVING_FOUR_WHEEL_VEHICLE" 0 "RADAR_CLASS_UNKNOWN" ;
VAL_ 1545 DAS_TR_Obj17_MovingState 3 "RADAR_MOVESTATE_STANDING" 2 "RADAR_MOVESTATE_STOPPED" 1 "RADAR_MOVESTATE_MOVING" 0 "RADAR_MOVESTATE_INDETERMINATE" ;
VAL_ 1545 DAS_TR_Obj18_Class 4 "RADAR_CLASS_CONSTRUCTION_ELEMENT" 3 "RADAR_CLASS_MOVING_PEDESTRIAN" 2 "RADAR_CLASS_MOVING_TWO_WHEEL_VEHICLE" 1 "RADAR_CLASS_MOVING_FOUR_WHEEL_VEHICLE" 0 "RADAR_CLASS_UNKNOWN" ;
VAL_ 1545 DAS_TR_Obj18_MovingState 3 "RADAR_MOVESTATE_STANDING" 2 "RADAR_MOVESTATE_STOPPED" 1 "RADAR_MOVESTATE_MOVING" 0 "RADAR_MOVESTATE_INDETERMINATE" ;
VAL_ 1545 DAS_TR_Obj19_Class 4 "RADAR_CLASS_CONSTRUCTION_ELEMENT" 3 "RADAR_CLASS_MOVING_PEDESTRIAN" 2 "RADAR_CLASS_MOVING_TWO_WHEEL_VEHICLE" 1 "RADAR_CLASS_MOVING_FOUR_WHEEL_VEHICLE" 0 "RADAR_CLASS_UNKNOWN" ;
VAL_ 1545 DAS_TR_Obj19_MovingState 3 "RADAR_MOVESTATE_STANDING" 2 "RADAR_MOVESTATE_STOPPED" 1 "RADAR_MOVESTATE_MOVING" 0 "RADAR_MOVESTATE_INDETERMINATE" ;
VAL_ 1545 DAS_TR_Obj20_Class 4 "RADAR_CLASS_CONSTRUCTION_ELEMENT" 3 "RADAR_CLASS_MOVING_PEDESTRIAN" 2 "RADAR_CLASS_MOVING_TWO_WHEEL_VEHICLE" 1 "RADAR_CLASS_MOVING_FOUR_WHEEL_VEHICLE" 0 "RADAR_CLASS_UNKNOWN" ;
VAL_ 1545 DAS_TR_Obj20_MovingState 3 "RADAR_MOVESTATE_STANDING" 2 "RADAR_MOVESTATE_STOPPED" 1 "RADAR_MOVESTATE_MOVING" 0 "RADAR_MOVESTATE_INDETERMINATE" ;
VAL_ 1545 DAS_TR_Obj21_Class 4 "RADAR_CLASS_CONSTRUCTION_ELEMENT" 3 "RADAR_CLASS_MOVING_PEDESTRIAN" 2 "RADAR_CLASS_MOVING_TWO_WHEEL_VEHICLE" 1 "RADAR_CLASS_MOVING_FOUR_WHEEL_VEHICLE" 0 "RADAR_CLASS_UNKNOWN" ;
VAL_ 1545 DAS_TR_Obj21_MovingState 3 "RADAR_MOVESTATE_STANDING" 2 "RADAR_MOVESTATE_STOPPED" 1 "RADAR_MOVESTATE_MOVING" 0 "RADAR_MOVESTATE_INDETERMINATE" ;
VAL_ 1545 DAS_TR_Obj22_Class 4 "RADAR_CLASS_CONSTRUCTION_ELEMENT" 3 "RADAR_CLASS_MOVING_PEDESTRIAN" 2 "RADAR_CLASS_MOVING_TWO_WHEEL_VEHICLE" 1 "RADAR_CLASS_MOVING_FOUR_WHEEL_VEHICLE" 0 "RADAR_CLASS_UNKNOWN" ;
VAL_ 1545 DAS_TR_Obj22_MovingState 3 "RADAR_MOVESTATE_STANDING" 2 "RADAR_MOVESTATE_STOPPED" 1 "RADAR_MOVESTATE_MOVING" 0 "RADAR_MOVESTATE_INDETERMINATE" ;
VAL_ 1545 DAS_TR_Obj23_Class 4 "RADAR_CLASS_CONSTRUCTION_ELEMENT" 3 "RADAR_CLASS_MOVING_PEDESTRIAN" 2 "RADAR_CLASS_MOVING_TWO_WHEEL_VEHICLE" 1 "RADAR_CLASS_MOVING_FOUR_WHEEL_VEHICLE" 0 "RADAR_CLASS_UNKNOWN" ;
VAL_ 1545 DAS_TR_Obj23_MovingState 3 "RADAR_MOVESTATE_STANDING" 2 "RADAR_MOVESTATE_STOPPED" 1 "RADAR_MOVESTATE_MOVING" 0 "RADAR_MOVESTATE_INDETERMINATE" ;
VAL_ 1545 DAS_TR_Obj24_Class 4 "RADAR_CLASS_CONSTRUCTION_ELEMENT" 3 "RADAR_CLASS_MOVING_PEDESTRIAN" 2 "RADAR_CLASS_MOVING_TWO_WHEEL_VEHICLE" 1 "RADAR_CLASS_MOVING_FOUR_WHEEL_VEHICLE" 0 "RADAR_CLASS_UNKNOWN" ;
VAL_ 1545 DAS_TR_Obj24_MovingState 3 "RADAR_MOVESTATE_STANDING" 2 "RADAR_MOVESTATE_STOPPED" 1 "RADAR_MOVESTATE_MOVING" 0 "RADAR_MOVESTATE_INDETERMINATE" ;
VAL_ 1545 DAS_TR_Obj25_Class 4 "RADAR_CLASS_CONSTRUCTION_ELEMENT" 3 "RADAR_CLASS_MOVING_PEDESTRIAN" 2 "RADAR_CLASS_MOVING_TWO_WHEEL_VEHICLE" 1 "RADAR_CLASS_MOVING_FOUR_WHEEL_VEHICLE" 0 "RADAR_CLASS_UNKNOWN" ;
VAL_ 1545 DAS_TR_Obj25_MovingState 3 "RADAR_MOVESTATE_STANDING" 2 "RADAR_MOVESTATE_STOPPED" 1 "RADAR_MOVESTATE_MOVING" 0 "RADAR_MOVESTATE_INDETERMINATE" ;
VAL_ 1545 DAS_TR_Obj26_Class 4 "RADAR_CLASS_CONSTRUCTION_ELEMENT" 3 "RADAR_CLASS_MOVING_PEDESTRIAN" 2 "RADAR_CLASS_MOVING_TWO_WHEEL_VEHICLE" 1 "RADAR_CLASS_MOVING_FOUR_WHEEL_VEHICLE" 0 "RADAR_CLASS_UNKNOWN" ;
VAL_ 1545 DAS_TR_Obj26_MovingState 3 "RADAR_MOVESTATE_STANDING" 2 "RADAR_MOVESTATE_STOPPED" 1 "RADAR_MOVESTATE_MOVING" 0 "RADAR_MOVESTATE_INDETERMINATE" ;
VAL_ 1545 DAS_TR_Obj27_Class 4 "RADAR_CLASS_CONSTRUCTION_ELEMENT" 3 "RADAR_CLASS_MOVING_PEDESTRIAN" 2 "RADAR_CLASS_MOVING_TWO_WHEEL_VEHICLE" 1 "RADAR_CLASS_MOVING_FOUR_WHEEL_VEHICLE" 0 "RADAR_CLASS_UNKNOWN" ;
VAL_ 1545 DAS_TR_Obj27_MovingState 3 "RADAR_MOVESTATE_STANDING" 2 "RADAR_MOVESTATE_STOPPED" 1 "RADAR_MOVESTATE_MOVING" 0 "RADAR_MOVESTATE_INDETERMINATE" ;
VAL_ 1545 DAS_TR_Obj28_Class 4 "RADAR_CLASS_CONSTRUCTION_ELEMENT" 3 "RADAR_CLASS_MOVING_PEDESTRIAN" 2 "RADAR_CLASS_MOVING_TWO_WHEEL_VEHICLE" 1 "RADAR_CLASS_MOVING_FOUR_WHEEL_VEHICLE" 0 "RADAR_CLASS_UNKNOWN" ;
VAL_ 1545 DAS_TR_Obj28_MovingState 3 "RADAR_MOVESTATE_STANDING" 2 "RADAR_MOVESTATE_STOPPED" 1 "RADAR_MOVESTATE_MOVING" 0 "RADAR_MOVESTATE_INDETERMINATE" ;
VAL_ 1545 DAS_TR_Obj29_Class 4 "RADAR_CLASS_CONSTRUCTION_ELEMENT" 3 "RADAR_CLASS_MOVING_PEDESTRIAN" 2 "RADAR_CLASS_MOVING_TWO_WHEEL_VEHICLE" 1 "RADAR_CLASS_MOVING_FOUR_WHEEL_VEHICLE" 0 "RADAR_CLASS_UNKNOWN" ;
VAL_ 1545 DAS_TR_Obj29_MovingState 3 "RADAR_MOVESTATE_STANDING" 2 "RADAR_MOVESTATE_STOPPED" 1 "RADAR_MOVESTATE_MOVING" 0 "RADAR_MOVESTATE_INDETERMINATE" ;
VAL_ 1545 DAS_TR_Obj30_Class 4 "RADAR_CLASS_CONSTRUCTION_ELEMENT" 3 "RADAR_CLASS_MOVING_PEDESTRIAN" 2 "RADAR_CLASS_MOVING_TWO_WHEEL_VEHICLE" 1 "RADAR_CLASS_MOVING_FOUR_WHEEL_VEHICLE" 0 "RADAR_CLASS_UNKNOWN" ;
VAL_ 1545 DAS_TR_Obj30_MovingState 3 "RADAR_MOVESTATE_STANDING" 2 "RADAR_MOVESTATE_STOPPED" 1 "RADAR_MOVESTATE_MOVING" 0 "RADAR_MOVESTATE_INDETERMINATE" ;
VAL_ 1545 DAS_TR_Obj31_Class 4 "RADAR_CLASS_CONSTRUCTION_ELEMENT" 3 "RADAR_CLASS_MOVING_PEDESTRIAN" 2 "RADAR_CLASS_MOVING_TWO_WHEEL_VEHICLE" 1 "RADAR_CLASS_MOVING_FOUR_WHEEL_VEHICLE" 0 "RADAR_CLASS_UNKNOWN" ;
VAL_ 1545 DAS_TR_Obj31_MovingState 3 "RADAR_MOVESTATE_STANDING" 2 "RADAR_MOVESTATE_STOPPED" 1 "RADAR_MOVESTATE_MOVING" 0 "RADAR_MOVESTATE_INDETERMINATE" ;
VAL_ 585 DAS_autosteerLeftLaneUsage 3 "BLACKLISTED" 2 "FUSED" 1 "AVAILABLE" 0 "REJECTED_UNAVAILABLE" ;
VAL_ 585 DAS_autosteerRightLaneUsage 3 "BLACKLISTED" 2 "FUSED" 1 "AVAILABLE" 0 "REJECTED_UNAVAILABLE" ;
VAL_ 585 DAS_autosteerVehiclesUsage 3 "BLACKLISTED" 2 "FUSED" 1 "AVAILABLE" 0 "REJECTED_UNAVAILABLE" ;
VAL_ 585 DAS_autosteerHPPUsage 3 "BLACKLISTED" 2 "FUSED" 1 "AVAILABLE" 0 "REJECTED_UNAVAILABLE" ;
VAL_ 585 DAS_autosteerNavigationUsage 3 "BLACKLISTED" 2 "FUSED" 1 "AVAILABLE" 0 "REJECTED_UNAVAILABLE" ;
VAL_ 585 DAS_autosteerModelUsage 3 "BLACKLISTED" 2 "FUSED" 1 "AVAILABLE" 0 "REJECTED_UNAVAILABLE" ;
VAL_ 585 DAS_autosteerBottsDotsUsage 3 "BLACKLISTED" 2 "FUSED" 1 "AVAILABLE" 0 "REJECTED_UNAVAILABLE" ;
VAL_ 585 DAS_offsetSide 3 "OFFSET_BOTH_OBJECTS" 2 "OFFSET_LEFT_OBJECT" 1 "OFFSET_RIGHT_OBJECT" 0 "NO_OFFSET" ;
VAL_ 585 DAS_roadSurfaceType 2 "ROAD_SURFACE_ENHANCED" 1 "ROAD_SURFACE_NORMAL" 0 "ROAD_SURFACE_SNA" ;
VAL_ 585 DAS_autosteerHealthState 5 "HEALTH_FAULT" 4 "HEALTH_ABORTING" 3 "HEALTH_SEVERELY_DEGRADED" 2 "HEALTH_DEGRADED" 1 "HEALTH_NOMINAL" 0 "HEALTH_UNAVAILABLE" ;
VAL_ 585 DAS_lastLinePreferenceReason 15 "NONE" 5 "COUNTRY_DRIVING_SIDE" 4 "AVOID_ONCOMING_LANES" 3 "NAVIGATION_BRANCH" 2 "NEIGHBOR_LANE_PROBABILIY" 1 "AGREEMENT_WITH_NEIGHBOR_LANES" 0 "OTHER_LANE_DISAGREES_WITH_MODEL" ;
VAL_ 585 DAS_plannerState 7 "TP_EXTSTATE_LANECHANGE_ABORT" 6 "TP_EXTSTATE_LANECHANGE_WAIT_FOR_FWD_OBSTACLE" 5 "TP_EXTSTATE_LANECHANGE_WAIT_FOR_SIDE_OBSTACLE" 4 "TP_EXTSTATE_LANECHANGE_IN_PROGRESS" 3 "TP_EXTSTATE_LANECHANGE_REQUESTED" 2 "TP_EXTSTATE_FOLLOW" 1 "TP_EXTSTATE_VL" 0 "TP_EXTSTATE_DISABLED" ;
VAL_ 585 DAS_lastAutosteerAbortReason 31 "UI_ABORT_REASON_NO_ABORT" 30 "UI_ABORT_REASON_CAMERA_FAILSAFES" 29 "UI_ABORT_REASON_ACC_CANCEL" 28 "UI_ABORT_REASON_EPAS_ERROR_CODE" 27 "UI_ABORT_REASON_PLANNER_OUTPUT_INVALID" 26 "UI_ABORT_REASON_FOLLOWER_OUTPUT_INVALID" 25 "UI_ABORT_REASON_VEHICLE_SPEED_ABOVE_MAX" 24 "UI_ABORT_REASON_DRIVING_OFF_NAV" 23 "UI_ABORT_REASON_CID_SWITCH_DISABLED" 22 "UI_ABORT_REASON_CRUISE_FAULT" 21 "UI_ABORT_REASON_COMPONENT_MIA" 20 "UI_ABORT_REASON_EPAS_EAC_DENIED" 19 "UI_ABORT_REASON_SIDE_COLLISION_IMMINENT" 18 "UI_ABORT_REASON_TRAILER_MODE" 17 "UI_ABORT_REASON_CAM_WATCHDOG" 16 "UI_ABORT_REASON_CAM_MSG_MIA" 15 "UI_ABORT_REASON_ME_MAIN_STATE_NOT_VISION" 14 "UI_ABORT_REASON_APP_ME_STATE_NOT_VISION" 2 "UI_ABORT_REASON_HM_STEERING_ERROR" 1 "UI_ABORT_REASON_HM_VIRTUAL_LANE_NO_INPUTS" 0 "UI_ABORT_REASON_HM_LANE_VIEW_RANGE" ;
VAL_ 585 DAS_accSmartSpeedState 7 "SNA" 4 "SET_SPEED_SET_REQUESTED" 3 "ACTIVE" 2 "ACTIVE_INTEGRATING" 1 "ACTIVE_OFFRAMP" 0 "NOT_ACTIVE" ;
VAL_ 328 DI_ptcActive 1 "ACTIVE" 0 "INACTIVE" ;
VAL_ 328 DI_regenTcActive 1 "ACTIVE" 0 "INACTIVE" ;
VAL_ 872 DI_cruiseState 7 "CRS_STATE_PRE_CANCEL" 6 "CRS_STATE_PRE_FAULT" 5 "CRS_STATE_FAULT" 4 "CRS_STATE_OVERRIDE" 3 "CRS_STATE_STANDSTILL" 2 "CRS_STATE_ENABLED" 1 "CRS_STATE_STANDBY" 0 "CRS_STATE_OFF" ;
VAL_ 872 DI_speedUnits 1 "DI_SPEED_KPH" 0 "DI_SPEED_MPH" ;
VAL_ 872 DI_aebState 7 "AEB_CAN_STATE_SNA" 4 "AEB_CAN_STATE_FAULT" 3 "AEB_CAN_STATE_STANDSTILL" 2 "AEB_CAN_STATE_ENABLED" 1 "AEB_CAN_STATE_STANDBY" 0 "AEB_CAN_STATE_UNAVAILABLE" ;
VAL_ 872 DI_digitalSpeed 255 "SNA" ;
VAL_ 1016 DI_autoparkState 15 "DI_APC_SNA" 9 "DI_APC_SELFPARK_STARTED" 8 "DI_APC_UNPARK_COMPLETE" 7 "DI_APC_RESUMED" 6 "DI_APC_ABORTED" 5 "DI_APC_PAUSED" 4 "DI_APC_COMPLETE" 3 "DI_APC_ACTIVE" 2 "DI_APC_STARTED" 1 "DI_APC_STANDBY" 0 "DI_APC_UNAVAILABLE" ;
VAL_ 1016 DI_parkBrakeState 15 "DI_PBRK_SNA" 7 "DI_PBRK_RELEASING" 6 "DI_PBRK_PANIC_SKID" 5 "DI_PBRK_PANIC_EPB" 4 "DI_PBRK_FAULTED" 3 "DI_PBRK_APPLIED" 2 "DI_PBRK_REQUESTED" 1 "DI_PBRK_RELEASED" 0 "DI_PBRK_UNAVAILABLE" ;
VAL_ 1016 DI_pmmStatus 3 "DI_PMM_SNA" 1 "DI_PMM_ACTIVE" 0 "DI_PMM_INACTIVE" ;
VAL_ 264 DI_torqueDriver -4096 "SNA" ;
VAL_ 264 DI_pedalPos 255 "SNA" ;
VAL_ 280 DI_gear 7 "DI_GEAR_SNA" 4 "DI_GEAR_D" 3 "DI_GEAR_N" 2 "DI_GEAR_R" 1 "DI_GEAR_P" 0 "DI_GEAR_INVALID" ;
VAL_ 280 DI_brakePedal 1 "Applied" 0 "Not_applied" ;
VAL_ 280 DI_vehicleSpeed 4095 "SNA" ;
VAL_ 280 DI_brakePedalState 3 "SNA" 2 "INVALID" 1 "ON" 0 "OFF" ;
VAL_ 880 EPAS_steeringFault 1 "FAULT" 0 "NO_FAULT" ;
VAL_ 880 EPAS_steeringReduced 1 "REDUCED_ASSIST" 0 "NORMAL_ASSIST" ;
VAL_ 880 EPAS_currentTuneMode 7 "UNAVAILABLE" 6 "RWD_SPORT" 5 "RWD_STANDARD" 4 "RWD_COMFORT" 3 "DM_SPORT" 2 "DM_STANDARD" 1 "DM_COMFORT" 0 "FAIL_SAFE_DEFAULT" ;
VAL_ 880 EPAS_torsionBarTorque 4095 "SNA" 4094 "UNDEFINABLE_DATA" 0 "SEE_SPECIFICATION" ;
VAL_ 880 EPAS_eacErrorCode 15 "SNA" 14 "EAC_ERROR_EPB_INHIBIT" 13 "EAC_ERROR_PINION_VEL_DIFF" 12 "EAC_ERROR_LOW_ASSIST" 11 "EAC_ERROR_HIGH_TORSION_SAFETY" 10 "EAC_ERROR_HIGH_MMOT_SAFETY" 9 "EAC_ERROR_HIGH_ANGLE_RATE_SAFETY" 8 "EAC_ERROR_HIGH_ANGLE_SAFETY" 7 "EAC_ERROR_HIGH_ANGLE_RATE_REQ" 6 "EAC_ERROR_HIGH_ANGLE_REQ" 5 "EAR_ERROR_MAX_STEER_DELTA" 4 "EAC_ERROR_TMP_FAULT" 3 "EAC_ERROR_HANDS_ON" 2 "EAC_ERROR_MAX_SPEED" 1 "EAC_ERROR_MIN_SPEED" 0 "EAC_ERROR_IDLE" ;
VAL_ 880 EPAS_handsOnLevel 3 "LEVEL_3" 2 "LEVEL_2" 1 "LEVEL_1" 0 "LEVEL_0" ;
VAL_ 880 EPAS_eacStatus 4 "SNA" 3 "EAC_FAULT" 2 "EAC_ACTIVE" 1 "EAC_AVAILABLE" 0 "EAC_INHIBITED" ;
VAL_ 516 EPB_state 7 "EPB_STATE_SNA" 6 "EPB_STATE_SELFPARK" 5 "EPB_STATE_SERVICE" 4 "EPB_STATE_START" 3 "EPB_STATE_HANDBRAKE" 2 "EPB_STATE_PARK" 1 "EPB_STATE_DYNAMIC" 0 "EPB_STATE_OPEN" ;
VAL_ 293 Long_Acceleration 127 "SNA" ;
VAL_ 293 Lat_Acceleration 127 "SNA" ;
VAL_ 309 ESP_stabilityControlSts 5 "INIT" 4 "NOT_CONFIGURED" 3 "FAULTED" 2 "ENGAGED" 1 "ON" 0 "OFF" ;
VAL_ 325 ESP_longitudinalAccel 1023 "SNA" ;
VAL_ 325 ESP_lateralAccel 1023 "SNA" ;
VAL_ 341 ESP_wheelPulseCountReL 255 "SNA" ;
VAL_ 341 ESP_wheelPulseCountReR 255 "SNA" ;
VAL_ 522 ESP_driverBrakeApply 3 "Faulty_SNA" 2 "Driver_applying_brakes" 1 "Not_Applied" 0 "NotInit_orOff" ;
VAL_ 522 ESP_yawRate 4095 "SNA" ;
VAL_ 920 GTW_parkAssistInstalled 3 "VALEO_5" 2 "BOSCH_5" 1 "BOSCH_4_5" 0 "NONE" ;
VAL_ 920 GTW_airSuspensionInstalled 4 "TESLA_PLUS" 3 "TESLA_STANDARD" 2 "PLUS" 1 "STANDARD" 0 "NONE" ;
VAL_ 920 GTW_epasType 3 "MANDO_VGR66" 2 "MANDO_FGR64" 1 "BOSCH_L405" 0 "BOSCH_L538" ;
VAL_ 920 GTW_chassisType 2 "MODEL_3_CHASSIS" 1 "MODEL_X_CHASSIS" 0 "MODEL_S_CHASSIS" ;
VAL_ 920 GTW_autopilot 3 "SELF_DRIVING" 2 "ENHANCED" 1 "HIGHWAY" 0 "NONE" ;
VAL_ 776 AMB_TEMP 255 "SNA" 254 "Init" ;
VAL_ 776 GTW_ODO 16777215 "SNA" 16777214 "Init" ;
VAL_ 536 MCU_trailerModeCH 1 "TRAILER_MODE_ON" 0 "TRAILER_MODE_OFF" ;
VAL_ 536 MCU_fcwSensitivity 3 "SNA" 2 "AEB_SENSITIVITY_LATE" 1 "AEB_SENSITIVITY_AVERAGE" 0 "AEB_SENSITIVITY_EARLY" ;
VAL_ 536 MCU_fcwEnable 3 "SNA" 1 "FCW_ON" 0 "FCW_OFF" ;
VAL_ 536 MCU_latControlEnable 3 "LATERAL_CONTROL_SNA" 2 "LATERAL_CONTROL_UNAVAILABLE" 1 "LATERAL_CONTROL_ON" 0 "LATERAL_CONTROL_OFF" ;
VAL_ 536 MCU_accOvertakeEnable 3 "SNA" 1 "ACC_OVERTAKE_ON" 0 "ACC_OVERTAKE_OFF" ;
VAL_ 536 MCU_ldwEnable 3 "SNA" 1 "LDW_TRIGGERS_HAPTIC" 0 "NO_HAPTIC" ;
VAL_ 536 MCU_aebEnable 3 "SNA" 1 "AEB_ON" 0 "AEB_OFF" ;
VAL_ 536 MCU_bsdEnable 3 "SNA" 1 "BSD_ON" 0 "BSD_OFF" ;
VAL_ 536 MCU_ahlbEnable 3 "SNA" 1 "AHLB_ON" 0 "AHLB_OFF" ;
VAL_ 536 MCU_frontDefrostReq_das 3 "SNA" 1 "ON" 0 "OFF" ;
VAL_ 536 MCU_autoParkRequest 15 "SNA" 11 "RESUME" 10 "PAUSE" 9 "SEARCH" 8 "COMPLETE" 7 "ABORT" 6 "PARALLEL_PULL_OUT_TO_RIGHT" 5 "PARALLEL_PULL_OUT_TO_LEFT" 4 "PARK_RIGHT_CROSS" 3 "PARK_RIGHT_PARALLEL" 2 "PARK_LEFT_CROSS" 1 "PARK_LEFT_PARALLEL" 0 "NONE" ;
VAL_ 536 MCU_redLightStopSignEnable 3 "SNA" 1 "RLSSW_ON" 0 "RLSSW_OFF" ;
VAL_ 536 MCU_overPaintedUSS 3 "SNA" 2 "UNUSED" 1 "OVER_PAINTED" 0 "NOMINAL" ;
VAL_ 536 MCU_selfParkTune 15 "SNA" ;
VAL_ 536 MCU_aesEnable 3 "SNA" 1 "AES_ON" 0 "AES_OFF" ;
VAL_ 536 MCU_autoLaneChangeEnable 3 "SNA" 1 "ON" 0 "OFF" ;
VAL_ 1080 MCU_anonDebugFlag1 1 "ON" 0 "OFF" ;
VAL_ 1080 MCU_anonDebugFlag2 1 "ON" 0 "OFF" ;
VAL_ 1080 MCU_anonDebugFlag3 1 "ON" 0 "OFF" ;
VAL_ 1080 MCU_anonDebugFlag4 1 "ON" 0 "OFF" ;
VAL_ 1000 MCU_autopilotControlRequest 1 "NEXT_GEN_CTRL" 0 "LEGACY_LAT_CTRL" ;
VAL_ 1000 MCU_accControlConfig 3 "ACC_DEV3" 2 "ACC_DEV2" 1 "ACC_DEV1" 0 "ACC_DEFAULT" ;
VAL_ 1000 MCU_curvSpeedAdaptDisable 1 "CSA_OFF" 0 "CSA_ON" ;
VAL_ 1000 MCU_healthMonitorEnable 1 "HM_ON" 0 "HM_OFF" ;
VAL_ 1000 MCU_scaControlConfig 3 "SCA_DEV3" 2 "SCA_DEV2" 1 "SCA_DEV1" 0 "SCA_DEFAULT" ;
VAL_ 1000 MCU_anonDebugConfig 3 "CONFIG_4" 2 "CONFIG_3" 1 "CONFIG_2" 0 "CONFIG_1" ;
VAL_ 1000 MCU_bottsDotsEnable 1 "BD_ON" 0 "BD_OFF" ;
VAL_ 1000 MCU_roadCheckDisable 1 "RC_OFF" 0 "RC_ON" ;
VAL_ 1000 MCU_experimentalModeEnable 1 "EXPERIMENTAL_MODE" 0 "DEFAULT_MODE" ;
VAL_ 1000 MCU_handsOnRequirementDisable 1 "HANDS_ON_REQ_OFF" 0 "HANDS_ON_REQ_ON" ;
VAL_ 1000 MCU_disableRoadEstimator 1 "RE_OFF" 0 "RE_ON" ;
VAL_ 1000 MCU_fuseLanesDisable 1 "FUSE_LANES_OFF" 0 "FUSE_LANES_ON" ;
VAL_ 1000 MCU_fuseHPPDisable 1 "FUSE_HPP_OFF" 0 "FUSE_HPP_ON" ;
VAL_ 1000 MCU_fuseVehiclesDisable 1 "FUSE_VEH_OFF" 0 "FUSE_VEH_ON" ;
VAL_ 1000 MCU_fuseNavigationDisable 1 "FUSE_NAV_OFF" 0 "FUSE_NAV_ON" ;
VAL_ 1000 MCU_steeringRateLimits 3 "0_5_SEC" 2 "1_0_SEC" 1 "1_6_SEC" 0 "DEFAULT" ;
VAL_ 1000 MCU_curvatureDatabaseOnly 1 "ON" 0 "OFF" ;
VAL_ 1000 MCU_summonExitType 3 "SNA" 2 "TURN_LEFT" 1 "TURN_RIGHT" 0 "STRAIGHT" ;
VAL_ 1000 MCU_summonEntryType 3 "SNA" 2 "TURN_LEFT" 1 "TURN_RIGHT" 0 "STRAIGHT" ;
VAL_ 1000 MCU_selfParkRequest 15 "SNA" 10 "AUTO_SUMMON_PRIMED" 9 "AUTO_SUMMON_CANCEL" 8 "AUTO_SUMMON_REVERSE" 7 "AUTO_SUMMON_FORWARD" 6 "RESUME" 5 "PAUSE" 4 "PRIME" 3 "ABORT" 2 "SELF_PARK_REVERSE" 1 "SELF_PARK_FORWARD" 0 "NONE" ;
VAL_ 1000 MCU_summonReverseDist 63 "SNA" ;
VAL_ 1000 MCU_drivingSide 2 "DRIVING_SIDE_UNKNOWN" 1 "DRIVING_SIDE_RIGHT" 0 "DRIVING_SIDE_LEFT" ;
VAL_ 968 MCU_speedLimitDependency 7 "SNA" 6 "LANE" 5 "SEASON" 4 "TIME" 3 "SNOW" 2 "RAIN" 1 "SCHOOL" 0 "NONE" ;
VAL_ 968 MCU_roadClass 6 "CLASS_6_MINOR" 5 "CLASS_5" 4 "CLASS_4" 3 "CLASS_3" 2 "CLASS_2" 1 "CLASS_1_MAJOR" 0 "UNKNOWN_INVALID_SNA" ;
VAL_ 968 MCU_speedUnits 1 "KPH" 0 "MPH" ;
VAL_ 968 MCU_speedLimit 31 "SNA" 30 "UNLIMITED" 29 "LESS_OR_EQ_160" 28 "LESS_OR_EQ_150" 27 "LESS_OR_EQ_140" 26 "LESS_OR_EQ_130" 25 "LESS_OR_EQ_120" 24 "LESS_OR_EQ_115" 23 "LESS_OR_EQ_110" 22 "LESS_OR_EQ_105" 21 "LESS_OR_EQ_100" 20 "LESS_OR_EQ_95" 19 "LESS_OR_EQ_90" 18 "LESS_OR_EQ_85" 17 "LESS_OR_EQ_80" 16 "LESS_OR_EQ_75" 15 "LESS_OR_EQ_70" 14 "LESS_OR_EQ_65" 13 "LESS_OR_EQ_60" 12 "LESS_OR_EQ_55" 11 "LESS_OR_EQ_50" 10 "LESS_OR_EQ_45" 9 "LESS_OR_EQ_40" 8 "LESS_OR_EQ_35" 7 "LESS_OR_EQ_30" 6 "LESS_OR_EQ_25" 5 "LESS_OR_EQ_20" 4 "LESS_OR_EQ_15" 3 "LESS_OR_EQ_10" 2 "LESS_OR_EQ_7" 1 "LESS_OR_EQ_5" 0 "UNKNOWN" ;
VAL_ 968 MCU_speedLimitType 7 "UNKNOWN_SNA" 4 "BUMPS" 3 "DEPENDENT" 2 "ADVISORY" 1 "REGULAR" ;
VAL_ 968 MCU_countryCode 1023 "SNA" 0 "UNKNOWN" ;
VAL_ 968 MCU_nextBranchDist 31 "SNA" ;
VAL_ 568 MCU_roadSign 5 "ROAD_SIGN_SPLINE_ID_FULL" 4 "ROAD_SIGN_SPEED_SPLINE" 3 "ROAD_SIGN_SPEED_LIMIT" 2 "ROAD_SIGN_TRAFFIC_LIGHT" 1 "ROAD_SIGN_STOP_SIGN" 0 "ROAD_SIGN_NONE" ;
VAL_ 568 MCU_splineLocConfidence 0 "SNA" ;
VAL_ 568 MCU_baseMapSpeedLimitMPS 255 "SNA" ;
VAL_ 568 MCU_bottomQrtlFleetSpeedMPS 255 "SNA" ;
VAL_ 568 MCU_topQrtlFleetSpeedMPS 255 "SNA" ;
VAL_ 568 MCU_meanFleetSplineSpeedMPS 255 "SNA" ;
VAL_ 568 MCU_medianFleetSpeedMPS 255 "SNA" ;
VAL_ 568 MCU_rampType 2 "ENTRANCE" 1 "EXIT" 0 "NONE_SNA" ;
VAL_ 760 MCU_speedLimitUnits 1 "KPH" 0 "MPH" ;
VAL_ 760 MCU_userSpeedOffsetUnits 1 "KPH" 0 "MPH" ;
VAL_ 984 MCU_gpsAccuracy 127 "SNA" ;
VAL_ 696 MCU_radarTargetDx 255 "NO_OBJECT" ;
VAL_ 696 MCU_radarTargetDxEnd 255 "NO_OBJECT" ;
VAL_ 712 MCU_roadCurvHealth 3 "DATABASE" 2 "AVAILABLE" 1 "DEGRADED" 0 "UNAVAILABLE" ;
VAL_ 622 PARK_obj_type 4 "OLO_STRAIGHT_2_CORNER" 3 "OLO_STRAIGHT_1_CORNER" 2 "OLO_STRAIGHT_O_CORNER" 1 "OLO_POINT" 0 "OLO_NO_OBJECT" ;
VAL_ 574 PARK_oocDistance 511 "SNA" 501 "NOT_INITIALIZED" 500 "NO_OBJ_COLLISION" ;
VAL_ 574 PARK_oocConfidence 127 "SNA" 0 "NO_CONFIDENCE" ;
VAL_ 574 PARK_oocCollisionSide 7 "COLLISION_SNA" 5 "COLLISION_UNKNOWN" 4 "REAR_COLLISION" 3 "FRONT_COLLISION" 2 "LEFT_SIDE_COLLISION" 1 "RIGHT_SIDE_COLLISION" 0 "NO_COLLISION" ;
VAL_ 574 PARK_oocUntrackedTime 63 "SNA" ;
VAL_ 574 PARK_oocHeight 3 "HEIGHT_UNKNOWN" 2 "HIGH_OBJ" 1 "LOW_OBJ" 0 "NO_OBJ" ;
VAL_ 574 PARK_oocOffCourse 1023 "NONE" ;
VAL_ 846 PARK_frontLeftMiddleRawDistData 255 "SNA" ;
VAL_ 846 PARK_frontMiddleRawDistData 255 "SNA" ;
VAL_ 846 PARK_frontRightMiddleRawDistData 255 "SNA" ;
VAL_ 862 PARK_rearLeftMiddleRawDistData 255 "SNA" ;
VAL_ 862 PARK_rearMiddleRawDistData 255 "SNA" ;
VAL_ 862 PARK_rearRightMiddleRawDistData 255 "SNA" ;
VAL_ 542 PARK_pscParkStatus 7 "SNA" 6 "FAULT" 5 "GUIDANCE_FINISHED" 4 "PRE_GUIDANCE" 3 "GUIDANCE_RIGHT" 2 "GUIDANCE_LEFT" 1 "SEARCHING" 0 "NOT_AVAILABLE" ;
VAL_ 542 PARK_pscParkAbortReason 31 "SNA" 18 "ERROR" 17 "SYSTEM_SERVICE" 16 "SYSTEM_FAULT" 15 "ECU_INTERNAL_FAULT" 14 "DAS_ABORT" 13 "EPAS_FAULT" 12 "VEHICLE_DYNAMICS_INTERVENTION" 11 "HANDS_ON_DETECTED" 10 "FULL_WARNING_ON_BOTH_SIDES" 9 "PARK_SPACE_TOO_SMALL" 8 "OBSTACLE_ON_PATH" 7 "MAX_YAW_ANGLE_REACHED" 6 "MAX_SWA_DEV_EXCEEDED" 5 "OFF_TRACK" 4 "UNCONTROLLED_TRAVEL_DIST_REACHED" 3 "NO_VALID_PATH" 2 "MAX_NUM_OF_MOVES" 1 "VELOCITY_TOO_HIGH" 0 "NONE" ;
VAL_ 542 PARK_pscParallelSpace 3 "BOTH_AVAILABLE" 2 "LEFT_AVAILABLE" 1 "RIGHT_AVAILABLE" 0 "NONE_AVAILABLE" ;
VAL_ 542 PARK_pscCrossSpace 3 "BOTH_AVAILABLE" 2 "LEFT_AVAILABLE" 1 "RIGHT_AVAILABLE" 0 "NONE_AVAILABLE" ;
VAL_ 542 PARK_pscParallelRightParkable 3 "SNA" 2 "PARKING_SLOT_OK_POSITION_OK" 1 "PARKING_SLOT_OK" 0 "NONE" ;
VAL_ 542 PARK_pscParallelLeftParkable 3 "SNA" 2 "PARKING_SLOT_OK_POSITION_OK" 1 "PARKING_SLOT_OK" 0 "NONE" ;
VAL_ 542 PARK_pscCrossRightParkable 3 "SNA" 2 "PARKING_SLOT_OK_POSITION_OK" 1 "PARKING_SLOT_OK" 0 "NONE" ;
VAL_ 542 PARK_pscMaxVelocity 63 "SNA" ;
VAL_ 542 PARK_pscCrossLeftParkable 3 "SNA" 2 "PARKING_SLOT_OK_POSITION_OK" 1 "PARKING_SLOT_OK" 0 "NONE" ;
VAL_ 542 PARK_pscParkInstruction 7 "SNA" 5 "EXPLORATION" 4 "ABORTED" 3 "DRIVE_BACKWARD" 2 "DRIVE_FORWARD" 1 "STOP" 0 "NO_MESSAGE" ;
VAL_ 542 PARK_pscManeuverDistance 2047 "SNA" ;
VAL_ 542 PARK_pscAngleActive 1 "REQUEST_CONTROL" 0 "INACTIVE" ;
VAL_ 590 PARK_pscVehSlotType 3 "RIGHT_CROSS" 2 "RIGHT_PARALLEL" 1 "LEFT_CROSS" 0 "LEFT_PARALLEL" ;
VAL_ 590 PARK_pscLeftParallelPsi 8191 "SNA" 8190 "NO_SPACE" ;
VAL_ 590 PARK_pscLeftParallelSizeX 255 "SNA" 254 "NO_SPACE" ;
VAL_ 590 PARK_pscLeftParallelSizeY 255 "SNA" 254 "NO_SPACE" ;
VAL_ 590 PARK_pscLeftCrossPsi 8191 "SNA" 8190 "NO_SPACE" ;
VAL_ 590 PARK_pscLeftCrossSizeX 255 "SNA" 254 "NO_SPACE" ;
VAL_ 590 PARK_pscLeftCrossSizeY 255 "SNA" 254 "NO_SPACE" ;
VAL_ 590 PARK_pscRightParallelPsi 8191 "SNA" 8190 "NO_SPACE" ;
VAL_ 590 PARK_pscRightParallelSizeX 255 "SNA" 254 "NO_SPACE" ;
VAL_ 590 PARK_pscRightParallelSizeY 255 "SNA" 254 "NO_SPACE" ;
VAL_ 590 PARK_pscRightCrossPsi 8191 "SNA" 8190 "NO_SPACE" ;
VAL_ 590 PARK_pscRightCrossSizeX 255 "SNA" 254 "NO_SPACE" ;
VAL_ 590 PARK_pscRightCrossSizeY 255 "SNA" 254 "NO_SPACE" ;
VAL_ 526 PARK_sdiSensor1RawDistData 511 "SNA" 500 "NO_OBJECT_DETECTED" 1 "NEAR_DETECTION" 0 "BLOCKED" ;
VAL_ 526 PARK_sdiSensor6RawDistData 511 "SNA" 500 "NO_OBJECT_DETECTED" 1 "NEAR_DETECTION" 0 "BLOCKED" ;
VAL_ 558 PARK_sdiSensor7RawDistData 511 "SNA" 500 "NO_OBJECT_DETECTED" 1 "NEAR_DETECTION" 0 "BLOCKED" ;
VAL_ 558 PARK_sdiSensor8RawDistData 511 "SNA" 500 "NO_OBJECT_DETECTED" 1 "NEAR_DETECTION" 0 "BLOCKED" ;
VAL_ 558 PARK_sdiSensor11RawDistData 511 "SNA" 500 "NO_OBJECT_DETECTED" 1 "NEAR_DETECTION" 0 "BLOCKED" ;
VAL_ 558 PARK_sdiSensor12RawDistData 511 "SNA" 500 "NO_OBJECT_DETECTED" 1 "NEAR_DETECTION" 0 "BLOCKED" ;
VAL_ 814 PARK_frontRightSensorState 3 "SNA" 2 "TEMPORARY_FAILURE" 1 "PERMANENT_FAILURE" 0 "NO_FAILURE" ;
VAL_ 814 PARK_frontRightMiddleSensorState 3 "SNA" 2 "TEMPORARY_FAILURE" 1 "PERMANENT_FAILURE" 0 "NO_FAILURE" ;
VAL_ 814 PARK_frontLeftMiddleSensorState 3 "SNA" 2 "TEMPORARY_FAILURE" 1 "PERMANENT_FAILURE" 0 "NO_FAILURE" ;
VAL_ 814 PARK_frontLeftSensorState 3 "SNA" 2 "TEMPORARY_FAILURE" 1 "PERMANENT_FAILURE" 0 "NO_FAILURE" ;
VAL_ 814 PARK_frontLeftRawDistData 255 "SNA" ;
VAL_ 814 PARK_frontRightRawDistData 255 "SNA" ;
VAL_ 814 PARK_systemStatusFront 3 "SNA" 2 "UNUSED" 1 "ENABLED" 0 "DISABLED" ;
VAL_ 814 PARK_frontDtcPresent 3 "SNA" 2 "UNUSED" 1 "TRUE" 0 "FALSE" ;
VAL_ 830 PARK_rearRightSensorState 3 "SNA" 2 "TEMPORARY_FAILURE" 1 "PERMANENT_FAILURE" 0 "NO_FAILURE" ;
VAL_ 830 PARK_rearRightMiddleSensorState 3 "SNA" 2 "TEMPORARY_FAILURE" 1 "PERMANENT_FAILURE" 0 "NO_FAILURE" ;
VAL_ 830 PARK_rearLeftMiddleSensorState 3 "SNA" 2 "TEMPORARY_FAILURE" 1 "PERMANENT_FAILURE" 0 "NO_FAILURE" ;
VAL_ 830 PARK_rearLeftSensorState 3 "SNA" 2 "TEMPORARY_FAILURE" 1 "PERMANENT_FAILURE" 0 "NO_FAILURE" ;
VAL_ 830 PARK_rearLeftRawDistData 255 "SNA" ;
VAL_ 830 PARK_rearRightRawDistData 255 "SNA" ;
VAL_ 830 PARK_systemStatusRear 3 "SNA" 2 "UNUSED" 1 "ENABLED" 0 "DISABLED" ;
VAL_ 830 PARK_rearDtcPresent 3 "SNA" 2 "UNUSED" 1 "TRUE" 0 "FALSE" ;
VAL_ 798 PARK_status 3 "SNA" 2 "TEMPORARY_FAILURE" 1 "ENABLED" 0 "DISABLED" ;
VAL_ 798 PARK_serviceRequest 3 "SNA" 2 "UNUSED" 1 "FAILURE" 0 "NO_FAILURE" ;
VAL_ 798 PARK_systemDtcPresent 3 "SNA" 2 "UNUSED" 1 "TRUE" 0 "FALSE" ;
VAL_ 798 PARK_majorVersion 255 "SNA" ;
VAL_ 798 PARK_minorVersion 255 "SNA" ;
VAL_ 798 PARK_subMinorVersion 255 "SNA" ;
VAL_ 782 PARK_pscRightCurbType 2 "HIGH_CURB" 1 "LOW_CURB" 0 "VIRTUAL_CURB" ;
VAL_ 782 PARK_pscLeftCurbType 2 "HIGH_CURB" 1 "LOW_CURB" 0 "VIRTUAL_CURB" ;
VAL_ 782 PARK_autoCalComplete 1 "COMPLETE" 0 "INCOMPLETE" ;
VAL_ 782 PARK_tireFitment 3 "SNA" 1 "STAGGERED" 0 "SQUARE" ;
VAL_ 782 PARK_rackDetected 3 "SNA" 2 "RACK_DETECTED" 1 "NO_RACK" 0 "UNKNOWN" ;
VAL_ 782 PARK_sdiActive 1 "SDI_ENABLED" 0 "SDI_DISABLED" ;
VAL_ 782 PARK_sdiNoise 3 "SDI_NOISE_SNA" 2 "SDI_NOISE_RAIN" 1 "SDI_NOISE_HIGH" 0 "SDI_NOISE_NOMINAL" ;
VAL_ 782 PARK_sdiBlindSpotRight 3 "SNA" 2 "UNUSED" 1 "WARNING" 0 "NO_WARNING" ;
VAL_ 782 PARK_sdiBlindSpotLeft 3 "SNA" 2 "UNUSED" 1 "WARNING" 0 "NO_WARNING" ;
VAL_ 1329 RADC_infoIndex 255 "INFO_END" 20 "INFO_UDS_PROTOCOL_BOOTCRC" 19 "INFO_VERSION_DEPRECATED" 18 "INFO_BOOTLOADER_GITHASH" 17 "INFO_APP_GITHASH" 16 "INFO_SUBCOMPONENT" 15 "INFO_BOOTLOADER_CRC" 14 "INFO_BOOTLOADER_SVN" 13 "INFO_APP_CRC" 11 "INFO_PCBAID_ASSYID_USAGEID" 10 "INFO_BUILD_HWID_COMPONENTID" 9 "INFO_DEPRECATED_9" 8 "INFO_DEPRECATED_8" 7 "INFO_DEPRECATED_7" 6 "INFO_DEPRECATED_6" 5 "INFO_DEPRECATED_5" 4 "INFO_DEPRECATED_4" 3 "INFO_DEPRECATED_3" 2 "INFO_DEPRECATED_2" 1 "INFO_DEPRECATED_1" 0 "INFO_DEPRECATED_0" ;
VAL_ 17 RCM_rearCrash 2 "RCM_CRASH_EVENT_UNUSED" 1 "RCM_CRASH_EVENT_ACTIVE" 0 "RCM_CRASH_EVENT_INACTIVE" ;
VAL_ 17 RCM_rightSideCrash 2 "RCM_CRASH_EVENT_UNUSED" 1 "RCM_CRASH_EVENT_ACTIVE" 0 "RCM_CRASH_EVENT_INACTIVE" ;
VAL_ 17 RCM_leftSideCrash 2 "RCM_CRASH_EVENT_UNUSED" 1 "RCM_CRASH_EVENT_ACTIVE" 0 "RCM_CRASH_EVENT_INACTIVE" ;
VAL_ 17 RCM_frontCrash 2 "RCM_CRASH_EVENT_UNUSED" 1 "RCM_CRASH_EVENT_ACTIVE" 0 "RCM_CRASH_EVENT_INACTIVE" ;
VAL_ 17 RCM_chargerCrash 2 "RCM_CRASH_EVENT_UNUSED" 1 "RCM_CRASH_EVENT_ACTIVE" 0 "RCM_CRASH_EVENT_INACTIVE" ;
VAL_ 17 RCM_pedProEvent 2 "RCM_CRASH_EVENT_UNUSED" 1 "RCM_CRASH_EVENT_ACTIVE" 0 "RCM_CRASH_EVENT_INACTIVE" ;
VAL_ 17 RCM_rollOverCrash 2 "RCM_CRASH_EVENT_UNUSED" 1 "RCM_CRASH_EVENT_ACTIVE" 0 "RCM_CRASH_EVENT_INACTIVE" ;
VAL_ 273 RCM_ndRearCollision 2 "RCM_NEAR_DEPLOY_EVENT_UNUSED" 1 "RCM_NEAR_DEPLOY_EVENT_ACTIVE" 0 "RCM_NEAR_DEPLOY_EVENT_INACTIVE" ;
VAL_ 273 RCM_ndRightSideCollision 2 "RCM_NEAR_DEPLOY_EVENT_UNUSED" 1 "RCM_NEAR_DEPLOY_EVENT_ACTIVE" 0 "RCM_NEAR_DEPLOY_EVENT_INACTIVE" ;
VAL_ 273 RCM_ndLeftSideCollision 2 "RCM_NEAR_DEPLOY_EVENT_UNUSED" 1 "RCM_NEAR_DEPLOY_EVENT_ACTIVE" 0 "RCM_NEAR_DEPLOY_EVENT_INACTIVE" ;
VAL_ 273 RCM_ndFrontCollision 2 "RCM_NEAR_DEPLOY_EVENT_UNUSED" 1 "RCM_NEAR_DEPLOY_EVENT_ACTIVE" 0 "RCM_NEAR_DEPLOY_EVENT_INACTIVE" ;
VAL_ 273 RCM_ndPedProEvent 2 "RCM_NEAR_DEPLOY_EVENT_UNUSED" 1 "RCM_NEAR_DEPLOY_EVENT_ACTIVE" 0 "RCM_NEAR_DEPLOY_EVENT_INACTIVE" ;
VAL_ 273 RCM_ndRollOverCollision 2 "RCM_NEAR_DEPLOY_EVENT_UNUSED" 1 "RCM_NEAR_DEPLOY_EVENT_ACTIVE" 0 "RCM_NEAR_DEPLOY_EVENT_INACTIVE" ;
VAL_ 529 RCM_tellTalePassengerState 3 "SNA" 2 "FLASHING" 1 "ON" 0 "OFF" ;
VAL_ 529 RCM_buckleDriverStatus 3 "SNA" 2 "FAULTED" 1 "BUCKLE_LATCHED" 0 "BUCKLE_UNLATCHED" ;
VAL_ 109 TSL_P_Psd_StW 3 "SNA" 2 "INI" 1 "PSD" 0 "IDLE" ;
VAL_ 69 SpdCtrlLvr_Stat 32 "DN_1ST" 16 "UP_1ST" 8 "DN_2ND" 4 "UP_2ND" 2 "RWD" 1 "FWD" 0 "IDLE" ;
VAL_ 69 DTR_Dist_Rq 255 "SNA" 200 "ACC_DIST_7" 166 "ACC_DIST_6" 133 "ACC_DIST_5" 100 "ACC_DIST_4" 66 "ACC_DIST_3" 33 "ACC_DIST_2" 0 "ACC_DIST_1" ;
VAL_ 69 TurnIndLvr_Stat 3 "SNA" 2 "RIGHT" 1 "LEFT" 0 "IDLE" ;
VAL_ 69 HiBmLvr_Stat 3 "SNA" 2 "HIBM_FLSH_ON_PSD" 1 "HIBM_ON_PSD" 0 "IDLE" ;
VAL_ 69 WprWashSw_Psd 3 "SNA" 2 "WASH" 1 "TIPWIPE" 0 "NPSD" ;
VAL_ 14 StW_AnglHP 16383 "SNA" ;
VAL_ 14 StW_AnglHP_Spd 16383 "SNA" ;
VAL_ 14 StW_AnglHP_Sens_Stat 3 "SNA" 2 "ERR" 1 "INI" 0 "OK" ;
VAL_ 539 TAS_currentLevel 7 "VERY_LOW_LEVEL" 6 "VERY_HIGH_LEVEL" 5 "HIGH_LEVEL" 4 "STANDARD_LEVEL" 3 "LOW_LEVEL" 2 "NOT_DEFINED_2" 1 "NOT_DEFINED_1" 0 "NOT_DEFINED_0" ;
